VERSION ""

NS_ :

BS_:

BU_:

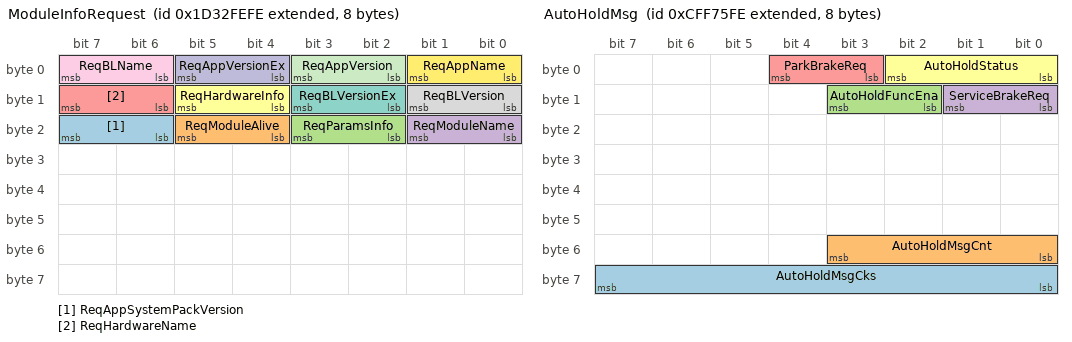
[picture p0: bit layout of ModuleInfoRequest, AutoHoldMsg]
BO_ 2637364990 ModuleInfoRequest: 8 Host
 SG_ ReqAppSystemPackVersion : 22|2@1+ (1,0) [0|0] "" Vector__XXX
 SG_ ReqModuleAlive : 20|2@1+ (1,0) [0|0] "" Vector__XXX
 SG_ ReqParamsInfo : 18|2@1+ (1,0) [0|0] "" Vector__XXX
 SG_ ReqModuleName : 16|2@1+ (1,0) [0|0] "" Vector__XXX
 SG_ ReqHardwareName : 14|2@1+ (1,0) [0|0] "" Vector__XXX
 SG_ ReqHardwareInfo : 12|2@1+ (1,0) [0|0] "" Vector__XXX
 SG_ ReqBLVersionEx : 10|2@1+ (1,0) [0|0] "" Vector__XXX
 SG_ ReqBLVersion : 8|2@1+ (1,0) [0|0] "" Vector__XXX
 SG_ ReqBLName : 6|2@1+ (1,0) [0|0] "" Vector__XXX
 SG_ ReqAppVersionEx : 4|2@1+ (1,0) [0|0] "" Vector__XXX
 SG_ ReqAppVersion : 2|2@1+ (1,0) [0|0] "" Vector__XXX
 SG_ ReqAppName : 0|2@1+ (1,0) [0|0] "" Vector__XXX

BO_ 2583174654 WPRWSH_WiperFeedback: 1 Vector__XXX
 SG_ WiperState : 1|3@1+ (1,0) [0|7] "" Vector__XXX
 SG_ WiperHomePosition : 0|1@1+ (1,0) [0|1] "" Vector__XXX

BO_ 2365552126 AutoHoldMsg: 8 Vector__XXX
 SG_ AutoHoldMsgCks : 56|8@1+ (1,0) [0|255] "" Vector__XXX
 SG_ AutoHoldMsgCnt : 48|4@1+ (1,0) [0|15] "" Vector__XXX
 SG_ AutoHoldFuncEna : 10|2@1+ (1,0) [0|3] "" Vector__XXX
 SG_ ServiceBrakeReq : 8|2@1+ (1,0) [0|3] "" Vector__XXX
 SG_ ParkBrakeReq : 3|2@1+ (1,0) [0|3] "" Vector__XXX
 SG_ AutoHoldStatus : 0|3@1+ (1,0) [0|4] "" Vector__XXX

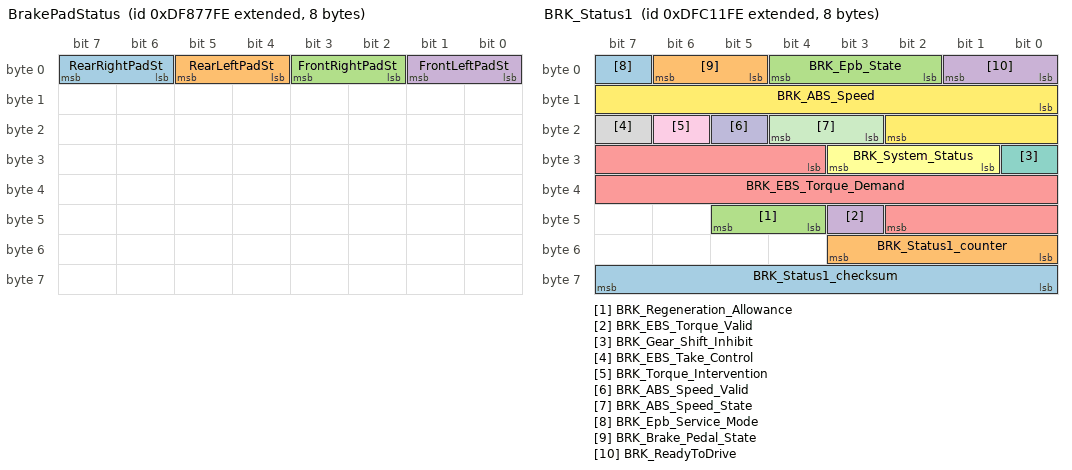
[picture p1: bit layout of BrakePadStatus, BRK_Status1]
BO_ 2381871102 BrakePadStatus: 8 Vector__XXX
 SG_ RearRightPadSt : 6|2@1+ (1,0) [0|3] "" Vector__XXX
 SG_ RearLeftPadSt : 4|2@1+ (1,0) [0|3] "" Vector__XXX
 SG_ FrontRightPadSt : 2|2@1+ (1,0) [0|3] "" Vector__XXX
 SG_ FrontLeftPadSt : 0|2@1+ (1,0) [0|3] "" Vector__XXX

BO_ 2382107134 BRK_Status1: 8 Vector__XXX
 SG_ BRK_Status1_checksum : 56|8@1+ (1,0) [0|255] "" Vector__XXX
 SG_ BRK_Status1_counter : 48|4@1+ (1,0) [0|15] "" Vector__XXX
 SG_ BRK_Regeneration_Allowance : 44|2@1+ (1,0) [0|3] "" Vector__XXX
 SG_ BRK_EBS_Torque_Valid : 43|1@1+ (1,0) [0|0] "" Vector__XXX
 SG_ BRK_EBS_Torque_Demand : 28|15@1+ (0.1,0) [0|3276.7] "N*m" Vector__XXX
 SG_ BRK_System_Status : 25|3@1+ (1,0) [0|7] "" Vector__XXX
 SG_ BRK_Gear_Shift_Inhibit : 24|1@1+ (1,0) [0|1] "" Vector__XXX
 SG_ BRK_EBS_Take_Control : 23|1@1+ (1,0) [0|1] "" Vector__XXX
 SG_ BRK_Torque_Intervention : 22|1@1+ (1,0) [0|1] "" Vector__XXX
 SG_ BRK_ABS_Speed_Valid : 21|1@1+ (1,0) [0|1] "" Vector__XXX
 SG_ BRK_ABS_Speed_State : 19|2@1+ (1,0) [0|3] "" Vector__XXX
 SG_ BRK_ABS_Speed : 8|11@1+ (0.125,0) [0|255] "kph" Vector__XXX
 SG_ BRK_Epb_Service_Mode : 7|1@1+ (1,0) [0|1] "" Vector__XXX
 SG_ BRK_Brake_Pedal_State : 5|2@1+ (1,0) [0|3] "" Vector__XXX
 SG_ BRK_Epb_State : 2|3@1+ (1,0) [0|7] "" Vector__XXX
 SG_ BRK_ReadyToDrive : 0|2@1+ (1,0) [0|3] "" Vector__XXX

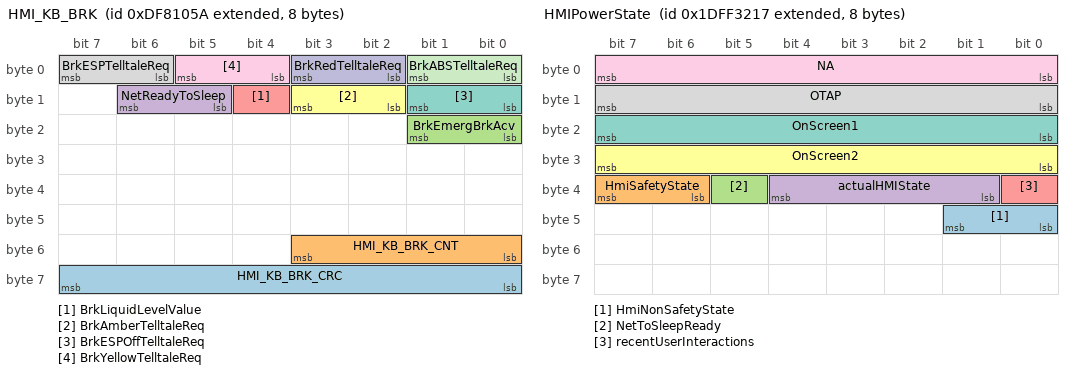
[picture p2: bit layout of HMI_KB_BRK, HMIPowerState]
BO_ 2381844570 HMI_KB_BRK: 8 Vector__XXX
 SG_ HMI_KB_BRK_CRC : 56|8@1+ (1,0) [0|255] "" Vector__XXX
 SG_ HMI_KB_BRK_CNT : 48|4@1+ (1,0) [0|15] "" Vector__XXX
 SG_ BrkEmergBrkAcv : 16|2@1+ (1,0) [0|3] "" Vector__XXX
 SG_ NetReadyToSleep : 13|2@1+ (1,0) [0|3] "" Vector__XXX
 SG_ BrkLiquidLevelValue : 12|1@1+ (1,0) [0|1] "" Vector__XXX
 SG_ BrkAmberTelltaleReq : 10|2@1+ (1,0) [0|0] "" Vector__XXX
 SG_ BrkESPOffTelltaleReq : 8|2@1+ (1,0) [0|0] "" Vector__XXX
 SG_ BrkESPTelltaleReq : 6|2@1+ (1,0) [0|0] "" Vector__XXX
 SG_ BrkYellowTelltaleReq : 4|2@1+ (1,0) [0|0] "" Vector__XXX
 SG_ BrkRedTelltaleReq : 2|2@1+ (1,0) [0|0] "" Vector__XXX
 SG_ BrkABSTelltaleReq : 0|2@1+ (1,0) [0|0] "" Vector__XXX

BO_ 2650747415 HMIPowerState: 8 InstrumentalCluster
 SG_ HmiNonSafetyState : 40|2@1+ (1,0) [0|3] "" Vector__XXX
 SG_ HmiSafetyState : 38|2@1+ (1,0) [0|3] "" Vector__XXX
 SG_ NetToSleepReady : 37|1@1+ (1,0) [0|1] "" Vector__XXX
 SG_ actualHMIState : 33|4@1+ (1,0) [0|15] "" Vector__XXX
 SG_ recentUserInteractions : 32|1@1+ (1,0) [0|1] "" Vector__XXX
 SG_ OnScreen2 : 24|8@1+ (1,0) [0|1] "" Vector__XXX
 SG_ OnScreen1 : 16|8@1+ (1,0) [0|1] "" Vector__XXX
 SG_ OTAP : 8|8@1+ (1,0) [0|1] "" Vector__XXX
 SG_ NA : 0|8@1+ (1,0) [0|1] "" Vector__XXX

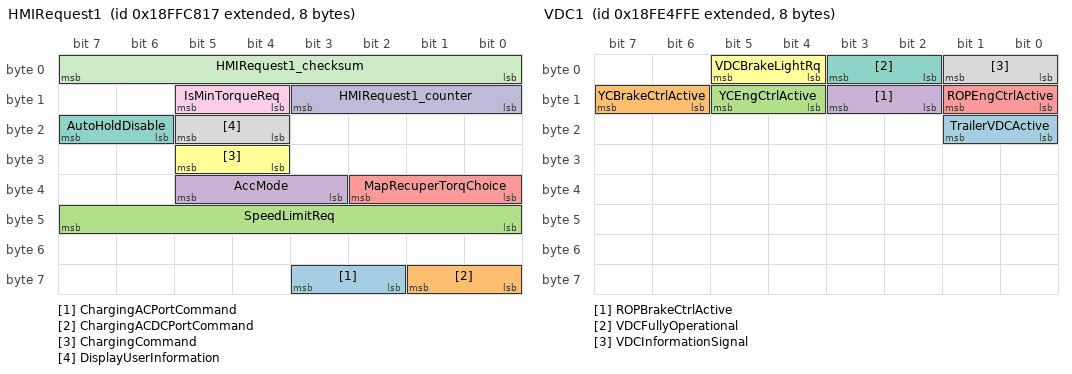
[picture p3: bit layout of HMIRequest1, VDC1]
BO_ 2566899735 HMIRequest1: 8 InstrumentCluster
 SG_ ChargingACPortCommand : 58|2@1+ (1,0) [0|3] "" Vector__XXX
 SG_ ChargingACDCPortCommand : 56|2@1+ (1,0) [0|3] "" Vector__XXX
 SG_ SpeedLimitReq : 40|8@1+ (1,0) [0|0] "kph" Vector__XXX
 SG_ AccMode : 35|3@1+ (1,0) [0|7] "" Vector__XXX
 SG_ MapRecuperTorqChoice : 32|3@1+ (1,0) [0|0] "" Vector__XXX
 SG_ ChargingCommand : 28|2@1+ (1,0) [0|3] "" Vector__XXX
 SG_ AutoHoldDisable : 22|2@1+ (1,0) [0|3] "" Vector__XXX
 SG_ DisplayUserInformation : 20|2@1+ (1,0) [0|3] "" Vector__XXX
 SG_ IsMinTorqueReq : 12|2@1+ (1,0) [0|3] "" Vector__XXX
 SG_ HMIRequest1_counter : 8|4@1+ (1,0) [0|14] "" Vector__XXX
 SG_ HMIRequest1_checksum : 0|8@1+ (1,0) [0|255] "" Vector__XXX

BO_ 2566803454 VDC1: 8 Vector__XXX
 SG_ TrailerVDCActive : 16|2@1+ (1,0) [0|3] "" Vector__XXX
 SG_ YCBrakeCtrlActive : 14|2@1+ (1,0) [0|3] "" Vector__XXX
 SG_ YCEngCtrlActive : 12|2@1+ (1,0) [0|3] "" Vector__XXX
 SG_ ROPBrakeCtrlActive : 10|2@1+ (1,0) [0|3] "" Vector__XXX
 SG_ ROPEngCtrlActive : 8|2@1+ (1,0) [0|3] "" Vector__XXX
 SG_ VDCBrakeLightRq : 4|2@1+ (1,0) [0|3] "" Vector__XXX
 SG_ VDCFullyOperational : 2|2@1+ (1,0) [0|3] "" Vector__XXX
 SG_ VDCInformationSignal : 0|2@1+ (1,0) [0|3] "" Vector__XXX

BO_ 2399125758 CommVSMRequest: 8 Vector__XXX
 SG_ LVUpdateOTARequest : 6|3@1+ (1,0) [0|7] "" Vector__XXX
 SG_ OTAUpdateRequest : 3|3@1+ (1,0) [0|7] "" Vector__XXX
 SG_ DiagnosticRequest : 0|3@1+ (1,0) [0|7] "" Vector__XXX

BO_ 2381722110 ELSTS: 1 Vector__XXX
 SG_ ELSReadyToSleep : 3|2@1+ (1,0) [0|3] "" Vector__XXX
 SG_ LampState : 0|3@1+ (1,0) [0|7] "" Vector__XXX

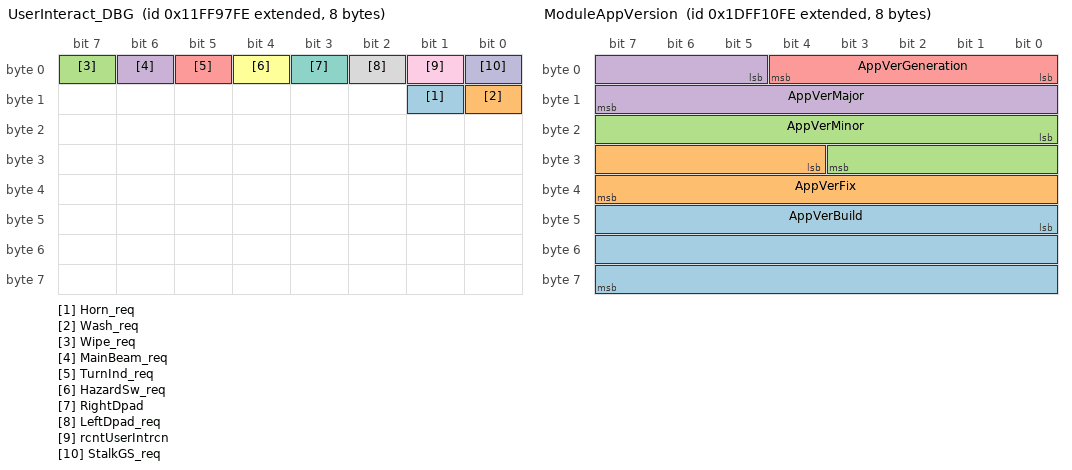
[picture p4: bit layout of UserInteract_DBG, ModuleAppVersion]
BO_ 2449446910 UserInteract_DBG: 8 Vector__XXX
 SG_ Horn_req : 9|1@1+ (1,0) [0|1] "" Vector__XXX
 SG_ Wash_req : 8|1@1+ (1,0) [0|1] "" Vector__XXX
 SG_ Wipe_req : 7|1@1+ (1,0) [0|1] "" Vector__XXX
 SG_ MainBeam_req : 6|1@1+ (1,0) [0|1] "" Vector__XXX
 SG_ TurnInd_req : 5|1@1+ (1,0) [0|1] "" Vector__XXX
 SG_ HazardSw_req : 4|1@1+ (1,0) [0|1] "" Vector__XXX
 SG_ RightDpad : 3|1@1+ (1,0) [0|1] "" Vector__XXX
 SG_ LeftDpad_req : 2|1@1+ (1,0) [0|1] "" Vector__XXX
 SG_ rcntUserIntrcn : 1|1@1+ (1,0) [0|1] "" Vector__XXX
 SG_ StalkGS_req : 0|1@1+ (1,0) [0|1] "" Vector__XXX

BO_ 2650738942 ModuleAppVersion: 8 Device
 SG_ AppVerBuild : 40|24@1+ (1,0) [0|16777215] "" Vector__XXX
 SG_ AppVerFix : 28|12@1+ (1,0) [0|4090] "" Vector__XXX
 SG_ AppVerMinor : 16|12@1+ (1,0) [0|4095] "" Vector__XXX
 SG_ AppVerMajor : 5|11@1+ (1,0) [0|2047] "" Vector__XXX
 SG_ AppVerGeneration : 0|5@1+ (1,0) [0|31] "" Vector__XXX

BO_ 2466225918 HMIUserInteract: 8 Vector__XXX
 SG_ RecentUserInteract : 0|1@1+ (1,0) [0|1] "" Vector__XXX

BO_ 2600457470 NM_DEBUG_OUT_1: 8 Vector__XXX
 SG_ NM_Wakeup_Sys22 : 40|1@1+ (1,0) [0|1] "" Vector__XXX
 SG_ NM_Wakeup_Sys21 : 39|1@1+ (1,0) [0|1] "" Vector__XXX
 SG_ NM_Wakeup_Sys14 : 38|1@1+ (1,0) [0|1] "" Vector__XXX
 SG_ NM_Wakeup_Sys12 : 37|1@1+ (1,0) [0|1] "" Vector__XXX
 SG_ NM_Wakeup_Sys7 : 36|1@1+ (1,0) [0|1] "" Vector__XXX
 SG_ NM_Wakeup_Sys6 : 35|1@1+ (1,0) [0|1] "" Vector__XXX
 SG_ NM_Wakeup_Sys5 : 34|1@1+ (1,0) [0|1] "" Vector__XXX
 SG_ NM_Wakeup_Sys3 : 33|1@1+ (1,0) [0|1] "" Vector__XXX
 SG_ NM_Wakeup_Sys1 : 32|1@1+ (1,0) [0|1] "" Vector__XXX
 SG_ NM_Ready2Sleep_Sys15 : 30|1@1+ (1,0) [0|1] "" Vector__XXX
 SG_ NM_Ready2Sleep_Sys14 : 29|1@1+ (1,0) [0|1] "" Vector__XXX
 SG_ NM_Ready2Sleep_Sys13 : 28|1@1+ (1,0) [0|1] "" Vector__XXX
 SG_ NM_Ready2Sleep_Sys12 : 27|1@1+ (1,0) [0|1] "" Vector__XXX
 SG_ NM_Ready2Sleep_Sys11 : 26|1@1+ (1,0) [0|1] "" Vector__XXX
 SG_ NM_Ready2Sleep_Sys10 : 25|1@1+ (1,0) [0|1] "" Vector__XXX
 SG_ NM_Ready2Sleep_Sys9 : 24|1@1+ (1,0) [0|1] "" Vector__XXX
 SG_ NM_Ready2Sleep_Sys8 : 23|1@1+ (1,0) [0|1] "" Vector__XXX
 SG_ NM_Ready2Sleep_Sys7 : 22|1@1+ (1,0) [0|1] "" Vector__XXX
 SG_ NM_Ready2Sleep_Sys6 : 21|1@1+ (1,0) [0|1] "" Vector__XXX
 SG_ NM_Ready2Sleep_Sys5 : 20|1@1+ (1,0) [0|1] "" Vector__XXX
 SG_ NM_Ready2Sleep_Sys4 : 19|1@1+ (1,0) [0|1] "" Vector__XXX
 SG_ NM_Ready2Sleep_Sys3 : 18|1@1+ (1,0) [0|1] "" Vector__XXX
 SG_ NM_Ready2Sleep_Sys2 : 17|1@1+ (1,0) [0|1] "" Vector__XXX
 SG_ NM_Ready2Sleep_Sys1 : 16|1@1+ (1,0) [0|1] "" Vector__XXX
 SG_ NM_VSMFullySleep : 13|1@1+ (1,0) [0|1] "" Vector__XXX
 SG_ NM_MNG_ShtDwnTimer : 12|1@1+ (1,0) [0|1] "" Vector__XXX
 SG_ NM_MNG_ShtDwnSysRdy : 11|1@1+ (1,0) [0|1] "" Vector__XXX
 SG_ NM_IsSpdOk : 10|1@1+ (1,0) [0|0] "" Vector__XXX
 SG_ NM_IsHWOk : 9|1@1+ (1,0) [0|0] "" Vector__XXX
 SG_ NM_Ready2Sleep_Inv : 8|1@1+ (1,0) [0|1] "" Vector__XXX
 SG_ NM_BoardShutDown : 7|1@1+ (1,0) [0|0] "" Vector__XXX
 SG_ NM_NTWKTaskStatus : 5|2@1+ (1,0) [0|0] "" Vector__XXX
 SG_ NM_SlaveSleepCmd : 4|1@1+ (1,0) [0|0] "" Vector__XXX
 SG_ NM_SlaveWakeupCmd : 3|1@1+ (1,0) [0|0] "" Vector__XXX
 SG_ NM_SleepCmd_BMS : 2|1@1+ (1,0) [0|0] "" Vector__XXX
 SG_ NM_MNGR_VSMNtwkReq : 0|2@1+ (1,0) [0|3] "" Vector__XXX

BO_ 2600457726 NM_DEBUG_OUT_2: 8 Vector__XXX
 SG_ NM_SlaveWakeUpCmd_RRIO2 : 56|1@1+ (1,0) [0|1] "" Vector__XXX
 SG_ NM_SlaveWakeUpCmd_RRIO1 : 55|1@1+ (1,0) [0|1] "" Vector__XXX
 SG_ NM_SlaveWakeUpCmd_CBIO3 : 54|1@1+ (1,0) [0|1] "" Vector__XXX
 SG_ NM_SlaveWakeUpCmd_CBIO2 : 53|1@1+ (1,0) [0|1] "" Vector__XXX
 SG_ NM_SlaveWakeUpCmd_CBIO1 : 52|1@1+ (1,0) [0|1] "" Vector__XXX
 SG_ NM_SlaveWakeUpCmd_FBIO4 : 51|1@1+ (1,0) [0|1] "" Vector__XXX
 SG_ NM_SlaveWakeUpCmd_FBIO2 : 50|1@1+ (1,0) [0|1] "" Vector__XXX
 SG_ NM_SlaveWakeUpCmd_FBIO1 : 49|1@1+ (1,0) [0|1] "" Vector__XXX
 SG_ NM_SlaveWakeUpCmd_BMS : 48|1@1+ (1,0) [0|1] "" Vector__XXX
 SG_ NM_SlaveWakeUpCmd_COMM : 47|1@1+ (1,0) [0|1] "" Vector__XXX
 SG_ NM_SlaveWakeUpCmd_ARVLCC : 46|1@1+ (1,0) [0|1] "" Vector__XXX
 SG_ NM_SlaveWakeUpCmd_STPCSD : 45|1@1+ (1,0) [0|1] "" Vector__XXX
 SG_ NM_SlaveWakeUpCmd_STPCBD : 44|1@1+ (1,0) [0|1] "" Vector__XXX
 SG_ NM_SlaveWakeUpCmd_STPRD : 43|1@1+ (1,0) [0|1] "" Vector__XXX
 SG_ NM_SlaveWakeUpCmd_STPLD : 42|1@1+ (1,0) [0|1] "" Vector__XXX
 SG_ NM_SlaveWakeUpCmd_AVAS : 41|1@1+ (1,0) [0|1] "" Vector__XXX
 SG_ NM_SlaveWakeUpCmd_FBIO3 : 40|1@1+ (1,0) [0|1] "" Vector__XXX
 SG_ NM_SlaveWakeUpCmd_HMI : 39|1@1+ (1,0) [0|1] "" Vector__XXX
 SG_ NM_SlaveWakeUpCmd_IDU : 38|1@1+ (1,0) [0|1] "" Vector__XXX
 SG_ NM_SlaveSleepCmd_RRIO2 : 37|1@1+ (1,0) [0|1] "" Vector__XXX
 SG_ NM_SlaveSleepCmd_RRIO1 : 36|1@1+ (1,0) [0|1] "" Vector__XXX
 SG_ NM_SlaveSleepCmd_CBIO3 : 35|1@1+ (1,0) [0|1] "" Vector__XXX
 SG_ NM_SlaveSleepCmd_CBIO2 : 34|1@1+ (1,0) [0|1] "" Vector__XXX
 SG_ NM_SlaveSleepCmd_CBIO1 : 33|1@1+ (1,0) [0|1] "" Vector__XXX
 SG_ NM_SlaveSleepCmd_FBIO4 : 32|1@1+ (1,0) [0|1] "" Vector__XXX
 SG_ NM_SlaveSleepCmd_FBIO2 : 31|1@1+ (1,0) [0|1] "" Vector__XXX
 SG_ NM_SlaveSleepCmd_FBIO1 : 30|1@1+ (1,0) [0|1] "" Vector__XXX
 SG_ NM_SlaveSleepCmd_BMS : 29|1@1+ (1,0) [0|1] "" Vector__XXX
 SG_ NM_SlaveSleepCmd_COMM : 28|1@1+ (1,0) [0|1] "" Vector__XXX
 SG_ NM_SlaveSleepCmd_ARVLCC : 27|1@1+ (1,0) [0|1] "" Vector__XXX
 SG_ NM_SlaveSleepCmd_STPCSD : 26|1@1+ (1,0) [0|1] "" Vector__XXX
 SG_ NM_SlaveSleepCmd_STPCBD : 25|1@1+ (1,0) [0|1] "" Vector__XXX
 SG_ NM_SlaveSleepCmd_STPRD : 24|1@1+ (1,0) [0|1] "" Vector__XXX
 SG_ NM_SlaveSleepCmd_STPLD : 23|1@1+ (1,0) [0|1] "" Vector__XXX
 SG_ NM_SlaveSleepCmd_AVAS : 22|1@1+ (1,0) [0|1] "" Vector__XXX
 SG_ NM_SlaveSleepCmd_FBIO3 : 21|1@1+ (1,0) [0|1] "" Vector__XXX
 SG_ NM_SlaveSleepCmd_HMI : 20|1@1+ (1,0) [0|1] "" Vector__XXX
 SG_ NM_SlaveSleepCmd_IDU : 19|1@1+ (1,0) [0|1] "" Vector__XXX
 SG_ NM_NodesAlive_RRIO2 : 18|1@1+ (1,0) [0|1] "" Vector__XXX
 SG_ NM_NodesAlive_RRIO1 : 17|1@1+ (1,0) [0|1] "" Vector__XXX
 SG_ NM_NodesAlive_CBIO3 : 16|1@1+ (1,0) [0|1] "" Vector__XXX
 SG_ NM_NodesAlive_CBIO2 : 15|1@1+ (1,0) [0|1] "" Vector__XXX
 SG_ NM_NodesAlive_CBIO1 : 14|1@1+ (1,0) [0|1] "" Vector__XXX
 SG_ NM_NodesAlive_FBIO4 : 13|1@1+ (1,0) [0|1] "" Vector__XXX
 SG_ NM_NodesAlive_FBIO2 : 12|1@1+ (1,0) [0|1] "" Vector__XXX
 SG_ NM_NodesAlive_FBIO1 : 11|1@1+ (1,0) [0|1] "" Vector__XXX
 SG_ NM_NodesAlive_BMS : 10|1@1+ (1,0) [0|1] "" Vector__XXX
 SG_ NM_NodesAlive_COMM : 9|1@1+ (1,0) [0|1] "" Vector__XXX
 SG_ NM_NodesAlive_ARVLCC : 8|1@1+ (1,0) [0|1] "" Vector__XXX
 SG_ NM_NodesAlive_STPCSD : 7|1@1+ (1,0) [0|1] "" Vector__XXX
 SG_ NM_NodesAlive_STPCBD : 6|1@1+ (1,0) [0|1] "" Vector__XXX
 SG_ NM_NodesAlive_STPRD : 5|1@1+ (1,0) [0|1] "" Vector__XXX
 SG_ NM_NodesAlive_STPLD : 4|1@1+ (1,0) [0|1] "" Vector__XXX
 SG_ NM_NodesAlive_AVAS : 3|1@1+ (1,0) [0|1] "" Vector__XXX
 SG_ NM_NodesAlive_FBIO3 : 2|1@1+ (1,0) [0|1] "" Vector__XXX
 SG_ NM_NodesAlive_HMI : 1|1@1+ (1,0) [0|1] "" Vector__XXX
 SG_ NM_NodesAlive_IDU : 0|1@1+ (1,0) [0|1] "" Vector__XXX

BO_ 2600457982 NM_DEBUG_OUT_3: 8 Vector__XXX
 SG_ NM_DBG_VehSpeed : 8|32@1+ (1,0) [0|4294967295] "" Vector__XXX
 SG_ NM_DBG_VSMSubstate : 3|3@1+ (1,0) [0|7] "" Vector__XXX
 SG_ NM_DBG_VSMState : 0|3@1+ (1,0) [0|7] "" Vector__XXX

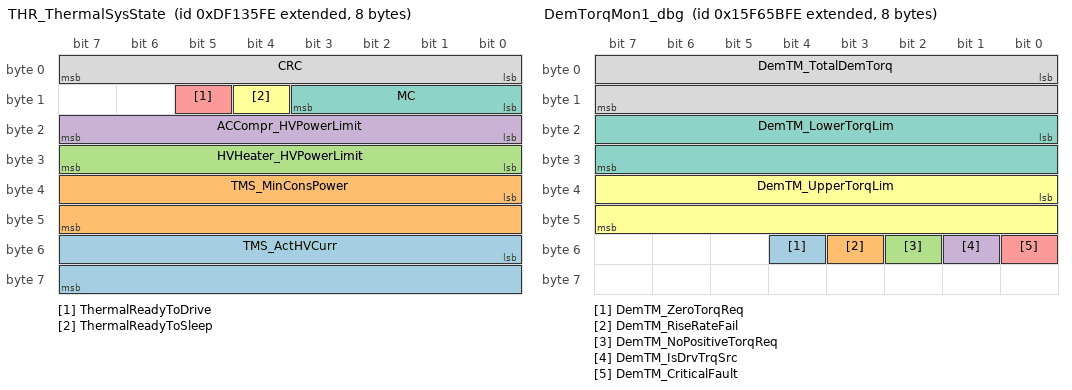
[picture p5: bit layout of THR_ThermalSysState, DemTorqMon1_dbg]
BO_ 2381395454 THR_ThermalSysState: 8 Vector__XXX
 SG_ TMS_ActHVCurr : 48|16@1+ (0.05,0) [0|3276.75] "A" Vector__XXX
 SG_ TMS_MinConsPower : 32|16@1+ (0.1,0) [0|6553.5] "kW" Vector__XXX
 SG_ HVHeater_HVPowerLimit : 24|8@1+ (0.1,0) [0|25.5] "kW" Vector__XXX
 SG_ ACCompr_HVPowerLimit : 16|8@1+ (0.1,0) [0|25.5] "kW" Vector__XXX
 SG_ ThermalReadyToDrive : 13|1@1+ (1,0) [0|1] "" Vector__XXX
 SG_ ThermalReadyToSleep : 12|1@1+ (1,0) [0|1] "" Vector__XXX
 SG_ MC : 8|4@1+ (1,0) [0|0] "" Vector__XXX
 SG_ CRC : 0|8@1+ (1,0) [0|0] "" Vector__XXX

BO_ 2650742782 MaintenanceStatus: 8 Host
 SG_ DiagReportsEnabled : 2|2@1+ (1,0) [0|0] "" Vector__XXX
 SG_ FirmwareUpdateEnabled : 0|2@1+ (1,0) [0|0] "" Vector__XXX

BO_ 2600459518 VSM_DEBUG_OUT_2: 8 Vector__XXX
 SG_ VSM_OTA_Step : 0|5@1+ (1,1) [1|32] "" Vector__XXX

BO_ 2515951358 ActTorqMon1_dbg: 8 Vector__XXX
 SG_ ActTM_UpperTorqLim : 48|16@1+ (1,-32267) [-32267|33268] "" Vector__XXX
 SG_ ActTM_LowerTorqLim : 32|16@1+ (1,-32267) [-32267|33268] "" Vector__XXX
 SG_ ActTM_DemTorque : 16|16@1+ (1,-32267) [-32267|33268] "" Vector__XXX
 SG_ ActTM_ActTorque : 0|16@1+ (1,-32267) [-32267|33268] "" Vector__XXX

BO_ 2515951102 ActTorqMon2_dbg: 8 Vector__XXX
 SG_ ActTM_ExcTime : 32|16@1+ (1,0) [0|65535] "" Vector__XXX
 SG_ ActTM_FiltTorqRiseRate : 16|16@1+ (1,-32267) [-32267|33268] "" Vector__XXX
 SG_ ActTM_MotSpeedRPM : 0|16@1+ (1,-32267) [-32267|33268] "" Vector__XXX

BO_ 2515950846 BrkTorqMon_dbg: 8 Vector__XXX
 SG_ BrkTM_BrkTorqFault0 : 16|1@1+ (1,0) [0|1] "" Vector__XXX
 SG_ BrkTM_EBSTorqDem : 0|16@1+ (1,-32267) [-32267|33268] "" Vector__XXX

BO_ 2180407550 DCUHMI: 8 Vector__XXX
 SG_ DCUHMIMsgCks : 56|8@1+ (1,0) [0|255] "" Vector__XXX
 SG_ DCUHMIMsgCtr : 48|4@1+ (1,0) [0|15] "" Vector__XXX
 SG_ GearBox_FltSts : 3|2@1+ (1,0) [0|3] "" Vector__XXX
 SG_ DTS_DriverWarn : 0|3@1+ (1,0) [0|7] "" Vector__XXX

BO_ 2515950590 DemTorqMon1_dbg: 8 Vector__XXX
 SG_ DemTM_ZeroTorqReq : 52|1@1+ (1,0) [0|1] "" Vector__XXX
 SG_ DemTM_RiseRateFail : 51|1@1+ (1,0) [0|1] "" Vector__XXX
 SG_ DemTM_NoPositiveTorqReq : 50|1@1+ (1,0) [0|1] "" Vector__XXX
 SG_ DemTM_IsDrvTrqSrc : 49|1@1+ (1,0) [0|1] "" Vector__XXX
 SG_ DemTM_CriticalFault : 48|1@1+ (1,0) [0|1] "" Vector__XXX
 SG_ DemTM_UpperTorqLim : 32|16@1+ (1,-32267) [-32267|33268] "" Vector__XXX
 SG_ DemTM_LowerTorqLim : 16|16@1+ (1,-32267) [-32267|33268] "" Vector__XXX
 SG_ DemTM_TotalDemTorq : 0|16@1+ (1,-32267) [-32267|33268] "" Vector__XXX

BO_ 2515950334 DemTorqMon2_dbg: 8 Vector__XXX
 SG_ DemTM_UpperTorqLim_tab : 16|16@1+ (1,-32267) [-32267|33268] "" Vector__XXX
 SG_ DemTM_LowerTorqLim_tab : 0|16@1+ (1,-32267) [-32267|33268] "" Vector__XXX

BO_ 2515950078 DemTorqMon3_dbg: 8 Vector__XXX
 SG_ DemTM_ExcTime : 32|16@1+ (1,0) [0|65535] "" Vector__XXX
 SG_ DemTM_MaxTorqRiseRate : 16|16@1+ (1,-32267) [-32267|33268] "" Vector__XXX
 SG_ DemTM_FiltTorqRiseRate : 0|16@1+ (1,-32267) [-32267|33268] "" Vector__XXX

BO_ 2381867518 DT_States: 8 Vector__XXX
 SG_ DT_States_checksum : 56|8@1+ (1,0) [0|255] "" Vector__XXX
 SG_ DT_States_counter : 48|4@1+ (1,0) [0|15] "" Vector__XXX
 SG_ DTReadyToSleep : 2|1@1+ (1,0) [0|1] "" Vector__XXX
 SG_ DTReadyToDrive : 0|2@1+ (1,0) [0|3] "" Vector__XXX

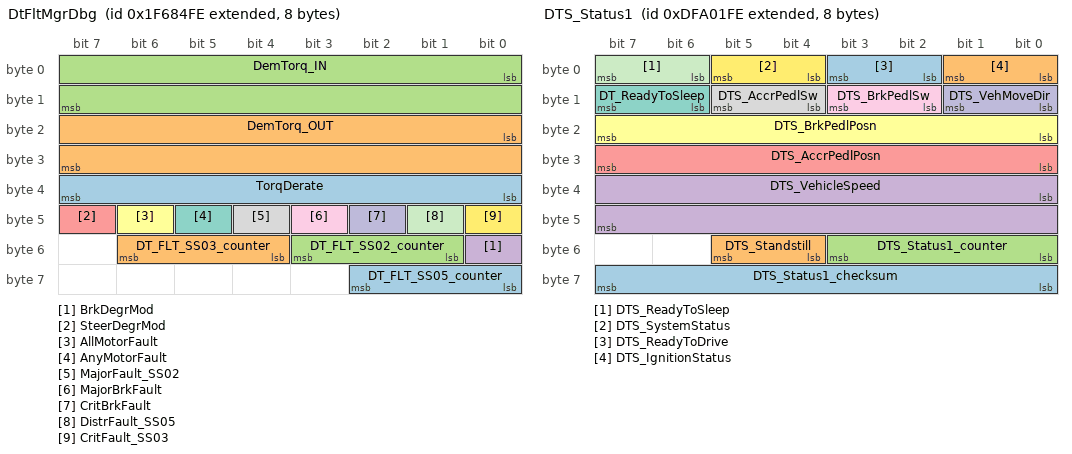
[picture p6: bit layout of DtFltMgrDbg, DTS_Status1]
BO_ 2180416766 DtFltMgrDbg: 8 Vector__XXX
 SG_ DT_FLT_SS05_counter : 56|3@1+ (1,0) [0|7] "" Vector__XXX
 SG_ DT_FLT_SS03_counter : 52|3@1+ (1,0) [0|7] "" Vector__XXX
 SG_ DT_FLT_SS02_counter : 49|3@1+ (1,0) [0|7] "" Vector__XXX
 SG_ BrkDegrMod : 48|1@1+ (1,0) [0|1] "" Vector__XXX
 SG_ SteerDegrMod : 47|1@1+ (1,0) [0|1] "" Vector__XXX
 SG_ AllMotorFault : 46|1@1+ (1,0) [0|1] "" Vector__XXX
 SG_ AnyMotorFault : 45|1@1+ (1,0) [0|1] "" Vector__XXX
 SG_ MajorFault_SS02 : 44|1@1+ (1,0) [0|1] "" Vector__XXX
 SG_ MajorBrkFault : 43|1@1+ (1,0) [0|1] "" Vector__XXX
 SG_ CritBrkFault : 42|1@1+ (1,0) [0|1] "" Vector__XXX
 SG_ DistrFault_SS05 : 41|1@1+ (1,0) [0|1] "" Vector__XXX
 SG_ CritFault_SS03 : 40|1@1+ (1,0) [0|1] "" Vector__XXX
 SG_ TorqDerate : 32|8@1+ (0.004,0) [0|1.02] "" Vector__XXX
 SG_ DemTorq_OUT : 16|16@1+ (1,-32768) [-32768|32767] "" Vector__XXX
 SG_ DemTorq_IN : 0|16@1+ (1,-32768) [-32768|32767] "" Vector__XXX

BO_ 2381971966 DTS_Status1: 8 Vector__XXX
 SG_ DTS_Status1_checksum : 56|8@1+ (1,0) [0|255] "" Vector__XXX
 SG_ DTS_Standstill : 52|2@1+ (1,0) [0|3] "" Vector__XXX
 SG_ DTS_Status1_counter : 48|4@1+ (1,0) [0|15] "" Vector__XXX
 SG_ DTS_VehicleSpeed : 32|16@1+ (0.01,-300) [-300|355.35] "km/h" Vector__XXX
 SG_ DTS_AccrPedlPosn : 24|8@1+ (0.4,0) [0|102] "%" Vector__XXX
 SG_ DTS_BrkPedlPosn : 16|8@1+ (0.5,0) [0|127.5] "%" Vector__XXX
 SG_ DT_ReadyToSleep : 14|2@1+ (1,0) [0|3] "" Vector__XXX
 SG_ DTS_AccrPedlSw : 12|2@1+ (1,0) [0|3] "" Vector__XXX
 SG_ DTS_BrkPedlSw : 10|2@1+ (1,0) [0|3] "" Vector__XXX
 SG_ DTS_VehMoveDir : 8|2@1+ (1,0) [0|3] "" Vector__XXX
 SG_ DTS_ReadyToSleep : 6|2@1+ (1,0) [0|3] "" Vector__XXX
 SG_ DTS_SystemStatus : 4|2@1+ (1,0) [0|3] "" Vector__XXX
 SG_ DTS_ReadyToDrive : 2|2@1+ (1,0) [0|3] "" Vector__XXX
 SG_ DTS_IgnitionStatus : 0|2@1+ (1,0) [0|3] "" Vector__XXX

BO_ 2381972734 DTS_Status4: 8 Vector__XXX
 SG_ DTS_Status4_checksum : 56|8@1+ (1,0) [0|255] "" Vector__XXX
 SG_ DTS_Status4_counter : 48|4@1+ (1,0) [0|15] "" Vector__XXX
 SG_ DTS_MotorTorque : 16|16@1+ (0.1,-3276.8) [-3276.8|3276.7] "Nm" Vector__XXX
 SG_ DTS_MotorSpeed : 0|16@1+ (1,-32768) [-32768|32767] "rpm" Vector__XXX

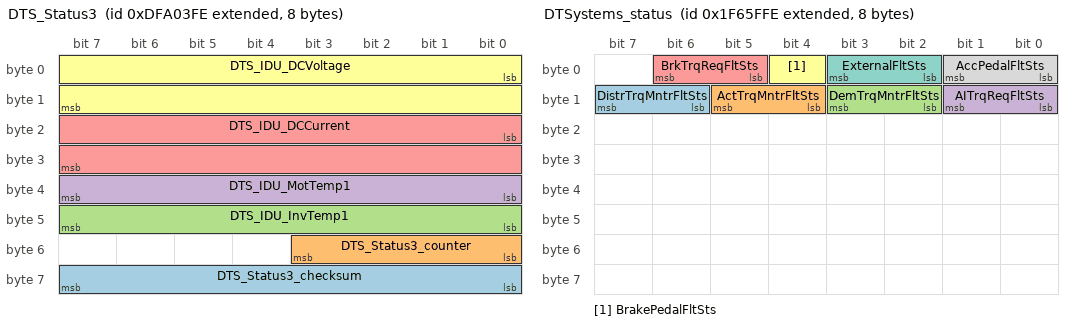
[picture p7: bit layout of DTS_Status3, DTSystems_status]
BO_ 2381972478 DTS_Status3: 8 Vector__XXX
 SG_ DTS_Status3_checksum : 56|8@1+ (1,0) [0|255] "" Vector__XXX
 SG_ DTS_Status3_counter : 48|4@1+ (1,0) [0|15] "" Vector__XXX
 SG_ DTS_IDU_InvTemp1 : 40|8@1+ (1,-40) [-40|215] "degC" Vector__XXX
 SG_ DTS_IDU_MotTemp1 : 32|8@1+ (1,-40) [-40|215] "degC" Vector__XXX
 SG_ DTS_IDU_DCCurrent : 16|16@1+ (0.1,-3276.8) [-3276.8|3276.7] "A" Vector__XXX
 SG_ DTS_IDU_DCVoltage : 0|16@1+ (0.02,0) [0|1310.7] "V" Vector__XXX

BO_ 2381972222 DTS_Status2: 8 Vector__XXX
 SG_ DTS_Status2_checksum : 56|8@1+ (1,0) [0|255] "" Vector__XXX
 SG_ DTS_Status2_counter : 48|4@1+ (1,0) [0|15] "" Vector__XXX
 SG_ DTS_Stalk_Request : 32|2@1+ (1,0) [0|3] "" Vector__XXX
 SG_ DTS_P_Button : 30|2@1+ (1,0) [0|3] "" Vector__XXX
 SG_ DTS_Stalk_GS_Input : 27|3@1+ (1,0) [0|6] "" Vector__XXX
 SG_ DTS_GS_Human_RND_Input : 24|3@1+ (1,0) [0|4] "" Vector__XXX
 SG_ DTS_GS_Human_P_Input : 22|2@1+ (1,0) [0|3] "" Vector__XXX
 SG_ DTS_IDU_DirectionSt : 20|2@1+ (1,0) [0|3] "" Vector__XXX
 SG_ DTS_IDU_DirectionCmd : 18|2@1+ (1,0) [0|3] "" Vector__XXX
 SG_ DTS_IDU_InterlockCmd : 16|2@1+ (1,0) [0|3] "" Vector__XXX
 SG_ DTS_ParkBrakeCmd : 14|2@1+ (1,0) [0|3] "" Vector__XXX
 SG_ DTS_ParkBrakeSt : 11|3@1+ (1,0) [0|7] "" Vector__XXX
 SG_ DTS_IDU_InterlockSt : 8|3@1+ (1,0) [0|7] "" Vector__XXX
 SG_ DTS_IDU_CommStatus : 7|1@1+ (1,0) [0|1] "" Vector__XXX
 SG_ DTS_IDU_ShortCirc : 5|2@1+ (1,0) [0|3] "" Vector__XXX
 SG_ DTS_IDU_HV_CheckState : 4|1@1+ (1,0) [0|1] "" Vector__XXX
 SG_ DTS_SysSt_ParkLock : 2|2@1+ (1,0) [0|3] "" Vector__XXX
 SG_ DTS_SysSt_IDU : 0|2@1+ (1,0) [0|3] "" Vector__XXX

BO_ 2180407294 DTSystems_status: 8 Vector__XXX
 SG_ DistrTrqMntrFltSts : 14|2@1+ (1,0) [0|3] "" Vector__XXX
 SG_ ActTrqMntrFltSts : 12|2@1+ (1,0) [0|3] "" Vector__XXX
 SG_ DemTrqMntrFltSts : 10|2@1+ (1,0) [0|3] "" Vector__XXX
 SG_ AITrqReqFltSts : 8|2@1+ (1,0) [0|3] "" Vector__XXX
 SG_ BrkTrqReqFltSts : 5|2@1+ (1,0) [0|3] "" Vector__XXX
 SG_ BrakePedalFltSts : 4|1@1+ (1,0) [0|1] "" Vector__XXX
 SG_ ExternalFltSts : 2|2@1+ (1,0) [0|3] "" Vector__XXX
 SG_ AccPedalFltSts : 0|2@1+ (1,0) [0|3] "" Vector__XXX

BO_ 2399110910 DVT_Debug_1: 8 Vector__XXX
 SG_ RSPDL_DT_OUT : 48|16@1+ (1,-32768) [-32768|32767] "Nm" Vector__XXX
 SG_ ORTL_DT_OUT : 32|16@1+ (1,-32768) [-32768|32767] "Nm" Vector__XXX
 SG_ DTF_DemTrq_OUT : 16|16@1+ (1,-32768) [-32768|32767] "Nm" Vector__XXX
 SG_ EBS_TorqueRequest : 0|16@1+ (1,-32768) [-32768|32767] "Nm" Vector__XXX

BO_ 2399111166 DVT_Debug_2: 8 Vector__XXX
 SG_ EPLC_ElPwrReqLim : 56|8@1+ (10,0) [0|2550] "kW" Vector__XXX
 SG_ EPLC_ElPwrDischLim : 48|8@1+ (10,0) [0|2550] "kW" Vector__XXX
 SG_ AccTR_TrqDem : 32|16@1+ (1,-32768) [-32768|32767] "N*m" Vector__XXX
 SG_ ARB_DT_DT : 16|16@1+ (1,-32768) [-32768|32767] "Nm" Vector__XXX
 SG_ ARB_DT_AI_TrqDem : 0|16@1- (1,0) [-32768|32767] "" Vector__XXX

BO_ 2399109630 DVT_Debug_3: 8 Vector__XXX
 SG_ DTF_TqLPF_TauTime : 40|8@1+ (0.01,0) [0|2.55] "sec" Vector__XXX
 SG_ DrRA_Acc_Req : 32|8@1+ (1,-100) [-100|100] "%" Vector__XXX
 SG_ DTF_TqRateLimDwn : 24|8@1+ (100,0) [0|25500] "Nm/s" Vector__XXX
 SG_ DTF_TqRateLimUp : 16|8@1+ (100,0) [0|25500] "Nm/s" Vector__XXX
 SG_ RPLIM_T_OUT : 0|16@1+ (1,-32768) [-32768|32767] "Nm" Vector__XXX

BO_ 2600438270 DVT_Diagnostics: 8 DVT_Cntrl
 SG_ DTF_TqLPFIsOn : 41|1@1+ (1,0) [0|0] "" Vector__XXX
 SG_ DTF_TqLimRateIsOn : 40|1@1+ (1,0) [0|0] "" Vector__XXX
 SG_ DTF_DiagWarning : 39|1@1+ (1,0) [0|0] "" Vector__XXX
 SG_ DTF_TqPreprocIsOn : 38|1@1+ (1,0) [0|0] "" Vector__XXX
 SG_ DrRA_MapChoiceFwdProc : 35|3@1+ (1,0) [0|7] "" Vector__XXX
 SG_ DrRA_RecChoiceProc : 32|3@1+ (1,0) [0|7] "" Vector__XXX
 SG_ ARB_DT_isTTAllow : 31|1@1+ (1,0) [0|0] "" Vector__XXX
 SG_ pedalProc_dbg : 28|3@1+ (1,0) [0|0] "" Vector__XXX
 SG_ ARB_DT_isRTAllow : 27|1@1+ (1,0) [0|0] "" Vector__XXX
 SG_ TTDerRPLim : 26|1@1+ (1,0) [0|0] "" Vector__XXX
 SG_ ARB_DT_TrqProhib : 25|1@1+ (1,0) [0|0] "" Vector__XXX
 SG_ TrqProactLim : 24|1@1+ (1,0) [0|0] "" Vector__XXX
 SG_ ARB_DT_isABS_valid : 23|1@1+ (1,0) [0|1] "" Vector__XXX
 SG_ ARB_DT_isABS_active : 22|1@1+ (1,0) [0|1] "" Vector__XXX
 SG_ ARB_DT_CD : 20|2@1+ (1,0) [0|3] "" Vector__XXX
 SG_ DrRA_BrPedState : 18|2@1+ (1,0) [0|3] "" Vector__XXX
 SG_ ARB_CD_blocked : 17|1@1+ (1,0) [0|1] "" Vector__XXX
 SG_ ORTL_ITLimFlag : 16|1@1+ (1,0) [0|1] "" Vector__XXX
 SG_ DT_GearBox_fault_st : 14|2@1+ (1,0) [0|3] "" Vector__XXX
 SG_ DT_system_warn_st : 11|3@1+ (1,0) [0|7] "" Vector__XXX
 SG_ MapChckSt : 9|2@1+ (1,0) [0|0] "" Vector__XXX
 SG_ EBS_SrcValFlag : 8|1@1+ (1,0) [0|0] "" Vector__XXX
 SG_ IntSpdValFlag : 7|1@1+ (1,0) [0|0] "" Vector__XXX
 SG_ DefDistribInUse : 6|1@1+ (1,0) [0|0] "" Vector__XXX
 SG_ CtrlSrcSelBlckd : 5|1@1+ (1,0) [0|0] "" Vector__XXX
 SG_ AccTR_Prms_Incorr : 4|1@1+ (1,0) [0|0] "" Vector__XXX
 SG_ AI_SrcValFlag : 3|1@1+ (1,0) [0|0] "" Vector__XXX
 SG_ DefDistribUnavail : 2|1@1+ (1,0) [0|0] "" Vector__XXX
 SG_ ChosenCtrlSrc : 0|2@1+ (1,0) [0|0] "" Vector__XXX

BO_ 2600439038 DVT_OvrlLim: 8 DVT_Cntrl
 SG_ ProAEPLim_Trq_TrLim : 48|16@1+ (1,0) [0|65535] "" Vector__XXX
 SG_ ProAATLim_Trq_TrLim : 32|16@1+ (1,0) [0|65535] "" Vector__XXX
 SG_ OvrlRTLim : 16|16@1+ (1.5,0) [0|96382] "N*m" Vector__XXX
 SG_ OvrlTTLim : 0|16@1+ (1.5,0) [0|96382] "N*m" Vector__XXX

BO_ 2381399806 DVT_RSPDL_Debug: 8 Vector__XXX
 SG_ RSPDL_Safety_LimitValid : 60|1@1+ (1,0) [0|1] "" Vector__XXX
 SG_ RSPDL_Reverse_LimitValid : 59|1@1+ (1,0) [0|1] "" Vector__XXX
 SG_ RSPDL_LimpMode_LimitValid : 58|1@1+ (1,0) [0|1] "" Vector__XXX
 SG_ LMP_LimpRequest : 57|1@1+ (1,0) [0|1] "" Vector__XXX
 SG_ RSPDL_Internal_LimitValid : 56|1@1+ (1,0) [0|1] "" Vector__XXX
 SG_ LMP_LimpReqSrc7 : 55|1@1+ (1,0) [0|1] "" Vector__XXX
 SG_ RSPDL_HMI_LimitValid : 54|1@1+ (1,0) [0|1] "" Vector__XXX
 SG_ RSPDL_ADAS_LimitValid : 53|1@1+ (1,0) [0|1] "" Vector__XXX
 SG_ LMP_LimpReqSrc6 : 52|1@1+ (1,0) [0|1] "" Vector__XXX
 SG_ LMP_LimpReqSrc5 : 51|1@1+ (1,0) [0|1] "" Vector__XXX
 SG_ LMP_LimpReqSrc4 : 50|1@1+ (1,0) [0|1] "" Vector__XXX
 SG_ LMP_LimpReqSrc3 : 49|1@1+ (1,0) [0|1] "" Vector__XXX
 SG_ LMP_LimpReqSrc2 : 48|1@1+ (1,0) [0|1] "" Vector__XXX
 SG_ LMP_LimpReqSrc1 : 47|1@1+ (1,0) [0|1] "" Vector__XXX
 SG_ RSPDL_LimpReq : 46|1@1+ (1,0) [0|1] "" Vector__XXX
 SG_ RSPDL_IsTqLimdBySpdLim : 45|1@1+ (1,0) [0|1] "" Vector__XXX
 SG_ VSLC_IsIntSpdLimAcv : 44|1@1+ (1,0) [0|1] "" Vector__XXX
 SG_ RSPDL_Limit_Source : 40|4@1+ (1,0) [0|15] "" Vector__XXX
 SG_ RSPDL_Limp_Limit : 32|8@1+ (1,0) [0|255] "kph" Vector__XXX
 SG_ RSPDL_Internal_Limit : 24|8@1+ (1,0) [0|255] "kph" Vector__XXX
 SG_ RSPDL_HMI_Limit : 16|8@1+ (1,0) [0|255] "kph" Vector__XXX
 SG_ RSPDL_ADAS_Limit : 8|8@1+ (1,0) [0|255] "kph" Vector__XXX
 SG_ RSPDL_Actual_Limit : 0|8@1+ (1,0) [0|255] "kph" Vector__XXX

BO_ 2382314750 GS_Debug_1: 8 Vector__XXX
 SG_ MVLCK_SEL_PBKReq : 61|3@1+ (1,0) [0|0] "" Vector__XXX
 SG_ MVLCK_SEL_GBIntlckReq : 58|3@1+ (1,0) [0|0] "" Vector__XXX
 SG_ APP_GS_MvLckReq : 56|2@1+ (1,0) [0|0] "" Vector__XXX
 SG_ Stalk_GS_P_valid : 55|1@1+ (1,0) [0|1] "" Vector__XXX
 SG_ APP_GS_InvDirReq : 54|1@1+ (1,0) [0|0] "" Vector__XXX
 SG_ APP_GS_InvActReq : 53|1@1+ (1,0) [0|0] "" Vector__XXX
 SG_ Stalk_GS_Req : 48|5@1+ (1,0) [0|31] "" Vector__XXX
 SG_ Stalk_GS_NRD_valid : 47|1@1+ (1,0) [0|1] "" Vector__XXX
 SG_ Stalk_GS_valid : 46|1@1+ (1,0) [0|0] "" Vector__XXX
 SG_ Stalk_GS_LongPressedP : 45|1@1+ (1,0) [0|0] "" Vector__XXX
 SG_ Stalk_GS_RND_event : 44|1@1+ (1,0) [0|0] "" Vector__XXX
 SG_ Stalk_GS_P_button : 43|1@1+ (1,0) [0|0] "" Vector__XXX
 SG_ Stalk_GS_NRD_state : 40|3@1+ (1,0) [0|0] "" Vector__XXX
 SG_ EXHAN_ActCondition : 36|4@1+ (1,0) [0|15] "" Vector__XXX
 SG_ EXHAN_ActScenario : 32|4@1+ (1,0) [0|15] "" Vector__XXX
 SG_ EXHAN_GS_AllowReqVec : 24|8@1+ (1,0) [0|255] "" Vector__XXX
 SG_ MVLCK_SEL_State : 21|3@1+ (1,0) [0|0] "" Vector__XXX
 SG_ EXHAN_FinalGSReq : 16|5@1+ (1,0) [0|31] "" Vector__XXX
 SG_ MVLCK_SEL_PBKState : 13|3@1+ (1,0) [0|0] "" Vector__XXX
 SG_ EXHAN_VSMGSReq : 8|5@1+ (1,0) [0|31] "" Vector__XXX
 SG_ EmcyDecelCmd : 7|1@1+ (1,0) [0|0] "" Vector__XXX
 SG_ INIT_GS_VehMvFwdFlag : 6|1@1+ (1,0) [0|0] "" Vector__XXX
 SG_ EXHAN_ChsnGSReqValid : 5|1@1+ (1,0) [0|1] "" Vector__XXX
 SG_ EXHAN_ChsnGSReq : 0|5@1+ (1,0) [0|31] "" Vector__XXX

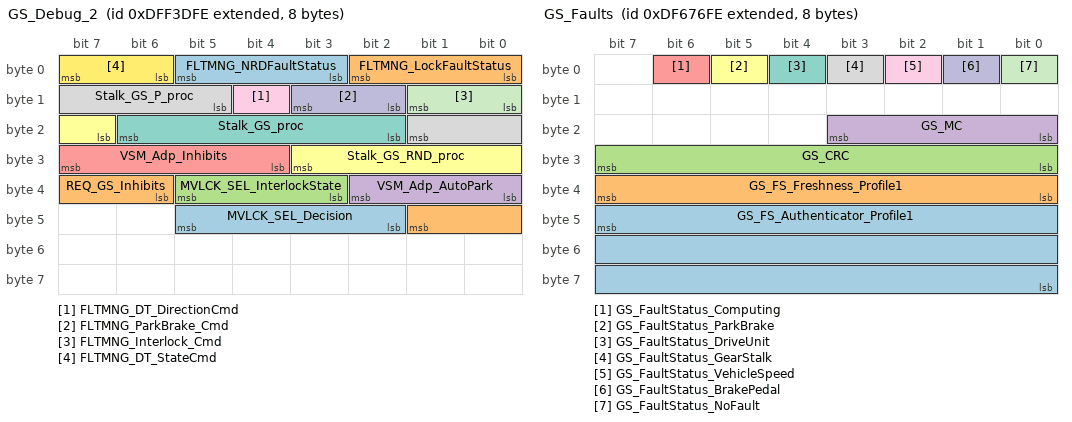
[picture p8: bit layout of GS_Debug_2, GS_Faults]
BO_ 2382315006 GS_Debug_2: 8 Vector__XXX
 SG_ MVLCK_SEL_Decision : 42|4@1+ (1,0) [0|15] "" Vector__XXX
 SG_ REQ_GS_Inhibits : 38|4@1+ (1,0) [0|15] "" Vector__XXX
 SG_ MVLCK_SEL_InterlockState : 35|3@1+ (1,0) [0|5] "" Vector__XXX
 SG_ VSM_Adp_AutoPark : 32|3@1+ (1,0) [0|7] "" Vector__XXX
 SG_ VSM_Adp_Inhibits : 28|4@1+ (1,0) [0|15] "" Vector__XXX
 SG_ Stalk_GS_RND_proc : 23|5@1+ (1,0) [0|31] "" Vector__XXX
 SG_ Stalk_GS_proc : 18|5@1+ (1,0) [0|31] "" Vector__XXX
 SG_ Stalk_GS_P_proc : 13|5@1+ (1,0) [0|31] "" Vector__XXX
 SG_ FLTMNG_DT_DirectionCmd : 12|1@1+ (1,0) [0|0] "" Vector__XXX
 SG_ FLTMNG_ParkBrake_Cmd : 10|2@1+ (1,0) [0|0] "" Vector__XXX
 SG_ FLTMNG_Interlock_Cmd : 8|2@1+ (1,0) [0|0] "" Vector__XXX
 SG_ FLTMNG_DT_StateCmd : 6|2@1+ (1,0) [0|0] "" Vector__XXX
 SG_ FLTMNG_NRDFaultStatus : 3|3@1+ (1,0) [0|0] "" Vector__XXX
 SG_ FLTMNG_LockFaultStatus : 0|3@1+ (1,0) [0|0] "" Vector__XXX

BO_ 2399117822 GS_Debug_3: 4 Vector__XXX
 SG_ Stalk_GS_NRD_ch1 : 24|8@1+ (0.05,0) [0|12] "V" Vector__XXX
 SG_ Stalk_GS_NRD_ch2 : 16|8@1+ (0.05,0) [0|12] "V" Vector__XXX
 SG_ Stalk_GS_P_ch2 : 8|8@1+ (0.05,0) [0|12] "V" Vector__XXX
 SG_ Stalk_GS_P_ch1 : 0|8@1+ (0.05,0) [0|12] "V" Vector__XXX

BO_ 2381739774 GS_Faults: 8 Vector__XXX
 SG_ GS_FS_Authenticator_Profile1 : 47|24@0+ (1,0) [0|16777215] "" Vector__XXX
 SG_ GS_FS_Freshness_Profile1 : 39|8@0+ (1,0) [0|255] "" Vector__XXX
 SG_ GS_CRC : 24|8@1+ (1,0) [0|255] "" Vector__XXX
 SG_ GS_MC : 16|4@1+ (1,0) [0|15] "" Vector__XXX
 SG_ GS_FaultStatus_Computing : 6|1@1+ (1,0) [0|1] "" Vector__XXX
 SG_ GS_FaultStatus_ParkBrake : 5|1@1+ (1,0) [0|1] "" Vector__XXX
 SG_ GS_FaultStatus_DriveUnit : 4|1@1+ (1,0) [0|1] "" Vector__XXX
 SG_ GS_FaultStatus_GearStalk : 3|1@1+ (1,0) [0|1] "" Vector__XXX
 SG_ GS_FaultStatus_VehicleSpeed : 2|1@1+ (1,0) [0|1] "" Vector__XXX
 SG_ GS_FaultStatus_BrakePedal : 1|1@1+ (1,0) [0|1] "" Vector__XXX
 SG_ GS_FaultStatus_NoFault : 0|1@1+ (1,0) [0|1] "" Vector__XXX

BO_ 2381740030 GS_Resets: 8 Vector__XXX
 SG_ GS_LatchReset : 0|1@1+ (1,0) [0|1] "" Vector__XXX

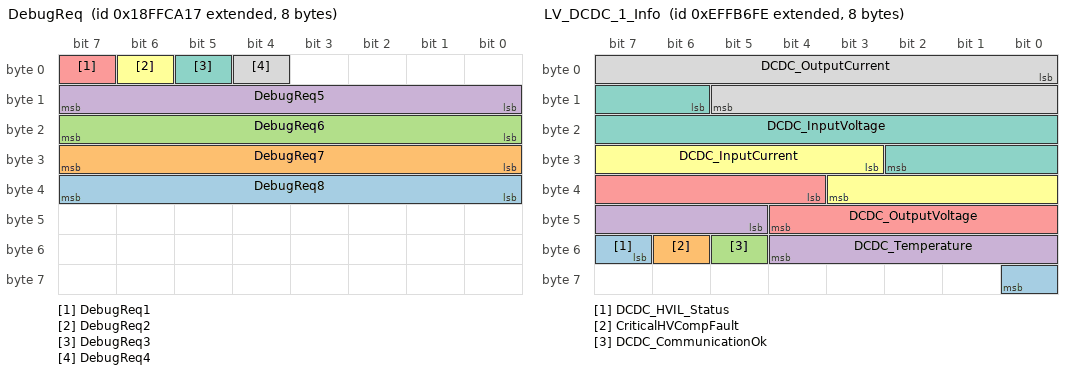
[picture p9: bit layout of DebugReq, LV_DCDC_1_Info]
BO_ 2566900247 DebugReq: 8 InstrumentCluster
 SG_ DebugReq8 : 32|8@1+ (1,0) [0|255] ""  DCU
 SG_ DebugReq7 : 24|8@1+ (1,0) [0|255] ""  DCU
 SG_ DebugReq6 : 16|8@1+ (1,0) [0|255] ""  DCU
 SG_ DebugReq5 : 8|8@1+ (1,0) [0|255] ""  DCU
 SG_ DebugReq1 : 7|1@1+ (1,0) [0|1] ""  DCU
 SG_ DebugReq2 : 6|1@1+ (1,0) [0|1] ""  DCU
 SG_ DebugReq3 : 5|1@1+ (1,0) [0|1] ""  DCU
 SG_ DebugReq4 : 4|1@1+ (1,0) [0|1] ""  DCU

BO_ 2566906110 DCU_Debug_In1: 8 Vector__XXX
 SG_ AnalogInput_11 : 48|16@1+ (0.001,0) [0|64.255] "V" Vector__XXX
 SG_ AnalogInput_02 : 32|16@1+ (0.001,0) [0|64.255] "V" Vector__XXX
 SG_ AnalogInput_03 : 16|16@1+ (0.001,0) [0|64.255] "V" Vector__XXX
 SG_ AccelMeasure : 8|8@1+ (0.02,-2.5) [-2.5|2.6] "" Vector__XXX
 SG_ IsIgnitionOn : 0|1@1+ (1,0) [0|0] "" Vector__XXX

BO_ 2381855998 RightDPadState: 1 Vector__XXX
 SG_ RiDPadSt : 0|4@1+ (1,0) [0|15] "" Vector__XXX

BO_ 882 VCU_CtrlDCDC: 8 VCU
 SG_ VCU_DCDC_Current_LimitValue : 23|9@0+ (1,0) [0|511] "A" Vector__XXX
 SG_ VCU_DCDCActivation : 15|2@0+ (1,0) [0|3] ""  OBC
 SG_ VCU_DCDCVoltageReq : 7|7@0+ (0.05,10.6) [10.6|16] "V"  OBC

BO_ 2399123198 LV_DCDC_1_Info: 8 Vector__XXX
 SG_ DCDC_HVIL_Status : 55|2@1+ (1,0) [0|0] "" Vector__XXX
 SG_ CriticalHVCompFault : 54|1@1+ (1,0) [0|1] "" Vector__XXX
 SG_ DCDC_CommunicationOk : 53|1@1+ (1,0) [0|1] "" Vector__XXX
 SG_ DCDC_Temperature : 45|8@1+ (1,-40) [-40|215] "Degree Celsius" Vector__XXX
 SG_ DCDC_OutputVoltage : 36|9@1+ (0.1,0) [0|51.1] "V" Vector__XXX
 SG_ DCDC_InputCurrent : 27|9@1- (0.1,0) [-25.6|25.5] "A" Vector__XXX
 SG_ DCDC_InputVoltage : 14|13@1+ (0.1,0) [0|819.1] "V" Vector__XXX
 SG_ DCDC_OutputCurrent : 0|14@1- (0.1,0) [-819.2|819.1] "A" Vector__XXX

BO_ 2314626046 ClearanceCalculation: 8 Vector__XXX
 SG_ VehPitchAngle : 16|16@1+ (0.002,-64) [-64|64.51] "deg" Vector__XXX
 SG_ VehPitchAngleFigureOfMerit : 10|2@1+ (1,0) [0|3] "" Vector__XXX
 SG_ VehRideHeightFigureOfMerit : 8|2@1+ (1,0) [0|3] "" Vector__XXX
 SG_ VehRideHeight : 0|8@1+ (2,0) [0|510] "" Vector__XXX

BO_ 2582780183 CARGOLHMIR: 8 Vector__XXX
 SG_ CargoLightModeHmiReq : 0|3@1+ (1,0) [0|7] "" Vector__XXX

BO_ 2582781182 CARGOLM: 1 Vector__XXX
 SG_ CargoLightModeAuto : 0|2@1+ (1,0) [0|3] "" Vector__XXX

BO_ 2582780670 CARGOLSA: 1 Vector__XXX
 SG_ CargoLightStateAct : 0|3@1+ (1,0) [0|7] "" Vector__XXX

BO_ 2365556990 BSM1: 8 ADAS
 SG_ BsmWarnReqRi : 6|2@1+ (1,0) [0|3] ""  HMI,ELS
 SG_ BsmWarnReqLe : 4|2@1+ (1,0) [0|3] ""  HMI,ELS
 SG_ BsmSt : 0|4@1+ (1,0) [0|15] ""  HMI

BO_ 2365557246 BSMDS: 8 ELS
 SG_ BsmWarnLampStRi : 2|2@1+ (1,0) [0|3] ""  ADAS
 SG_ BsmWarnLampStLe : 0|2@1+ (1,0) [0|3] ""  ADAS

BO_ 2381860350 ELS2HMI_FlashInd_Req: 2 Vector__XXX
 SG_ ELS2HMI_CRC : 8|8@1+ (1,0) [0|0] "" Vector__XXX
 SG_ LeftIndicatorReq : 6|2@1+ (1,0) [0|3] "" Vector__XXX
 SG_ RightIndicatorReq : 4|2@1+ (1,0) [0|3] "" Vector__XXX
 SG_ ELS2HMI_Cnt : 0|4@1+ (1,0) [0|0] "" Vector__XXX

BO_ 2583173630 WshrSts: 1 Vector__XXX
 SG_ WasherState : 2|2@1+ (1,0) [0|3] "" Vector__XXX
 SG_ WasherSilenceFault : 1|1@1+ (1,0) [0|1] "" Vector__XXX
 SG_ WasherControlFault : 0|1@1+ (1,0) [0|1] "" Vector__XXX

BO_ 2381723646 RLSensData: 8 Vector__XXX
 SG_ TGlass : 32|8@1+ (0.5,-20) [-20|100] "degC" Vector__XXX
 SG_ SolarIrradiationRight : 24|8@1+ (5,0) [0|1250] "W/m2" Vector__XXX
 SG_ TDew : 16|8@1+ (0.5,-20) [-20|100] "degC" Vector__XXX
 SG_ SolarIrradiationLeft : 8|8@1+ (5,0) [0|1250] "W/m2" Vector__XXX
 SG_ CabinHumidity : 0|8@1+ (0.5,0) [0|125] "%" Vector__XXX

BO_ 2373975806 TP_StateReq: 8 Vector__XXX
 SG_ StateRequest : 0|3@1+ (1,0) [0|7] "" Vector__XXX

BO_ 2381855742 LeftDPadState: 1 Vector__XXX
 SG_ LeDPadSt : 0|4@1+ (1,0) [0|15] "" Vector__XXX

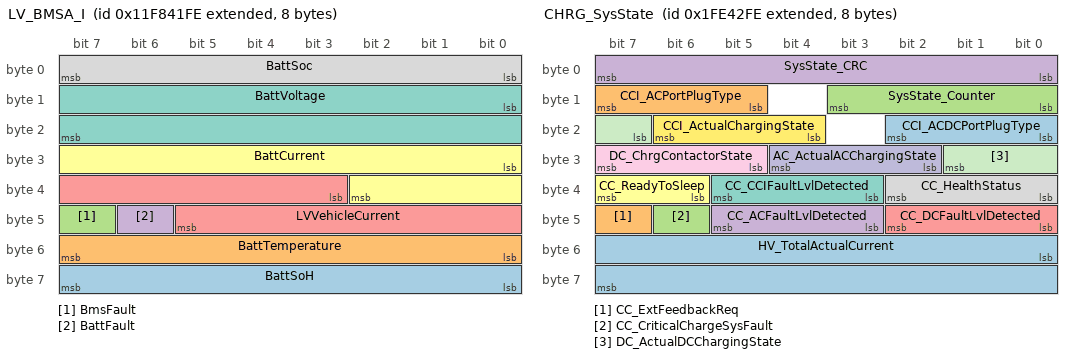
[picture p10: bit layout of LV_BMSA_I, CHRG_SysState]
BO_ 2448966142 LV_BMSA_I: 8 Vector__XXX
 SG_ BattSoH : 56|8@1+ (0.5,0) [0|125] "%" Vector__XXX
 SG_ BattTemperature : 48|8@1+ (1,-40) [-40|210] "C" Vector__XXX
 SG_ BmsFault : 47|1@1+ (1,0) [0|1] "" Vector__XXX
 SG_ BattFault : 46|1@1+ (1,0) [0|1] "" Vector__XXX
 SG_ LVVehicleCurrent : 35|11@1+ (0.25,-255) [-255|255] "A" Vector__XXX
 SG_ BattCurrent : 24|11@1+ (0.25,-255) [-255|255] "A" Vector__XXX
 SG_ BattVoltage : 8|16@1+ (0.001,0) [0|64.255] "V" Vector__XXX
 SG_ BattSoc : 0|8@1+ (0.5,0) [0|125] "%" Vector__XXX

BO_ 2381859582 HMI2ELS_Req: 1 Vector__XXX
 SG_ AutoLowBeamReq : 0|2@1+ (1,0) [0|3] "" Vector__XXX

BO_ 2180924158 CHRG_SysState: 8 Vector__XXX
 SG_ HV_TotalActualCurrent : 48|16@1+ (0.01,-327) [-327|328.35] "A" Vector__XXX
 SG_ CC_ExtFeedbackReq : 47|1@1+ (1,0) [0|1] "" Vector__XXX
 SG_ CC_CriticalChargeSysFault : 46|1@1+ (1,0) [0|1] "" Vector__XXX
 SG_ CC_ACFaultLvlDetected : 43|3@1+ (1,0) [0|7] "" Vector__XXX
 SG_ CC_DCFaultLvlDetected : 40|3@1+ (1,0) [0|7] "" Vector__XXX
 SG_ CC_ReadyToSleep : 38|2@1+ (1,0) [0|3] "" Vector__XXX
 SG_ CC_CCIFaultLvlDetected : 35|3@1+ (1,0) [0|7] "" Vector__XXX
 SG_ CC_HealthStatus : 32|3@1+ (1,0) [0|7] "" Vector__XXX
 SG_ DC_ChrgContactorState : 29|3@1+ (1,0) [0|7] "" Vector__XXX
 SG_ AC_ActualACChargingState : 26|3@1+ (1,0) [0|7] "" Vector__XXX
 SG_ DC_ActualDCChargingState : 23|3@1+ (1,0) [0|7] "" Vector__XXX
 SG_ CCI_ActualChargingState : 20|3@1+ (1,0) [0|7] "" Vector__XXX
 SG_ CCI_ACDCPortPlugType : 16|3@1+ (1,0) [0|7] "" Vector__XXX
 SG_ CCI_ACPortPlugType : 13|3@1+ (1,0) [0|7] "" Vector__XXX
 SG_ SysState_Counter : 8|4@1+ (1,0) [0|15] "" Vector__XXX
 SG_ SysState_CRC : 0|8@1+ (1,0) [0|255] "" Vector__XXX

BO_ 2381859838 ELS2HMI_Sts: 1 Vector__XXX
 SG_ AutoLowBeamSts : 0|2@1+ (1,0) [0|3] "" Vector__XXX

BO_ 2381860606 LGTSLVL2HMI: 1 Vector__XXX
 SG_ HeadLampActualLevel : 2|3@1+ (1,0) [0|7] "" Vector__XXX
 SG_ HeadlampLvlMode : 0|2@1+ (1,0) [0|3] "" Vector__XXX

BO_ 2583184638 HMIPlatform_Info: 8 Vector__XXX
 SG_ ManualLevelling_Value : 0|8@1+ (1,0) [0|100] "" Vector__XXX

BO_ 2583108606 PinPwrDrvr_PinCommand: 1 Vector__XXX
 SG_ PinCommand : 0|8@1+ (1,0) [0|100] "%" Vector__XXX

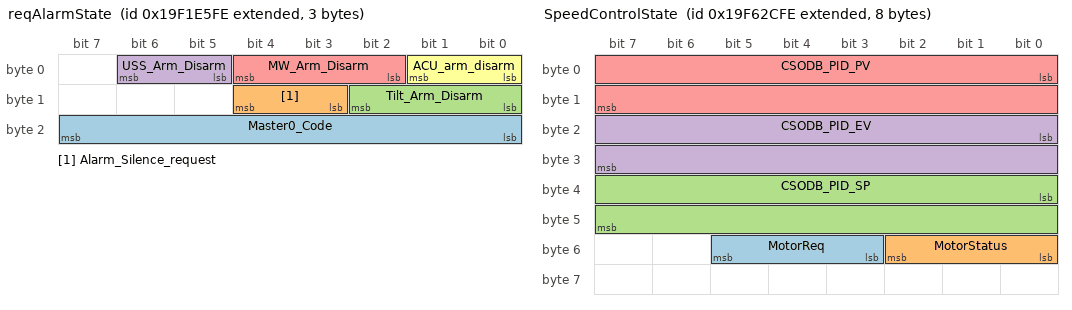
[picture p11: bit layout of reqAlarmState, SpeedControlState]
BO_ 2582767102 reqAlarmState: 3 Vector__XXX
 SG_ Master0_Code : 16|8@1+ (1,0) [0|255] "" Vector__XXX
 SG_ Alarm_Silence_request : 11|2@1+ (1,0) [0|3] "" Vector__XXX
 SG_ Tilt_Arm_Disarm : 8|3@1+ (1,0) [0|7] "" Vector__XXX
 SG_ USS_Arm_Disarm : 5|2@1+ (1,0) [0|3] "" Vector__XXX
 SG_ MW_Arm_Disarm : 2|3@1+ (1,0) [0|7] "" Vector__XXX
 SG_ ACU_arm_disarm : 0|2@1+ (1,0) [0|3] "" Vector__XXX

BO_ 2583175166 WPRWSH_WiperArbReq: 1 Vector__XXX
 SG_ WipeArbRequest : 0|3@1+ (1,0) [0|7] "" Vector__XXX

BO_ 2365553406 DpadModeRequest: 1 Vector__XXX
 SG_ DPadCruiseControlReq : 4|4@1+ (1,0) [0|15] "" Vector__XXX
 SG_ DpadVoiceAssistReq : 2|2@1+ (1,0) [0|3] "" Vector__XXX
 SG_ ExtMirrorAdjReqHMI : 0|2@1+ (1,0) [0|3] "" Vector__XXX

BO_ 2566627838 LVPS_DebugCmd: 8 Vector__XXX
 SG_ DcDcConv3HvIntlockLoss : 2|1@1+ (1,0) [0|0] "" Vector__XXX
 SG_ DcDcConv2HvIntlockLoss : 1|1@1+ (1,0) [0|0] "" Vector__XXX
 SG_ DcDcConv1HvIntlockLoss : 0|1@1+ (1,0) [0|0] "" Vector__XXX

BO_ 2583047422 SpeedControlState: 8 Vector__XXX
 SG_ MotorReq : 51|3@1+ (1,0) [0|7] "" Vector__XXX
 SG_ MotorStatus : 48|3@1+ (1,0) [0|0] "" Vector__XXX
 SG_ CSODB_PID_SP : 32|16@1- (0.1,0) [0|0] "" Vector__XXX
 SG_ CSODB_PID_EV : 16|16@1- (0.1,0) [0|0] "" Vector__XXX
 SG_ CSODB_PID_PV : 0|16@1- (0.1,0) [0|0] "" Vector__XXX

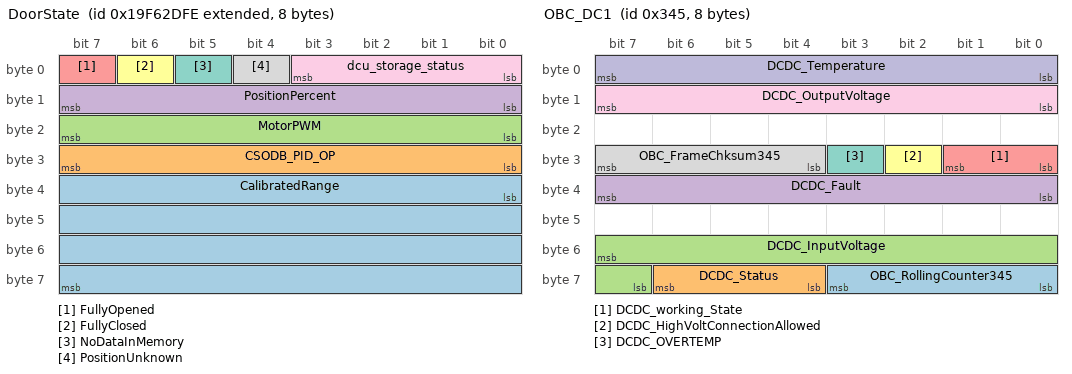
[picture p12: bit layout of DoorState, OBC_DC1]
BO_ 2583047678 DoorState: 8 Vector__XXX
 SG_ CalibratedRange : 32|32@1- (1,0) [-2147483648|2147483647] "" Vector__XXX
 SG_ CSODB_PID_OP : 24|8@1+ (1,0) [0|100] "%" Vector__XXX
 SG_ MotorPWM : 16|8@1+ (1,0) [0|100] "%" Vector__XXX
 SG_ PositionPercent : 8|8@1+ (1,0) [0|100] "%" Vector__XXX
 SG_ FullyOpened : 7|1@1+ (1,0) [0|1] "" Vector__XXX
 SG_ FullyClosed : 6|1@1+ (1,0) [0|1] "" Vector__XXX
 SG_ NoDataInMemory : 5|1@1+ (1,0) [0|1] "" Vector__XXX
 SG_ PositionUnknown : 4|1@1+ (1,0) [0|1] "" Vector__XXX
 SG_ dcu_storage_status : 0|4@1+ (1,0) [0|15] "" Vector__XXX

BO_ 2399122430 LV_Info: 8 Vector__XXX
 SG_ LV_Info_cs : 56|8@1+ (1,0) [0|255] "" Vector__XXX
 SG_ LV_Info_rc : 48|4@1+ (1,0) [0|15] "" Vector__XXX
 SG_ HVTotActCurrent : 16|16@1+ (0.05,0) [0|3276.75] "A" Vector__XXX
 SG_ HVMinPowerReq : 0|16@1+ (0.1,0) [0|6553.5] "kW" Vector__XXX

BO_ 837 OBC_DC1: 8 OBC
 SG_ OBC_RollingCounter345 : 59|4@0+ (1,0) [0|15] ""  VCU
 SG_ DCDC_Status : 62|3@0+ (1,0) [0|7] ""  VCU
 SG_ DCDC_InputVoltage : 55|9@0+ (1,0) [0|500] "V"  VCU
 SG_ DCDC_Fault : 39|8@0+ (1,0) [0|255] ""  VCU
 SG_ DCDC_working_State : 25|2@0+ (1,0) [0|3] ""  VCU
 SG_ DCDC_HighVoltConnectionAllowed : 26|1@0+ (1,0) [0|1] ""  VCU
 SG_ DCDC_OVERTEMP : 27|1@0+ (1,0) [0|0] "" Vector__XXX
 SG_ OBC_FrameChksum345 : 31|4@0+ (1,0) [0|15] ""  VCU
 SG_ DCDC_OutputVoltage : 15|8@0+ (0.1,4) [4|21.5] "V"  VCU
 SG_ DCDC_Temperature : 7|8@0+ (1,-40) [-40|214] "Degree Celsius"  VCU

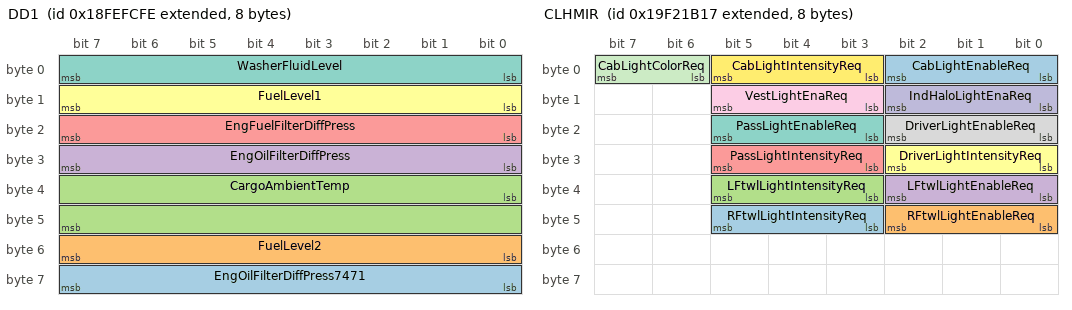
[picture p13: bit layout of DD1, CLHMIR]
BO_ 2566847742 DD1: 8 Vector__XXX
 SG_ EngOilFilterDiffPress7471 : 56|8@1+ (5,0) [0|1250] "kPa" Vector__XXX
 SG_ FuelLevel2 : 48|8@1+ (0.4,0) [0|100] "%" Vector__XXX
 SG_ CargoAmbientTemp : 32|16@1+ (0.03125,-273) [-273|1734.96875] "C" Vector__XXX
 SG_ EngOilFilterDiffPress : 24|8@1+ (0.5,0) [0|125] "kPa" Vector__XXX
 SG_ EngFuelFilterDiffPress : 16|8@1+ (2,0) [0|500] "kPa" Vector__XXX
 SG_ FuelLevel1 : 8|8@1+ (0.4,0) [0|100] "%" Vector__XXX
 SG_ WasherFluidLevel : 0|8@1+ (0.4,0) [0|100] "%" Vector__XXX

BO_ 2583064318 PPSDS: 8 Vector__XXX
 SG_ PassPwrHallTick : 7|1@1+ (1,0) [0|1] "" Vector__XXX
 SG_ PassPwrSldDoorFaults : 3|4@1+ (1,0) [0|15] "" Vector__XXX
 SG_ PassPwrSldDoorStatus : 0|3@1+ (1,0) [0|0] "" Vector__XXX

BO_ 2582780695 CLHMIR: 8 Vector__XXX
 SG_ RFtwlLightIntensityReq : 43|3@1+ (1,0) [0|7] "" Vector__XXX
 SG_ RFtwlLightEnableReq : 40|3@1+ (1,0) [0|7] "" Vector__XXX
 SG_ LFtwlLightIntensityReq : 35|3@1+ (1,0) [0|7] "" Vector__XXX
 SG_ LFtwlLightEnableReq : 32|3@1+ (1,0) [0|7] "" Vector__XXX
 SG_ PassLightIntensityReq : 27|3@1+ (1,0) [0|7] "" Vector__XXX
 SG_ DriverLightIntensityReq : 24|3@1+ (1,0) [0|7] "" Vector__XXX
 SG_ PassLightEnableReq : 19|3@1+ (1,0) [0|7] "" Vector__XXX
 SG_ DriverLightEnableReq : 16|3@1+ (1,0) [0|7] "" Vector__XXX
 SG_ VestLightEnaReq : 11|3@1+ (1,0) [0|7] "" Vector__XXX
 SG_ IndHaloLightEnaReq : 8|3@1+ (1,0) [0|7] "" Vector__XXX
 SG_ CabLightColorReq : 6|2@1+ (1,0) [0|3] "-" Vector__XXX
 SG_ CabLightIntensityReq : 3|3@1+ (1,0) [0|7] "" Vector__XXX
 SG_ CabLightEnableReq : 0|3@1+ (1,0) [0|7] "" Vector__XXX

BO_ 2582781438 CLSA: 8 Vector__XXX
 SG_ RFtwlLightModeAuto : 61|2@1+ (1,0) [0|3] "" Vector__XXX
 SG_ RFtwlLightIntensityState : 58|3@1+ (1,0) [0|7] "" Vector__XXX
 SG_ RFtwlLightEnableState : 56|2@1+ (1,0) [0|3] "" Vector__XXX
 SG_ LFtwlLightModeAuto : 53|2@1+ (1,0) [0|3] "" Vector__XXX
 SG_ LFtwlLightIntensityState : 50|3@1+ (1,0) [0|7] "" Vector__XXX
 SG_ LFtwlLightEnableState : 48|2@1+ (1,0) [0|3] "" Vector__XXX
 SG_ PassLightModeAuto : 45|2@1+ (1,0) [0|3] "" Vector__XXX
 SG_ DriverLightModeAuto : 43|2@1+ (1,0) [0|3] "" Vector__XXX
 SG_ PassLightIntensityState : 40|3@1+ (1,0) [0|7] "" Vector__XXX
 SG_ PassLightEnableState : 37|2@1+ (1,0) [0|3] "" Vector__XXX
 SG_ DriverLightIntensityState : 34|3@1+ (1,0) [0|7] "" Vector__XXX
 SG_ DriverLightEnableState : 32|2@1+ (1,0) [0|3] "" Vector__XXX
 SG_ IndLighstIntensityState : 28|3@1+ (1,0) [0|7] "" Vector__XXX
 SG_ IndtLightsColorState : 26|2@1+ (1,0) [0|3] "" Vector__XXX
 SG_ SaloonLightsEnableState : 24|2@1+ (1,0) [0|3] "" Vector__XXX
 SG_ VestLightIntensityState : 20|3@1+ (1,0) [0|7] "" Vector__XXX
 SG_ VestLightColorState : 18|2@1+ (1,0) [0|3] "-" Vector__XXX
 SG_ VestLightEnableState : 16|2@1+ (1,0) [0|3] "" Vector__XXX
 SG_ HaloLighstIntensityState : 12|3@1+ (1,0) [0|7] "" Vector__XXX
 SG_ HaloLightsColorState : 10|2@1+ (1,0) [0|3] "-" Vector__XXX
 SG_ CabLightModeAuto : 8|2@1+ (1,0) [0|3] "" Vector__XXX
 SG_ CabLightColorState : 5|2@1+ (1,0) [0|3] "-" Vector__XXX
 SG_ CabLightIntensityState : 2|3@1+ (1,0) [0|7] "" Vector__XXX
 SG_ CabLightEnableState : 0|2@1+ (1,0) [0|3] "" Vector__XXX

BO_ 197 DCDC_DC2: 8 OBC
 SG_ DCDC_OutputCurrent : 47|12@0+ (0.1,0) [0|254] "A"  VCU
 SG_ DCDC_InputCurrent : 39|8@0+ (0.1,0) [0|25.4] "A"  VCU

BO_ 2381862910 AlarmHornRequest: 8 Vector__XXX
 SG_ AlarmHornReq : 0|2@1+ (1,0) [0|3] "" Vector__XXX

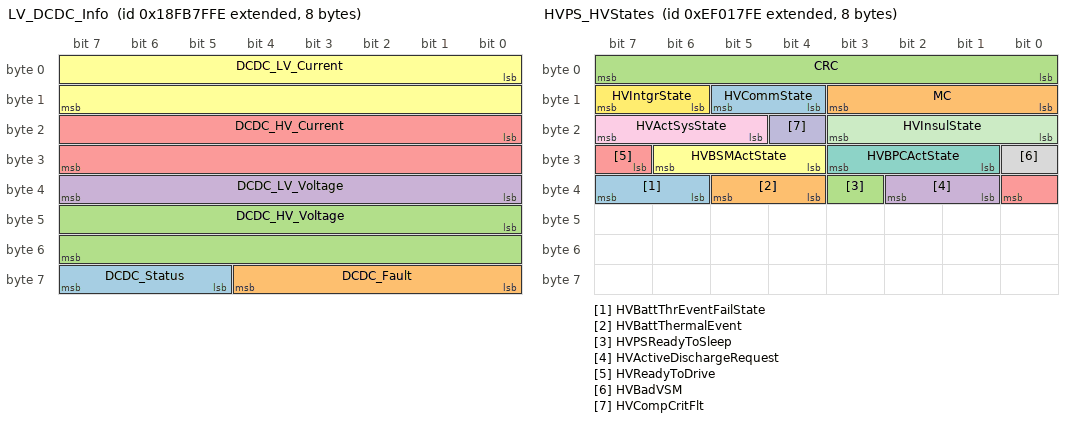
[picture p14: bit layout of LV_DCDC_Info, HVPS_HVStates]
BO_ 2566619134 LV_DCDC_Info: 8 Vector__XXX
 SG_ DCDC_Status : 61|3@1+ (1,0) [0|7] "" Vector__XXX
 SG_ DCDC_Fault : 56|5@1+ (1,0) [0|31] "" Vector__XXX
 SG_ DCDC_HV_Voltage : 40|16@1+ (0.1,0) [0|6553.5] "V" Vector__XXX
 SG_ DCDC_LV_Voltage : 32|8@1+ (0.2,0) [0|51] "V" Vector__XXX
 SG_ DCDC_HV_Current : 16|16@1+ (0.05,-1600) [-1600|1676.75] "A" Vector__XXX
 SG_ DCDC_LV_Current : 0|16@1+ (0.05,-1600) [-1600|1676.75] "A" Vector__XXX

BO_ 2583066110 CENTLOCKIN_MobApp: 8 Vector__XXX
 SG_ CentralLockRequest : 0|3@1+ (1,0) [0|7] "-" Vector__XXX

BO_ 2398099454 HVPS_HVStates: 8 Vector__XXX
 SG_ HVBattThrEventFailState : 38|2@1+ (1,0) [0|3] "" Vector__XXX
 SG_ HVBattThermalEvent : 36|2@1+ (1,0) [0|3] "" Vector__XXX
 SG_ HVPSReadyToSleep : 35|1@1+ (1,0) [0|1] "" Vector__XXX
 SG_ HVActiveDischargeRequest : 33|2@1+ (1,0) [0|3] "" Vector__XXX
 SG_ HVReadyToDrive : 31|2@1+ (1,0) [0|3] "" Vector__XXX
 SG_ HVBSMActState : 28|3@1+ (1,0) [0|7] "" Vector__XXX
 SG_ HVBPCActState : 25|3@1+ (1,0) [0|7] "" Vector__XXX
 SG_ HVBadVSM : 24|1@1+ (1,0) [0|1] "" Vector__XXX
 SG_ HVActSysState : 21|3@1+ (1,0) [0|7] "" Vector__XXX
 SG_ HVCompCritFlt : 20|1@1+ (1,0) [0|1] "" Vector__XXX
 SG_ HVInsulState : 16|4@1+ (1,0) [0|15] "" Vector__XXX
 SG_ HVIntgrState : 14|2@1+ (1,0) [0|3] "" Vector__XXX
 SG_ HVCommState : 12|2@1+ (1,0) [0|3] "" Vector__XXX
 SG_ MC : 8|4@1+ (1,0) [0|0] "" Vector__XXX
 SG_ CRC : 0|8@1+ (1,0) [0|0] "" Vector__XXX

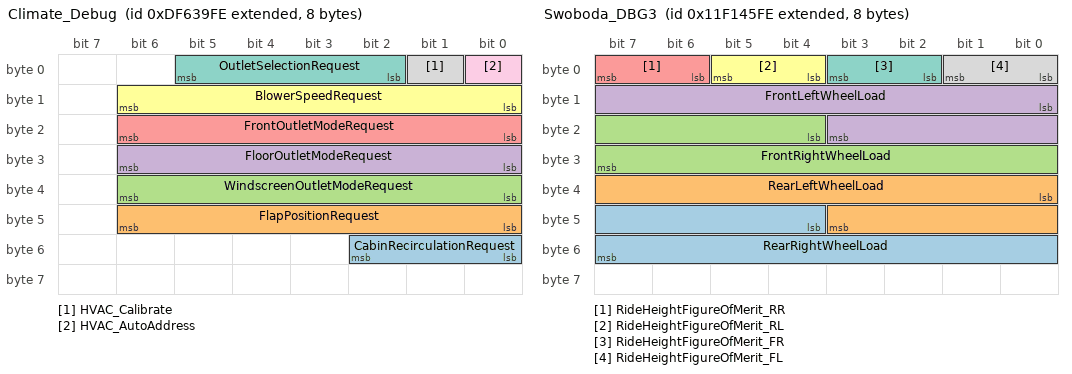
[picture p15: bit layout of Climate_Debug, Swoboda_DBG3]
BO_ 2381724158 Climate_Debug: 8 Vector__XXX
 SG_ CabinRecirculationRequest : 48|3@1+ (1,0) [0|3] "" Vector__XXX
 SG_ FlapPositionRequest : 40|7@1+ (1,0) [0|100] "%" Vector__XXX
 SG_ WindscreenOutletModeRequest : 32|7@1+ (1,0) [0|100] "%" Vector__XXX
 SG_ FloorOutletModeRequest : 24|7@1+ (1,0) [0|100] "%" Vector__XXX
 SG_ FrontOutletModeRequest : 16|7@1+ (1,0) [0|100] "%" Vector__XXX
 SG_ BlowerSpeedRequest : 8|7@1+ (1,0) [0|100] "%" Vector__XXX
 SG_ OutletSelectionRequest : 2|4@1+ (1,0) [0|15] "" Vector__XXX
 SG_ HVAC_Calibrate : 1|1@1+ (1,0) [0|1] "" Vector__XXX
 SG_ HVAC_AutoAddress : 0|1@1+ (1,0) [0|1] "" Vector__XXX

BO_ 2448508414 Swoboda_DBG3: 8 Vector__XXX
 SG_ RearRightWheelLoad : 44|12@1+ (1,0) [0|4095] "" Vector__XXX
 SG_ RearLeftWheelLoad : 32|12@1+ (1,0) [0|4095] "" Vector__XXX
 SG_ FrontRightWheelLoad : 20|12@1+ (1,0) [0|4095] "" Vector__XXX
 SG_ FrontLeftWheelLoad : 8|12@1+ (1,0) [0|4095] "" Vector__XXX
 SG_ RideHeightFigureOfMerit_RR : 6|2@1+ (1,0) [0|3] "" Vector__XXX
 SG_ RideHeightFigureOfMerit_RL : 4|2@1+ (1,0) [0|3] "" Vector__XXX
 SG_ RideHeightFigureOfMerit_FR : 2|2@1+ (1,0) [0|3] "" Vector__XXX
 SG_ RideHeightFigureOfMerit_FL : 0|2@1+ (1,0) [0|3] "" Vector__XXX

BO_ 2381912343 ODM_Data: 8 Vector__XXX
 SG_ ODM_Data_Event : 48|8@1+ (1,0) [0|0] "" Vector__XXX
 SG_ ODM_Data_OdometerValue : 16|32@1+ (1,0) [0|1700000000] "" Vector__XXX
 SG_ ODM_Data_Checksum : 8|8@1+ (1,0) [0|255] "" Vector__XXX
 SG_ ODM_Data_Counter : 0|4@1+ (1,0) [0|15] "" Vector__XXX

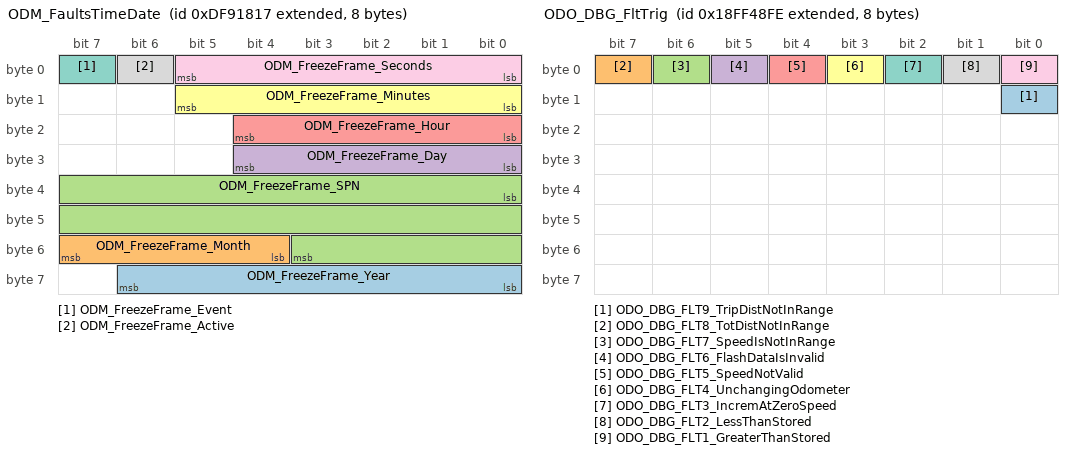
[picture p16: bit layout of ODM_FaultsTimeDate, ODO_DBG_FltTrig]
BO_ 2381912087 ODM_FaultsTimeDate: 8 Vector__XXX
 SG_ ODM_FreezeFrame_Year : 56|7@1+ (1,2000) [2000|2127] "" Vector__XXX
 SG_ ODM_FreezeFrame_Month : 52|4@1+ (1,0) [1|12] "" Vector__XXX
 SG_ ODM_FreezeFrame_SPN : 32|20@1+ (1,0) [0|1048575] "" Vector__XXX
 SG_ ODM_FreezeFrame_Day : 24|5@1+ (1,0) [0|31] "" Vector__XXX
 SG_ ODM_FreezeFrame_Hour : 16|5@1+ (1,0) [0|23] "" Vector__XXX
 SG_ ODM_FreezeFrame_Minutes : 8|6@1+ (1,0) [0|59] "" Vector__XXX
 SG_ ODM_FreezeFrame_Event : 7|1@1+ (1,0) [0|1] "" Vector__XXX
 SG_ ODM_FreezeFrame_Active : 6|1@1+ (1,0) [0|1] "" Vector__XXX
 SG_ ODM_FreezeFrame_Seconds : 0|6@1+ (1,0) [0|59] "" Vector__XXX

BO_ 2566866942 ODO_DBG: 8 Vector__XXX
 SG_ ODO_DBG_ODM_RESET : 3|1@1+ (1,0) [0|1] "" Vector__XXX
 SG_ ODO_DBG_InitCompleted : 2|1@1+ (1,0) [0|1] "" Vector__XXX
 SG_ ODO_DBG_OverwriteFromHmi : 1|1@1+ (1,0) [0|1] "" Vector__XXX
 SG_ ODO_DBG_OverwriteByZero : 0|1@1+ (1,0) [0|1] "" Vector__XXX

BO_ 2566867198 ODO_DBG_FltTrig: 8 Vector__XXX
 SG_ ODO_DBG_FLT9_TripDistNotInRange : 8|1@1+ (1,0) [0|1] "" Vector__XXX
 SG_ ODO_DBG_FLT8_TotDistNotInRange : 7|1@1+ (1,0) [0|1] "" Vector__XXX
 SG_ ODO_DBG_FLT7_SpeedIsNotInRange : 6|1@1+ (1,0) [0|1] "" Vector__XXX
 SG_ ODO_DBG_FLT6_FlashDataIsInvalid : 5|1@1+ (1,0) [0|1] "" Vector__XXX
 SG_ ODO_DBG_FLT5_SpeedNotValid : 4|1@1+ (1,0) [0|1] "" Vector__XXX
 SG_ ODO_DBG_FLT4_UnchangingOdometer : 3|1@1+ (1,0) [0|1] "" Vector__XXX
 SG_ ODO_DBG_FLT3_IncremAtZeroSpeed : 2|1@1+ (1,0) [0|1] "" Vector__XXX
 SG_ ODO_DBG_FLT2_LessThanStored : 1|1@1+ (1,0) [0|1] "" Vector__XXX
 SG_ ODO_DBG_FLT1_GreaterThanStored : 0|1@1+ (1,0) [0|1] "" Vector__XXX

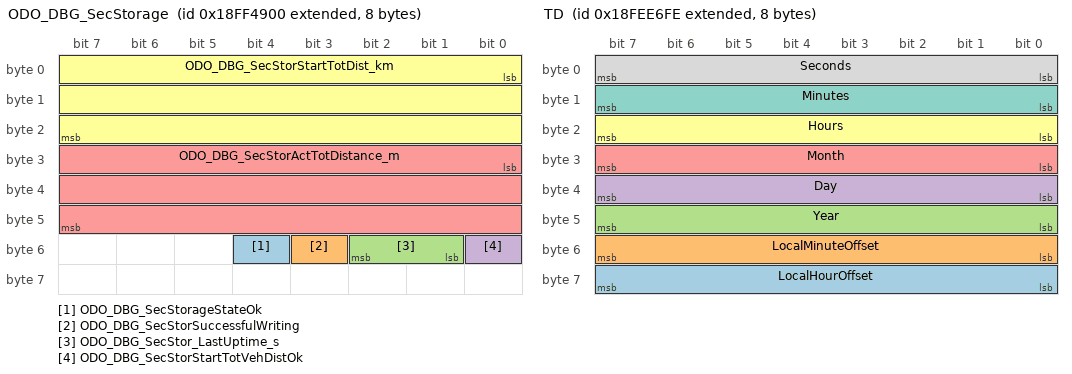
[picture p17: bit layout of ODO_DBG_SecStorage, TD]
BO_ 2566867200 ODO_DBG_SecStorage: 8 Vector__XXX
 SG_ ODO_DBG_SecStorageStateOk : 52|1@1+ (1,0) [0|1] "" Vector__XXX
 SG_ ODO_DBG_SecStorSuccessfulWriting : 51|1@1+ (1,0) [0|1] "" Vector__XXX
 SG_ ODO_DBG_SecStor_LastUptime_s : 49|2@1+ (1,0) [0|3] "" Vector__XXX
 SG_ ODO_DBG_SecStorStartTotVehDistOk : 48|1@1+ (1,0) [0|1] "" Vector__XXX
 SG_ ODO_DBG_SecStorActTotDistance_m : 24|24@1+ (1,0) [0|16777215] "m" Vector__XXX
 SG_ ODO_DBG_SecStorStartTotDist_km : 0|24@1+ (0.1,0) [0|1677721.5] "km" Vector__XXX

BO_ 2566865918 ODO_status1: 8 Vector__XXX
 SG_ VD_CRC : 56|8@1+ (1,0) [0|255] "" Vector__XXX
 SG_ VD_Cnt : 48|4@1+ (1,0) [0|15] "" Vector__XXX
 SG_ ODO_FaultStatus : 32|2@1+ (1,0) [0|3] "" Vector__XXX
 SG_ HghRsolutionTotalVehicleDistance : 0|32@1+ (1,0) [0|4294967295] "m" Vector__XXX

BO_ 2566866174 ODO_status2: 8 Vector__XXX
 SG_ TripDistance_m : 0|32@1+ (1,0) [0|1700000000] "" Vector__XXX

BO_ 2566866430 ODO_To_HMI: 8 Vector__XXX
 SG_ OS_CRC : 56|8@1+ (1,0) [0|255] "" Vector__XXX
 SG_ OS_Cnt : 48|4@1+ (1,0) [0|15] "" Vector__XXX
 SG_ OdoDTCFrameSelr : 3|1@1+ (1,0) [0|0] "" Vector__XXX
 SG_ OdometerRoutineRequestToHMI : 0|3@1+ (1,0) [0|7] "" Vector__XXX

BO_ 2566842110 TD: 8 Vector__XXX
 SG_ LocalHourOffset : 56|8@1+ (1,-125) [-23|23] "h" Vector__XXX
 SG_ LocalMinuteOffset : 48|8@1+ (1,-125) [-59|59] "min" Vector__XXX
 SG_ Year : 40|8@1+ (1,1985) [1985|2235] "years" Vector__XXX
 SG_ Day : 32|8@1+ (0.25,0) [0.25|31.75] "days" Vector__XXX
 SG_ Month : 24|8@1+ (1,0) [1|12] "months" Vector__XXX
 SG_ Hours : 16|8@1+ (1,0) [0|23] "h" Vector__XXX
 SG_ Minutes : 8|8@1+ (1,0) [0|59] "min" Vector__XXX
 SG_ Seconds : 0|8@1+ (0.25,0) [0|59.75] "s" Vector__XXX

BO_ 2448507134 Swoboda_EXTDBG1: 8 Vector__XXX
 SG_ HeightMeasuredRR : 48|16@1- (0.01,0) [-327.68|327.67] "mm" Vector__XXX
 SG_ HeightMeasuredRL : 32|16@1- (0.01,0) [-327.68|327.67] "mm" Vector__XXX
 SG_ HeightMeasuredFR : 16|16@1- (0.01,0) [-327.68|327.67] "mm" Vector__XXX
 SG_ HeightMeasuredFL : 0|16@1- (0.01,0) [-327.68|327.67] "mm" Vector__XXX

BO_ 2448843262 Swoboda_DBG1: 8 Vector__XXX
 SG_ RelVoltage_RR : 48|16@1+ (0.002,0) [0|100] "" Vector__XXX
 SG_ RelVoltage_RL : 32|16@1+ (0.002,0) [0|100] "" Vector__XXX
 SG_ RelVoltage_FR : 16|16@1+ (0.002,0) [0|100] "" Vector__XXX
 SG_ RelVoltage_FL : 0|16@1+ (0.002,0) [0|100] "" Vector__XXX

BO_ 2448843518 Swoboda_DBG2: 8 Vector__XXX
 SG_ RideHeight_RR : 48|16@1- (0.01,0) [-327.68|327.67] "mm" Vector__XXX
 SG_ RideHeight_RL : 32|16@1- (0.01,0) [-327.68|327.67] "mm" Vector__XXX
 SG_ RideHeight_FR : 16|16@1- (0.01,0) [-327.68|327.67] "mm" Vector__XXX
 SG_ RideHeight_FL : 0|16@1- (0.01,0) [-327.68|327.67] "mm" Vector__XXX

BO_ 2448507390 Swoboda_EXTDBG2: 8 Vector__XXX
 SG_ RotationAngleRR : 48|16@1+ (0.01,0) [0|360] "deg" Vector__XXX
 SG_ RotationAngleRL : 32|16@1+ (0.01,0) [0|360] "deg" Vector__XXX
 SG_ RotationAngleFR : 16|16@1+ (0.01,0) [0|360] "deg" Vector__XXX
 SG_ RotationAngleFL : 0|16@1+ (0.01,0) [0|360] "deg" Vector__XXX

BO_ 2448507646 Swoboda_EXTDBG3: 8 Vector__XXX
 SG_ Voltage_RR : 48|16@1+ (0.0001,0) [0|6.5535] "V" Vector__XXX
 SG_ Voltage_RL : 32|16@1+ (0.0001,0) [0|6.5535] "V" Vector__XXX
 SG_ Voltage_FR : 16|16@1+ (0.0001,0) [0|6.5535] "V" Vector__XXX
 SG_ Voltage_FL : 0|16@1+ (0.0001,0) [0|6.5535] "V" Vector__XXX

BO_ 2365251326 CABIN_IO_1_ECU_CAN1_1: 1 Vector__XXX
 SG_ LtchSttAAAC0B5D : 0|2@1+ (1,0) [0|3] "" Vector__XXX

BO_ 2365251070 CABIN_IO_2_ECU_CAN2_1: 1 Vector__XXX
 SG_ BlkhdDrLtchRq79F31101 : 4|2@1+ (1,0) [0|3] "-" Vector__XXX
 SG_ PssDrLtchRqC65112B3 : 2|2@1+ (1,0) [0|3] "-" Vector__XXX
 SG_ DrvrDrLtchRq149F144F : 0|2@1+ (1,0) [0|3] "-" Vector__XXX

BO_ 2365250814 CABIN_IO_3_ECU_CAN1_1: 1 Vector__XXX
 SG_ DrOpnStt498019DA : 3|3@1+ (1,0) [0|7] "-" Vector__XXX
 SG_ SnsdPwrDrStt36820F97 : 0|3@1+ (1,0) [0|0] "" Vector__XXX

BO_ 2365250558 REAR_IO_1_ECU_CAN1_1: 1 Vector__XXX
 SG_ RllrShttrLckAcDA7D0D03 : 0|2@1+ (1,0) [0|3] "" Vector__XXX

BO_ 2483019518 FRONT_IO_1_ECU_CAN2_2: 1 Vector__XXX
 SG_ HtdGlElmSt72F5090B : 0|2@1+ (1,0) [0|3] "" Vector__XXX

BO_ 2483019262 FRONT_IO_2_ECU_CAN1_3: 1 Vector__XXX
 SG_ HtdGlElmSt730E090D : 0|2@1+ (1,0) [0|3] "" Vector__XXX

BO_ 2483019006 FRONT_IO_3_ECU_CAN1_1: 1 Vector__XXX
 SG_ HtdGlRq3A5140AF0 : 2|2@1+ (1,0) [0|3] "" Vector__XXX
 SG_ HtdGlRq2A4F10AEE : 0|2@1+ (1,0) [0|3] "" Vector__XXX

BO_ 2566575614 CABIN_IO_2_ECU_CAN2_2: 1 Vector__XXX
 SG_ SrvcHtchLtchRq68B515C9 : 0|2@1+ (1,0) [0|3] "" Vector__XXX

BO_ 2566575358 FRONT_IO_1_ECU_CAN2_3: 1 Vector__XXX
 SG_ SnsdSrvcHtchStB1020BA1 : 0|3@1+ (1,0) [0|7] "-" Vector__XXX

BO_ 2566575102 FRONT_IO_2_ECU_CAN1_4: 1 Vector__XXX
 SG_ WshrCmd667308B4 : 0|1@1+ (1,0) [0|1] "" Vector__XXX

BO_ 2566574846 CABIN_IO_1_ECU_CAN1_2: 3 Vector__XXX
 SG_ CrgLghtEnblRqsA1B80AE4 : 19|3@1+ (1,0) [0|7] "" Vector__XXX
 SG_ CrgLghtActtRqsADA30B64 : 11|8@1+ (1,0) [0|0] "%" Vector__XXX
 SG_ LFtwlLghtIntns6C841575 : 3|8@1+ (1,0) [0|0] "%" Vector__XXX
 SG_ LFtwlLgthEnblS6CCD1577 : 0|3@1+ (1,0) [0|7] "" Vector__XXX

BO_ 2566574590 CABIN_IO_2_ECU_CAN2_3: 2 Vector__XXX
 SG_ StMtStt82CC09EE : 11|2@1+ (1,0) [0|3] "" Vector__XXX
 SG_ LFtwlLghtEnblC30200EB1 : 8|3@1+ (1,0) [0|7] "" Vector__XXX
 SG_ LFtwlLghtIntns30490EB3 : 0|8@1+ (1,0) [0|0] "%" Vector__XXX

BO_ 2566574334 REAR_IO_1_ECU_CAN1_3: 1 Vector__XXX
 SG_ CrgLghtLmp4Stt6D4D157B : 3|3@1+ (1,0) [0|7] "" Vector__XXX
 SG_ CrgLghtLmp3Stt6D161579 : 0|3@1+ (1,0) [0|7] "" Vector__XXX

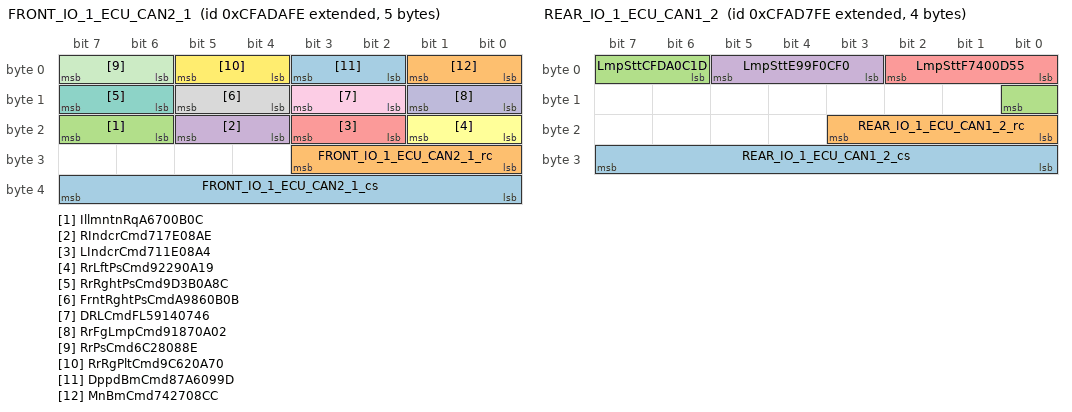
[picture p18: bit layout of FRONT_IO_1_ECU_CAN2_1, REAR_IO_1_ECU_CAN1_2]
BO_ 2365250302 FRONT_IO_1_ECU_CAN2_1: 5 Vector__XXX
 SG_ FRONT_IO_1_ECU_CAN2_1_cs : 32|8@1+ (1,0) [0|255] "" Vector__XXX
 SG_ FRONT_IO_1_ECU_CAN2_1_rc : 24|4@1+ (1,0) [0|15] "" Vector__XXX
 SG_ IllmntnRqA6700B0C : 22|2@1+ (1,0) [0|3] "" Vector__XXX
 SG_ RIndcrCmd717E08AE : 20|2@1+ (1,0) [0|3] "" Vector__XXX
 SG_ LIndcrCmd711E08A4 : 18|2@1+ (1,0) [0|3] "" Vector__XXX
 SG_ RrLftPsCmd92290A19 : 16|2@1+ (1,0) [0|3] "" Vector__XXX
 SG_ RrRghtPsCmd9D3B0A8C : 14|2@1+ (1,0) [0|3] "" Vector__XXX
 SG_ FrntRghtPsCmdA9860B0B : 12|2@1+ (1,0) [0|3] "" Vector__XXX
 SG_ DRLCmdFL59140746 : 10|2@1+ (1,0) [0|3] "" Vector__XXX
 SG_ RrFgLmpCmd91870A02 : 8|2@1+ (1,0) [0|3] "" Vector__XXX
 SG_ RrPsCmd6C28088E : 6|2@1+ (1,0) [0|3] "" Vector__XXX
 SG_ RrRgPltCmd9C620A70 : 4|2@1+ (1,0) [0|3] "" Vector__XXX
 SG_ DppdBmCmd87A6099D : 2|2@1+ (1,0) [0|3] "" Vector__XXX
 SG_ MnBmCmd742708CC : 0|2@1+ (1,0) [0|3] "" Vector__XXX

BO_ 2365249534 REAR_IO_1_ECU_CAN1_2: 4 Vector__XXX
 SG_ REAR_IO_1_ECU_CAN1_2_cs : 24|8@1+ (1,0) [0|255] "" Vector__XXX
 SG_ REAR_IO_1_ECU_CAN1_2_rc : 16|4@1+ (1,0) [0|15] "" Vector__XXX
 SG_ LmpSttCFDA0C1D : 6|3@1+ (1,0) [0|7] "" Vector__XXX
 SG_ LmpSttE99F0CF0 : 3|3@1+ (1,0) [0|7] "" Vector__XXX
 SG_ LmpSttF7400D55 : 0|3@1+ (1,0) [0|7] "" Vector__XXX

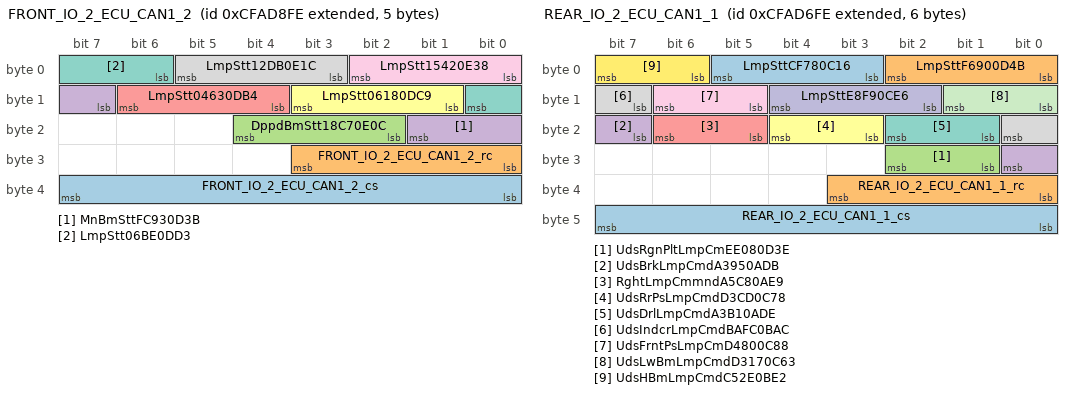
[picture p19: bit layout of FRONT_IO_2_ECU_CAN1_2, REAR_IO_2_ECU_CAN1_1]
BO_ 2365249790 FRONT_IO_2_ECU_CAN1_2: 5 Vector__XXX
 SG_ FRONT_IO_2_ECU_CAN1_2_cs : 32|8@1+ (1,0) [0|255] "" Vector__XXX
 SG_ FRONT_IO_2_ECU_CAN1_2_rc : 24|4@1+ (1,0) [0|15] "" Vector__XXX
 SG_ DppdBmStt18C70E0C : 18|3@1+ (1,0) [0|7] "" Vector__XXX
 SG_ MnBmSttFC930D3B : 15|3@1+ (1,0) [0|7] "" Vector__XXX
 SG_ LmpStt04630DB4 : 12|3@1+ (1,0) [0|7] "" Vector__XXX
 SG_ LmpStt06180DC9 : 9|3@1+ (1,0) [0|7] "" Vector__XXX
 SG_ LmpStt06BE0DD3 : 6|3@1+ (1,0) [0|7] "" Vector__XXX
 SG_ LmpStt12DB0E1C : 3|3@1+ (1,0) [0|7] "" Vector__XXX
 SG_ LmpStt15420E38 : 0|3@1+ (1,0) [0|7] "" Vector__XXX

BO_ 2365249278 REAR_IO_2_ECU_CAN1_1: 6 Vector__XXX
 SG_ REAR_IO_2_ECU_CAN1_1_cs : 40|8@1+ (1,0) [0|255] "" Vector__XXX
 SG_ REAR_IO_2_ECU_CAN1_1_rc : 32|4@1+ (1,0) [0|15] "" Vector__XXX
 SG_ UdsRgnPltLmpCmEE080D3E : 25|2@1+ (1,0) [0|3] "" Vector__XXX
 SG_ UdsBrkLmpCmdA3950ADB : 23|2@1+ (1,0) [0|3] "" Vector__XXX
 SG_ RghtLmpCmmndA5C80AE9 : 21|2@1+ (1,0) [0|3] "" Vector__XXX
 SG_ UdsRrPsLmpCmdD3CD0C78 : 19|2@1+ (1,0) [0|3] "" Vector__XXX
 SG_ UdsDrlLmpCmdA3B10ADE : 17|2@1+ (1,0) [0|3] "" Vector__XXX
 SG_ UdsIndcrLmpCmdBAFC0BAC : 15|2@1+ (1,0) [0|3] "" Vector__XXX
 SG_ UdsFrntPsLmpCmD4800C88 : 13|2@1+ (1,0) [0|3] "" Vector__XXX
 SG_ LmpSttE8F90CE6 : 10|3@1+ (1,0) [0|7] "" Vector__XXX
 SG_ UdsLwBmLmpCmdD3170C63 : 8|2@1+ (1,0) [0|3] "" Vector__XXX
 SG_ UdsHBmLmpCmdC52E0BE2 : 6|2@1+ (1,0) [0|3] "" Vector__XXX
 SG_ LmpSttCF780C16 : 3|3@1+ (1,0) [0|7] "" Vector__XXX
 SG_ LmpSttF6900D4B : 0|3@1+ (1,0) [0|7] "" Vector__XXX

CM_ BO_ 2637364990 "Request to send module information messages #\\system_software\components\lib\module_info\0.36.0.0\dbc\module_info.dbc #\\system_software\components\lib\module_info\0.36.0.0\dbc\module_info.dbc";
CM_ SG_ 2637364990 ReqAppSystemPackVersion "Request to send ModuleSystemPackVersion message";
CM_ SG_ 2637364990 ReqModuleAlive "Request to send ModuleAlive message";
CM_ SG_ 2637364990 ReqParamsInfo "Request to send ModuleParamsInfo message";
CM_ SG_ 2637364990 ReqModuleName "Request to send ModuleName message";
CM_ SG_ 2637364990 ReqHardwareName "Request to send ModuleHardwareName message";
CM_ SG_ 2637364990 ReqHardwareInfo "Request to send ModuleHardwareInfo message";
CM_ SG_ 2637364990 ReqBLVersionEx "Request to send ModuleBLVersionEx message";
CM_ SG_ 2637364990 ReqBLVersion "Request to send ModuleBLVersion message";
CM_ SG_ 2637364990 ReqBLName "Request to send ModuleBLName1 & ModuleBLName2 messages ";
CM_ SG_ 2637364990 ReqAppVersionEx "Request to send ModuleAppVersionEx message";
CM_ SG_ 2637364990 ReqAppVersion "Request to send ModuleAppVersion message";
CM_ SG_ 2637364990 ReqAppName "Request to send ModuleAppName1 & ModuleAppName2 messages ";
CM_ BO_ 2583174654 "Feedback from the Wiper Driver. #dbc\Software_Modules\Windshield_Wash_Wipe\WPRWSH\0.0.8.0\WPRWSH.dbc";
CM_ SG_ 2583174654 WiperState "Current state of the Wiper Driver.";
CM_ SG_ 2583174654 WiperHomePosition "Indicates if Wiper is in ''home position''.";
CM_ BO_ 2365552126 "E2E protection: Autosar 1A
DATAID: 0xF75 #dbc\Software_Modules\Braking_System\BRK\0.1.5.0\BrakingSystem.dbc";
CM_ SG_ 2365552126 AutoHoldMsgCks "E2E CRC";
CM_ SG_ 2365552126 AutoHoldMsgCnt "E2E Counter";
CM_ BO_ 2381871102 " #dbc\Software_Modules\Braking_System\BRK\0.1.5.0\BrakingSystem.dbc";
CM_ BO_ 2382107134 "Message with general information about current Drivetrain System state #dbc\Software_Modules\Braking_System\BRK_Status1\0.0.3.0\BRK_Status1.dbc #dbc\Software_Modules\Braking_System\BRK_Status1\0.0.3.0\BRK_Status1.dbc #dbc\Software_Modules\Braking_System\BRK_Status1\0.0.3.0\BRK_Status1.dbc";
CM_ SG_ 2382107134 BRK_EBS_Torque_Valid "Validity flag of EBS torque";
CM_ SG_ 2382107134 BRK_EBS_Torque_Demand "EBS Torque Demand";
CM_ SG_ 2382107134 BRK_System_Status "Braking system status";
CM_ SG_ 2382107134 BRK_Gear_Shift_Inhibit "Request of gear shift inhibition from the braking system";
CM_ SG_ 2382107134 BRK_EBS_Take_Control "Flag of breaking system that EBS take control of torque";
CM_ SG_ 2382107134 BRK_Torque_Intervention "Flag of torque intervention from braking system";
CM_ SG_ 2382107134 BRK_ABS_Speed_Valid "Validity of Abs speed";
CM_ SG_ 2382107134 BRK_Epb_Service_Mode "EPB is in service mode. ";
CM_ SG_ 2382107134 BRK_ReadyToDrive "Drivetrain readiness flag";
CM_ BO_ 2381844570 "Braking signals
E2E protection: Autosar 1A
DATAID: 0x810 #dbc\Components\HMI\HMI_KB_BRK\0.6.0.0\HMI_KB_BRK_DRV.dbc";
CM_ SG_ 2381844570 HMI_KB_BRK_CRC "E2E CRC";
CM_ SG_ 2381844570 HMI_KB_BRK_CNT "E2E Counter";
CM_ SG_ 2381844570 BrkEmergBrkAcv "Emergency braking active flag";
CM_ SG_ 2381844570 NetReadyToSleep "True=Ready to sleep
False=Inhibit ready to sleep / switch-off of receiving system";
CM_ SG_ 2381844570 BrkAmberTelltaleReq "A 2 bit parameter to indicate the telltale indication request:
00b = Off
01b = On
10b = Error
11b = Not Available";
CM_ SG_ 2381844570 BrkRedTelltaleReq "A 2 bit parameter to indicate the telltale indication request:
00b = Off
01b = On
10b = Error
11b = Not Available";
CM_ BO_ 2650747415 "Power state of HMI as well as OTA state #dbc\Components\HMI\Arrival_HMI\0.0.17.4\Arrival_HMI.dbc";
CM_ SG_ 2650747415 recentUserInteractions "Any of possible user interactions with HMI was detected during the configured time interval (Boolean value)
1- True,
0 -False";
CM_ SG_ 2650747415 OnScreen2 "Screen 2 is ON: 1 - true; 0 - false";
CM_ SG_ 2650747415 OnScreen1 "Screen 1 is ON: 1 - true; 0 - false";
CM_ SG_ 2650747415 OTAP "OTA in progress: 1 - true; 0 - false";
CM_ SG_ 2650747415 NA "State: 0 - NA, means others flags isn't valid;  1 - OK, means others flags are valid";
CM_ BO_ 2566899735 "DataID 0xFC8 #dbc\Components\HMI\Arrival_HMI_TS\0.0.12.2\Arrival_HMI_TS.dbc";
CM_ SG_ 2566899735 MapRecuperTorqChoice "Choice of recuperation torque map:1,2,3... - select # of Map";
CM_ SG_ 2566899735 IsMinTorqueReq "Define Is minimal torque required when pedal is not depressed";
CM_ SG_ 2566899735 HMIRequest1_counter "counter signal for E2E protection";
CM_ SG_ 2566899735 HMIRequest1_checksum "Checksum signal for E2E protection";
CM_ BO_ 2566803454 "Vehicle Dynamic Stability Control 1
Contains information which relates to the VDC system status. #dbc\j1939MISRA\0.0.8.2\j1939.dbc";
CM_ SG_ 2566803454 TrailerVDCActive "The trailer-VDC (Vehicle Dynamic Control) is an electronic vehicle stability function within the (semi) trailer braking system. It acts to stabilize the (semi) trailer during dynamic maneuvers. VDC includes Roll Over Prevention (ROP) and/or Yaw ...";
CM_ SG_ 2566803454 YCBrakeCtrlActive "State signal which indicates that Yaw Control (YC) has activated brake control. Active means that YC actually controls wheel brake pressure at one or more wheels of the vehicle or vehicle combination. Within the physical limits, YC attempts to ...";
CM_ SG_ 2566803454 YCEngCtrlActive "State Signal which indicates that the Yaw Control (YC) has commanded engine control to be active. Within the physical limits, YC attempts to prevent yawing of the vehicle. Active means that YC actually tries to control the engine. This state signal ...";
CM_ SG_ 2566803454 ROPBrakeCtrlActive "State signal which indicates that Roll over Prevention (ROP) has activated brake control. Active means that ROP actually controls wheel brake pressure at one or more wheels of the vehicle or vehicle combination. Within the physical limits, ROP ...";
CM_ SG_ 2566803454 ROPEngCtrlActive "State Signal which indicates that the Roll Over Prevention (ROP) has commanded engine control to be active. Within the physical limits, ROP attempts to prevent rolling over of the vehicle. Active means that ROP actually tries to control the engine ...";
CM_ SG_ 2566803454 VDCBrakeLightRq "Indicates whether VDC requests to turn the vehicle brake lights on

00 Turn brake light not on
01 Turn brake light on
10 Reserved
11 Don't care/Take no action";
CM_ SG_ 2566803454 VDCFullyOperational "Signal that indicates whether VDC is fully operational or whether its functionality is reduced by a permanent or temporary (e.g. low voltage) defect, by intended action (e.g. disabled by a switch or during special diagnostic procedures), not ...";
CM_ SG_ 2566803454 VDCInformationSignal "This parameter commands the VDC information signal, for example a dash lamp.

00 Off
01 On
10 Reserved
11 Don't care/Take no action";
CM_ BO_ 2399125758 "For DEBUG-TEST only! Consist of signals that can replace AIN siganls from Analog button block #dbc\Components\Comunication_module\Comm\0.0.2.0\Comm.dbc";
CM_ SG_ 2399125758 LVUpdateOTARequest "request from OTA to prepare LV for update";
CM_ BO_ 2381722110 "This lighting message is a response to the request for lighting data in the Exterior Lighting Command message. #dbc\Software_Modules\Exterior_Lights\ExtLightsSystem\0.3.4.0\ExtLightsSystem.dbc";
CM_ SG_ 2381722110 LampState "This parameter provides measured data from a center brake lamps

00 De activated
01 Activated
10 Fault Detected
11 Not Available";
CM_ BO_ 2449446910 "For DEBUG-TEST only! Consist of signals that can replace AIN siganls from Analog button block #dbc\StaticInternal\VSS\HMIUserInteract\0.1.0.0\HMIUserInteract.dbc";
CM_ SG_ 2449446910 Horn_req "Gear selector request from AI";
CM_ SG_ 2449446910 Wash_req "Gear selector request from AI";
CM_ SG_ 2449446910 Wipe_req "Gear selector request from AI";
CM_ SG_ 2449446910 MainBeam_req "Gear selector request from AI";
CM_ SG_ 2449446910 TurnInd_req "Gear selector request from AI";
CM_ SG_ 2449446910 HazardSw_req "Gear selector request from AI";
CM_ SG_ 2449446910 RightDpad "Gear selector request from AI";
CM_ SG_ 2449446910 LeftDpad_req "Gear selector request from AI";
CM_ SG_ 2449446910 rcntUserIntrcn "Gear selector request from AI";
CM_ SG_ 2449446910 StalkGS_req "Gear selector request from AI";
CM_ BO_ 2650738942 "Module main application version information #\\system_software\components\lib\module_info\0.36.0.0\dbc\module_info.dbc #\\system_software\components\lib\module_info\0.36.0.0\dbc\module_info.dbc";
CM_ SG_ 2650738942 AppVerBuild "Application build number";
CM_ SG_ 2650738942 AppVerFix "Application fix version";
CM_ SG_ 2650738942 AppVerMinor "Application minor version number";
CM_ SG_ 2650738942 AppVerMajor "Application Major version number";
CM_ SG_ 2650738942 AppVerGeneration "Application Generation number";
CM_ BO_ 2466225918 "For DEBUG-TEST only! Consist of signals that can replace AIN siganls from Analog button block #dbc\StaticInternal\VSS\HMIUserInteract\0.1.0.0\HMIUserInteract.dbc";
CM_ SG_ 2466225918 RecentUserInteract "Gear selector request from AI";
CM_ BO_ 2600457470 " #dbc\StaticInternal\VSS\NM_DBG\0.1.0.0\NM_DBG.dbc";
CM_ SG_ 2600457470 NM_Wakeup_Sys22 "DoorOrSTP";
CM_ SG_ 2600457470 NM_Wakeup_Sys21 "SeatMat";
CM_ SG_ 2600457470 NM_Wakeup_Sys14 "HVPS";
CM_ SG_ 2600457470 NM_Wakeup_Sys12 "HVBS";
CM_ SG_ 2600457470 NM_Wakeup_Sys7 "LV";
CM_ SG_ 2600457470 NM_Wakeup_Sys6 "Comm";
CM_ SG_ 2600457470 NM_Wakeup_Sys5 "HMIUsrIntrctn";
CM_ SG_ 2600457470 NM_Wakeup_Sys3 "CHRG";
CM_ SG_ 2600457470 NM_Wakeup_Sys1 "Security";
CM_ SG_ 2600457470 NM_Ready2Sleep_Sys15 "Thermal";
CM_ SG_ 2600457470 NM_Ready2Sleep_Sys14 "HV";
CM_ SG_ 2600457470 NM_Ready2Sleep_Sys13 "STR";
CM_ SG_ 2600457470 NM_Ready2Sleep_Sys12 "HVBS";
CM_ SG_ 2600457470 NM_Ready2Sleep_Sys11 "ELS";
CM_ SG_ 2600457470 NM_Ready2Sleep_Sys10 "DT";
CM_ SG_ 2600457470 NM_Ready2Sleep_Sys9 "CAS";
CM_ SG_ 2600457470 NM_Ready2Sleep_Sys8 "CMS";
CM_ SG_ 2600457470 NM_Ready2Sleep_Sys7 "LV";
CM_ SG_ 2600457470 NM_Ready2Sleep_Sys6 "Comm";
CM_ SG_ 2600457470 NM_Ready2Sleep_Sys5 "
HMI";
CM_ SG_ 2600457470 NM_Ready2Sleep_Sys4 "HMI_KB_BRK";
CM_ SG_ 2600457470 NM_Ready2Sleep_Sys3 "CHRG";
CM_ SG_ 2600457470 NM_Ready2Sleep_Sys2 "ADS";
CM_ SG_ 2600457470 NM_Ready2Sleep_Sys1 "Security";
CM_ SG_ 2600457470 NM_VSMFullySleep "VSM Fully Sleep and HWOk and SpdOk ";
CM_ SG_ 2600457470 NM_MNG_ShtDwnTimer "Shutdown timer expired";
CM_ SG_ 2600457470 NM_MNG_ShtDwnSysRdy "shut down timer systems checks: all needed systems are ready to sleep";
CM_ SG_ 2600457470 NM_Ready2Sleep_Inv "Inverter ready2sleep";
CM_ SG_ 2600457470 NM_SlaveSleepCmd "Flag that there's at least one active cmd to sleep slaves
";
CM_ SG_ 2600457470 NM_SlaveWakeupCmd "Flag that there's at least one active cmd to wake up slaves";
CM_ BO_ 2600457726 " #dbc\StaticInternal\VSS\NM_DBG\0.1.0.0\NM_DBG.dbc";
CM_ BO_ 2600457982 " #dbc\StaticInternal\VSS\NM_DBG\0.1.0.0\NM_DBG.dbc";
CM_ BO_ 2381395454 " #dbc\Software_Modules\Thermal_System\Thermal\0.2.0.0\Thermal.dbc";
CM_ BO_ 2650742782 "Request to send module information messages #\\system_software\components\lib\system_software_base\0.36.1.0\maintenance_status\dbc\maintenance_status.dbc #\\system_software\components\lib\system_software_base\0.36.1.0\maintenance_status\dbc\maintenance_status.dbc #\\system_software\components\lib\system_software_base\0.36.1.0\maintenance_status\dbc\maintenance_status.dbc";
CM_ SG_ 2650742782 DiagReportsEnabled "Diagnostic reports enabled";
CM_ SG_ 2650742782 FirmwareUpdateEnabled "Firmware update enabled";
CM_ BO_ 2600459518 " #dbc\StaticInternal\VSS\SimpVSM_DBG\0.1.0.0\SimpVSM_DBG.dbc";
CM_ BO_ 2515951358 " #dbc\StaticInternal\DTS\DTS_Flt_Mntr_DBG\0.1.0.0\DTS_Flt_Mntr_DBG.dbc";
CM_ BO_ 2515951102 " #dbc\StaticInternal\DTS\DTS_Flt_Mntr_DBG\0.1.0.0\DTS_Flt_Mntr_DBG.dbc";
CM_ BO_ 2515950846 " #dbc\StaticInternal\DTS\DTS_Flt_Mntr_DBG\0.1.0.0\DTS_Flt_Mntr_DBG.dbc";
CM_ BO_ 2180407550 " #dbc\Software_Modules\Drivetrain_System\DTS_Flt_Mng\0.0.3.0\DTS_Flt_Mng.dbc";
CM_ SG_ 2180407550 DCUHMIMsgCks "Message checksum to verify the signal path from the demanding device to the controller.
Calculated according to AUTOSAR profile 1A";
CM_ SG_ 2180407550 DCUHMIMsgCtr "Message counter to verify the signal path from the demanding device to the controller";
CM_ BO_ 2515950590 " #dbc\StaticInternal\DTS\DTS_Flt_Mntr_DBG\0.1.0.0\DTS_Flt_Mntr_DBG.dbc";
CM_ BO_ 2515950334 " #dbc\StaticInternal\DTS\DTS_Flt_Mntr_DBG\0.1.0.0\DTS_Flt_Mntr_DBG.dbc";
CM_ BO_ 2515950078 " #dbc\StaticInternal\DTS\DTS_Flt_Mntr_DBG\0.1.0.0\DTS_Flt_Mntr_DBG.dbc";
CM_ BO_ 2381867518 "Message with general information about current Drivetrain Controller state #dbc\Software_Modules\Drivetrain_System\ArrivalDTC\0.0.3.0\ArrivalDTC.dbc";
CM_ SG_ 2381867518 DTReadyToSleep "Drivetrain readiness flag";
CM_ SG_ 2381867518 DTReadyToDrive "Drivetrain readiness flag";
CM_ BO_ 2180416766 "Drivetrain Fault Manager Debug #dbc\StaticInternal\DTS\DTS_Flt_Mntr_DBG\0.1.0.0\DTS_Flt_Mntr_DBG.dbc";
CM_ BO_ 2381971966 "Message with general information about current Drivetrain System state #dbc\Software_Modules\Drivetrain_System\DTS_Status1\0.0.3.0\DTS_Status1.dbc #dbc\Software_Modules\Drivetrain_System\DTS_Status1\0.0.3.0\DTS_Status1.dbc #dbc\Software_Modules\Drivetrain_System\DTS_Status1\0.0.3.0\DTS_Status1.dbc";
CM_ SG_ 2381971966 DTS_Standstill "Is the vehicle stationary or not?";
CM_ SG_ 2381971966 DTS_VehicleSpeed "Signed Vehicle Speed";
CM_ SG_ 2381971966 DTS_BrkPedlPosn "is brake pedal pressed";
CM_ SG_ 2381971966 DT_ReadyToSleep "IDU readiness flag";
CM_ SG_ 2381971966 DTS_AccrPedlSw "is accelerator pedal pressed";
CM_ SG_ 2381971966 DTS_BrkPedlSw "Drivetrain system status";
CM_ SG_ 2381971966 DTS_VehMoveDir "Vehicle Directionv Movement state";
CM_ SG_ 2381971966 DTS_ReadyToSleep "Drivetrain readiness flag";
CM_ SG_ 2381971966 DTS_SystemStatus "Drivetrain readiness flag";
CM_ SG_ 2381971966 DTS_ReadyToDrive "Drivetrain readiness flag";
CM_ SG_ 2381971966 DTS_IgnitionStatus "KL15 Ignition line state";
CM_ BO_ 2381972734 "Message with general information about current Drivetrain System state #dbc\Software_Modules\Drivetrain_System\DTS_Status4\0.0.3.0\DTS_Status4.dbc #dbc\Software_Modules\Drivetrain_System\DTS_Status4\0.0.3.0\DTS_Status4.dbc #dbc\Software_Modules\Drivetrain_System\DTS_Status4\0.0.3.0\DTS_Status4.dbc";
CM_ SG_ 2381972734 DTS_MotorTorque "motor speed feedback";
CM_ SG_ 2381972734 DTS_MotorSpeed "motor speed feedback";
CM_ BO_ 2381972478 "Message with general information about current Drivetrain System state #dbc\Software_Modules\Drivetrain_System\DTS_Status3\0.0.3.0\DTS_Status3.dbc #dbc\Software_Modules\Drivetrain_System\DTS_Status3\0.0.3.0\DTS_Status3.dbc #dbc\Software_Modules\Drivetrain_System\DTS_Status3\0.0.3.0\DTS_Status3.dbc";
CM_ SG_ 2381972478 DTS_IDU_InvTemp1 "Drivetrain System Inverter Temperature1";
CM_ SG_ 2381972478 DTS_IDU_MotTemp1 "Drivetrain System Motor Temperature1";
CM_ SG_ 2381972478 DTS_IDU_DCCurrent "Drivetrain System IDU DC Voltage";
CM_ SG_ 2381972478 DTS_IDU_DCVoltage "Drivetrain System IDU DC Voltage";
CM_ BO_ 2381972222 "Message with general information about current Drivetrain System state #dbc\Software_Modules\Drivetrain_System\DTS_Status2\0.0.7.0\DTS_Status2.dbc #dbc\Software_Modules\Drivetrain_System\DTS_Status2\0.0.7.0\DTS_Status2.dbc #dbc\Software_Modules\Drivetrain_System\DTS_Status2\0.0.7.0\DTS_Status2.dbc";
CM_ SG_ 2381972222 DTS_Stalk_Request "There is a valid request from Stalk at current moment or not";
CM_ SG_ 2381972222 DTS_P_Button "State of P button of stalks";
CM_ SG_ 2381972222 DTS_IDU_ShortCirc "0 - Ok
1 - Short Circuit";
CM_ SG_ 2381972222 DTS_IDU_HV_CheckState "0 - HV not ready
1 - HV ready";
CM_ SG_ 2381972222 DTS_SysSt_ParkLock "Drivetrain system status";
CM_ SG_ 2381972222 DTS_SysSt_IDU "Drivetrain system status";
CM_ BO_ 2180407294 " #dbc\StaticInternal\DTS\DTS_Flt_Mntr_DBG\0.1.0.0\DTS_Flt_Mntr_DBG.dbc";
CM_ BO_ 2399110910 " #dbc\StaticInternal\DTS\DVT\0.1.0.0\DVT.dbc";
CM_ SG_ 2399110910 RSPDL_DT_OUT "Reactive speed limitaion torque filter

";
CM_ SG_ 2399110910 ORTL_DT_OUT "Overall reference torque limitator";
CM_ SG_ 2399110910 DTF_DemTrq_OUT "Demanded torque filter";
CM_ SG_ 2399110910 EBS_TorqueRequest "Signal from EBS - Torque request";
CM_ BO_ 2399111166 " #dbc\StaticInternal\DTS\DVT\0.1.0.0\DVT.dbc";
CM_ SG_ 2399111166 EPLC_ElPwrReqLim "Electric power limit calculation";
CM_ SG_ 2399111166 EPLC_ElPwrDischLim "Electric power limit calculation";
CM_ SG_ 2399111166 AccTR_TrqDem "Acceleration torque regulator: TorqueDemandDriver";
CM_ SG_ 2399111166 ARB_DT_DT "Arbitrator of Demanded torque";
CM_ BO_ 2399109630 " #dbc\StaticInternal\DTS\DVT\0.1.0.0\DVT.dbc";
CM_ SG_ 2399109630 DTF_TqLPF_TauTime "DTF LPF Tau Timeconst sec";
CM_ SG_ 2399109630 DrRA_Acc_Req "Driver request analysis: acceleration request";
CM_ SG_ 2399109630 DTF_TqRateLimDwn "DTF Torque rate limit down";
CM_ SG_ 2399109630 DTF_TqRateLimUp "DTF Torque Rate limit up";
CM_ SG_ 2399109630 RPLIM_T_OUT "Reactive Power limitaion torque filter";
CM_ BO_ 2600438270 "Diagnostics message #dbc\StaticInternal\DTS\DVT\0.1.0.0\DVT.dbc";
CM_ SG_ 2600438270 DTF_TqLPFIsOn "DTF Low pass filter LPF Is On";
CM_ SG_ 2600438270 DTF_TqLimRateIsOn "DTF Rate limiter Is On";
CM_ SG_ 2600438270 DTF_DiagWarning "DTF Diagnostics Warning is active";
CM_ SG_ 2600438270 DTF_TqPreprocIsOn "DTF TorquePreprocessing is On";
CM_ SG_ 2600438270 ARB_DT_isTTAllow "IsTractionTorqueAllowed";
CM_ SG_ 2600438270 ARB_DT_isRTAllow "IsRegenerationTorqueAllowed";
CM_ SG_ 2600438270 TTDerRPLim "Traction torque is derated by reactive power limitation";
CM_ SG_ 2600438270 ARB_DT_TrqProhib "IsTorqueProhibited";
CM_ SG_ 2600438270 TrqProactLim "Overall torque was proactively limited, flag";
CM_ SG_ 2600438270 ARB_DT_CD "Signal for requesting torque control source.";
CM_ SG_ 2600438270 ARB_CD_blocked "Control Demand block";
CM_ SG_ 2600438270 ORTL_ITLimFlag "Is torque proactive limited";
CM_ SG_ 2600438270 DT_GearBox_fault_st "Arbitrator of Demanded torque";
CM_ SG_ 2600438270 DT_system_warn_st "Arbitrator of Demanded torque";
CM_ SG_ 2600438270 MapChckSt "Calibration tables for pedal mapping check status";
CM_ SG_ 2600438270 EBS_SrcValFlag "EBS source is valid flag";
CM_ SG_ 2600438270 IntSpdValFlag "Internal speed validity flag";
CM_ SG_ 2600438270 DefDistribInUse "Diagnostic flag about using default distribution (1- default distribution is using)";
CM_ SG_ 2600438270 CtrlSrcSelBlckd "1 - Selection of control source is blocked, flag";
CM_ SG_ 2600438270 AccTR_Prms_Incorr "1 - Parameters with AccTR prefix is invalid";
CM_ SG_ 2600438270 AI_SrcValFlag "Demand from AI is valid";
CM_ SG_ 2600438270 DefDistribUnavail "Diagnostic flag indicating that default distribution is not possible to set (1- default distribution is not possible to set)";
CM_ SG_ 2600438270 ChosenCtrlSrc "Chosen control source";
CM_ BO_ 2600439038 "Overall limits message with information about limitation acting. #dbc\StaticInternal\DTS\DVT\0.1.0.0\DVT.dbc";
CM_ SG_ 2600439038 OvrlRTLim "Overall recuperation torque limit";
CM_ SG_ 2600439038 OvrlTTLim "Overall traction torque limit";
CM_ BO_ 2381399806 " #dbc\StaticInternal\DTS\DVT\0.1.0.0\DVT.dbc";
CM_ SG_ 2381399806 LMP_LimpReqSrc7 "Limp mode torque limit source 1: Ramp";
CM_ SG_ 2381399806 LMP_LimpReqSrc6 "Limp mode torque limit source 1: Ramp";
CM_ SG_ 2381399806 LMP_LimpReqSrc5 "Limp mode torque limit source 5: DOOR
";
CM_ SG_ 2381399806 LMP_LimpReqSrc4 "Limp mode torque limit source 4: SUSP";
CM_ SG_ 2381399806 LMP_LimpReqSrc3 "Limp mode torque limit source 1: STEERING
";
CM_ SG_ 2381399806 LMP_LimpReqSrc2 "Limp mode torque limit source 1: BRAKE
";
CM_ SG_ 2381399806 LMP_LimpReqSrc1 "Limp mode torque limit source 1: HV";
CM_ SG_ 2381399806 RSPDL_IsTqLimdBySpdLim "RSPDL_ITLSL: IsTorqueLimitedBySpeedLimit Torque Reactive speed limitaion - speed limit achieved, Traction torque is limited by speed limitation";
CM_ SG_ 2381399806 VSLC_IsIntSpdLimAcv "IsInternalSpeedLimitActive: True mean that an internal vehicle speed limitation is set.";
CM_ BO_ 2382314750 "For DEBUG-TEST only! Consist of signals that can replace AI GS Request, HMI 3 GS Request and state of gearbox interlock signals. #dbc\StaticInternal\DTS\GS_DBG\0.1.0.0\GS_DBG.dbc";
CM_ SG_ 2382314750 Stalk_GS_P_valid "Request of P button is valid or not";
CM_ SG_ 2382314750 Stalk_GS_Req "Flag  of the AI request inaccessibility. If it is true then AI GS request signal is valid but not correct in current circumstances";
CM_ SG_ 2382314750 Stalk_GS_NRD_valid "Request of NRD stalk is valid or not";
CM_ SG_ 2382314750 Stalk_GS_NRD_state "1-R,  2 - N, 4 - D, 6 - NOT VALID";
CM_ SG_ 2382314750 EXHAN_ActCondition "Flag  of the AI request inaccessibility. If it is true then AI GS request signal is valid but not correct in current circumstances";
CM_ SG_ 2382314750 EXHAN_ActScenario "Flag  of the AI request inaccessibility. If it is true then AI GS request signal is valid but not correct in current circumstances";
CM_ SG_ 2382314750 EXHAN_GS_AllowReqVec "[1- P; 2 - N; 3 - D; 4 - R; 5 - PD; 6  - PR] each element signalize about the allowance of particular state via true value
";
CM_ SG_ 2382314750 EXHAN_FinalGSReq "Flag  of the AI request inaccessibility. If it is true then AI GS request signal is valid but not correct in current circumstances";
CM_ SG_ 2382314750 EXHAN_VSMGSReq "Flag  of the AI request inaccessibility. If it is true then AI GS request signal is valid but not correct in current circumstances";
CM_ SG_ 2382314750 EXHAN_ChsnGSReqValid "Flag  of the AI request inaccessibility. If it is true then AI GS request signal is valid but not correct in current circumstances";
CM_ SG_ 2382314750 EXHAN_ChsnGSReq "Flag  of the AI request inaccessibility. If it is true then AI GS request signal is valid but not correct in current circumstances";
CM_ BO_ 2382315006 "For DEBUG-TEST only! Consist of signals that can replace AI GS Request, HMI 3 GS Request and state of gearbox interlock signals. #dbc\StaticInternal\DTS\GS_DBG\0.1.0.0\GS_DBG.dbc";
CM_ SG_ 2382315006 FLTMNG_DT_DirectionCmd "FAULTMNGR_GS: DT_DirectionCmd";
CM_ SG_ 2382315006 FLTMNG_ParkBrake_Cmd "FAULTMNGR_GS: ParkBrake_Cmd_Safe";
CM_ SG_ 2382315006 FLTMNG_Interlock_Cmd "FAULTMNGR_GS: Interlock_Cmd_Safe";
CM_ SG_ 2382315006 FLTMNG_DT_StateCmd "FAULTMNGR_GS: DT_StateCmd_Safe";
CM_ BO_ 2399117822 "For DEBUG-TEST only! Consist of signals that can replace AI GS Request, HMI 3 GS Request and state of gearbox interlock signals. #dbc\StaticInternal\DTS\GS_DBG\0.1.0.0\GS_DBG.dbc";
CM_ SG_ 2399117822 Stalk_GS_NRD_ch1 "Stalk_GS_NRD_ch1";
CM_ SG_ 2399117822 Stalk_GS_NRD_ch2 "Stalk_GS_NRD_ch2";
CM_ SG_ 2399117822 Stalk_GS_P_ch2 "Stalk_GS_P_ch2";
CM_ SG_ 2399117822 Stalk_GS_P_ch1 "Stalk_GS_P_ch1";
CM_ BO_ 2381739774 "For DEBUG-TEST only! Consist of signals that can replace AI GS Request, HMI 3 GS Request and state of gearbox interlock signals. #dbc\GearSelector\GS_FLT\0.1.4.0\GS_FLT.dbc";
CM_ BO_ 2381740030 "For DEBUG-TEST only! Consist of signals that can replace AI GS Request, HMI 3 GS Request and state of gearbox interlock signals. #dbc\GearSelector\GS_FLT\0.1.4.0\GS_FLT.dbc";
CM_ BO_ 2566900247 " #dbc\Vehicles\Van_Beta\Arrival_dcu_Van\0.1.0.0\Arrival_dcu_Van.dbc";
CM_ BO_ 2566906110 "For DEBUG-TEST only! Consist of signals that can replace AIN , DIN and other input signals of DCU    #dbc\Vehicles\Van_Beta\Arrival_dcu_Van\0.1.0.0\Arrival_dcu_Van.dbc";
CM_ SG_ 2566906110 AccelMeasure "Accelerometer readings";
CM_ BO_ 2381855998 " #dbc\Software_Modules\DPad\0.1.6.0\DPad.dbc";
CM_ BO_ 882 " #dbc\Third_party_components\META_DCDC\META_DCDC_MSCXX1003\0.0.5.0\META_DCDC_MSCXX1003.dbc";
CM_ SG_ 882 VCU_DCDCActivation "Invalid value 0x03";
CM_ SG_ 882 VCU_DCDCVoltageReq "InvaildValue0x7F";
CM_ BO_ 2399123198 "Message with the 1st LV DCDC status information #dbc\Software_Modules\LV_System\LVSYSOP\0.2.9.0\LVSYSOP.dbc";
CM_ SG_ 2399123198 DCDC_HVIL_Status "DCDC High Voltage Interlock Loop Status";
CM_ SG_ 2399123198 CriticalHVCompFault "Critical HV component fault";
CM_ SG_ 2399123198 DCDC_CommunicationOk "DCDC communication Ok flag";
CM_ SG_ 2399123198 DCDC_Temperature "DCDC temperature";
CM_ SG_ 2399123198 DCDC_OutputVoltage "DCDC output voltage";
CM_ SG_ 2399123198 DCDC_InputCurrent "DCDC input current";
CM_ SG_ 2399123198 DCDC_InputVoltage "DCDC input voltage";
CM_ SG_ 2399123198 DCDC_OutputCurrent "DCDC output current";
CM_ BO_ 2314626046 "Clearance Calculation Information
The Clearance Calculation Information message shall provide a calculation value of vehicle ride height, pitch angle and status of these signals #dbc\Software_Modules\Slope_Sensor_Information\Clearance\0.0.6.0\Clearance.dbc";
CM_ SG_ 2314626046 VehPitchAngle "Vehicle Pitch Angle";
CM_ SG_ 2314626046 VehPitchAngleFigureOfMerit "Figure of merit for vehicle pitch angle measurement.

00 - Vehicle pitch angle fully functional.  Data is within sensor specification. 
01 - Vehicle pitch angle degraded.  Data is suspect due to environmental conditions.
10 - Error
11 - Not available";
CM_ SG_ 2314626046 VehRideHeightFigureOfMerit "Figure of merit for vehicle ride height measurement.

00 - Vehicle ride height fully functional.  Data is within sensor specification. 
01 - Vehicle ride height degraded.  Data is suspect due to environmental conditions.
10 - Error
11 - Not available";
CM_ SG_ 2314626046 VehRideHeight "Minimum value from ride height sensors measured on axles including distance unsprung mass";
CM_ BO_ 2582780183 "Cargo Lighting HMI Request #dbc\Components\HMI\Lights\0.0.9.0\IntLightsSystem.dbc";
CM_ SG_ 2582780183 CargoLightModeHmiReq "Indicates the cargo lighting mode request from HMI.";
CM_ BO_ 2582781182 " #dbc\Components\HMI\Lights\0.0.9.0\IntLightsSystem.dbc";
CM_ SG_ 2582781182 CargoLightModeAuto "Indicates whether the cargo light is in auto mode";
CM_ BO_ 2582780670 " #dbc\Components\HMI\Lights\0.0.9.0\IntLightsSystem.dbc";
CM_ SG_ 2582780670 CargoLightStateAct "Indicates the actual state of the cargo light.";
CM_ BO_ 2365556990 "The Blind Spot Monitoring 1 message includes the function state and required warning for systems that are monitoring zone around the vehicle. #dbc\Software_Modules\ADAS\BSM\0.2.1.0\BSM.dbc";
CM_ SG_ 2365556990 BsmSt "Current operational state of the blind spot monitroing function. 

0000b = system is not ready (initialization not finished) 
0001b = system is temporarily not available (e.g. due to boundary conditions necessary for operation) 
0010b = system ...";
CM_ BO_ 2365557246 "This message is a feedback for BSM mirror indicators #dbc\Software_Modules\ADAS\BSM\0.2.1.0\BSM.dbc";
CM_ SG_ 2365557246 BsmWarnLampStRi "This parameter provides measured data from a Blind Spot Monitoring lamp indicators

00 De activated
01 Activated
10 Fault Detected
11 Not Available";
CM_ SG_ 2365557246 BsmWarnLampStLe "This parameter provides measured data from a Blind Spot Monitoring lamp indicators

00 De activated
01 Activated
10 Fault Detected
11 Not Available";
CM_ BO_ 2381860350 " #dbc\Software_Modules\Exterior_Lights\HMI_ELS\0.1.6.0\HMI_ELS.dbc";
CM_ BO_ 2583173630 "Washer faults & status from the Washer Controller. #dbc\Software_Modules\Windshield_Wash_Wipe\WPRWSH\0.0.8.0\WPRWSH.dbc";
CM_ SG_ 2583173630 WasherState "Current state of the Washer Driver.";
CM_ SG_ 2583173630 WasherSilenceFault "Indicates if Washer Driver feedback is not on CAN network.";
CM_ SG_ 2583173630 WasherControlFault "Indicates if Washer failed to execute command from the Washer Controller.";
CM_ BO_ 2381723646 " #dbc\Software_Modules\Thermal_System\Climate_System\0.3.1.0\Climate_System.dbc";
CM_ BO_ 2373975806 " #dbc\Components\HMI\Smart_TP\0.2.5.0\SmartTP.dbc";
CM_ BO_ 2381855742 " #dbc\Software_Modules\DPad\0.1.6.0\DPad.dbc";
CM_ BO_ 2448966142 "Primary battery readings #dbc\Software_Modules\LV_System\LVSYSOP\0.2.9.0\LVSYSOP.dbc";
CM_ SG_ 2448966142 BattSoH "battery state of health";
CM_ SG_ 2448966142 BattTemperature "battery temperature";
CM_ SG_ 2448966142 BmsFault "battery managment system fault state";
CM_ SG_ 2448966142 BattFault "battery fault state";
CM_ SG_ 2448966142 BattCurrent "battery current";
CM_ SG_ 2448966142 BattVoltage "battery voltage";
CM_ SG_ 2448966142 BattSoc "battery state of charge";
CM_ BO_ 2381859582 "Requests from HMI to ELS #dbc\Software_Modules\Exterior_Lights\HMI_ELS\0.1.6.0\HMI_ELS.dbc";
CM_ SG_ 2381859582 AutoLowBeamReq "Request to activate auto low beam operation";
CM_ BO_ 2180924158 " #dbc\Components\BMS\Arrival_Charging_Controller\0.1.14.0\Arrival_Charging_Controller.dbc";
CM_ SG_ 2180924158 HV_TotalActualCurrent "Actual charging current.";
CM_ SG_ 2180924158 CC_ExtFeedbackReq "Signal used for visual and audiable display of charging status (lights and sounds).";
CM_ SG_ 2180924158 CC_CriticalChargeSysFault "Will present a request to HVSO to shutdown HV when all safety measures of the Charging system fail to shutdown the system in case of a fault:
Request HV Emergency Disconnect : True
Do not Request HV Emergency Disconnect: False";
CM_ SG_ 2180924158 CC_ReadyToSleep "Charge controller ready to sleep status.";
CM_ SG_ 2180924158 CC_HealthStatus "CC Health Status.";
CM_ SG_ 2180924158 DC_ChrgContactorState "State of DC Charging Contactors.";
CM_ SG_ 2180924158 AC_ActualACChargingState "Actual AC Charging State";
CM_ SG_ 2180924158 DC_ActualDCChargingState "DC charging state";
CM_ SG_ 2180924158 CCI_ActualChargingState "Actual Charging Control and Indication state";
CM_ SG_ 2180924158 CCI_ACDCPortPlugType "ACDC charging port plug type";
CM_ SG_ 2180924158 CCI_ACPortPlugType "AC charging port plug type";
CM_ SG_ 2180924158 SysState_Counter "Counter for CHRG_SysState message";
CM_ SG_ 2180924158 SysState_CRC "CRC for CHRG_SysState message";
CM_ BO_ 2381859838 "Status of ELS to HMI #dbc\Software_Modules\Exterior_Lights\HMI_ELS\0.1.6.0\HMI_ELS.dbc";
CM_ SG_ 2381859838 AutoLowBeamSts "This parameter provides auto low beam state";
CM_ BO_ 2381860606 "Requests from HMI to ELS #dbc\Software_Modules\Exterior_Lights\HMI_ELS\0.1.6.0\HMI_ELS.dbc";
CM_ BO_ 2583184638 "The message contains the manual request for headlamps height  from HMI
HDLGHTLVL 1.0.0->ManualLevellingHeadlamps #dbc\Components\HMI\Arrival_HMI_TS\0.0.12.2\Arrival_HMI_TS.dbc";
CM_ BO_ 2583108606 "Debug signal to monitor the pin command #dbc\Software_Modules\LV_System\PinPwrDrvrDbg\0.0.1.0\PinPwrDrvrDbg.dbc";
CM_ SG_ 2583108606 PinCommand "PWM %";
CM_ BO_ 2582767102 " #dbc\Software_Modules\Safety_System\Alarm_system\0.1.2.0\ALARMDRV.dbc";
CM_ SG_ 2582767102 Master0_Code "Master code value ";
CM_ SG_ 2582767102 Alarm_Silence_request "Silence alarm request";
CM_ SG_ 2582767102 Tilt_Arm_Disarm "Tilt alarm arm or disarm request ";
CM_ SG_ 2582767102 USS_Arm_Disarm "Ultrasonic alarm arm or disarm request";
CM_ SG_ 2582767102 MW_Arm_Disarm "MW alarm arm or disarm request ";
CM_ SG_ 2582767102 ACU_arm_disarm "ACU arm disarm request";
CM_ BO_ 2583175166 "Message with wiper status #dbc\Software_Modules\Windshield_Wash_Wipe\WPRWSH\0.0.8.0\WPRWSH.dbc";
CM_ SG_ 2583175166 WipeArbRequest "Represent selected wiper status for HMI";
CM_ BO_ 2365553406 " #dbc\Software_Modules\DPad\0.1.6.0\DPad.dbc";
CM_ SG_ 2365553406 DPadCruiseControlReq "Status of Mirror Adjastment mode request from HMI(Requested /not requested)";
CM_ SG_ 2365553406 DpadVoiceAssistReq "Status of Mirror Adjastment mode request from HMI(Requested /not requested)";
CM_ SG_ 2365553406 ExtMirrorAdjReqHMI "Status of Mirror Adjastment mode request from HMI(Requested /not requested)";
CM_ BO_ 2566627838 " #dbc\Software_Modules\LV_System\LVSysDebug\0.0.2.0\LVSysDebug.dbc";
CM_ BO_ 2583047422 " #dbc\Software_Modules\Closures_System\DebugOutputs\0.1.0.0\DebugOutputs.dbc";
CM_ BO_ 2583047678 " #dbc\Software_Modules\Closures_System\DebugOutputs\0.1.0.0\DebugOutputs.dbc";
CM_ BO_ 2399122430 "Message with LV info #dbc\Software_Modules\LV_System\LVSYSOP\0.2.9.0\LVSYSOP.dbc";
CM_ SG_ 2399122430 HVTotActCurrent "Total current of all DCDC";
CM_ SG_ 2399122430 HVMinPowerReq "Minimal Power for LV processing";
CM_ BO_ 837 " #dbc\Third_party_components\META_DCDC\META_DCDC_MSCXX1003\0.0.5.0\META_DCDC_MSCXX1003.dbc";
CM_ SG_ 837 DCDC_InputVoltage "default value 0x00,
Invalid value 0x1FF";
CM_ SG_ 837 DCDC_Fault "bit6-7:Indicates the severity of the problem
0x00 Abnormal warning  
0x01 Serious fault  
0x02 Temporary fatal  
0x03 Permanent damage 
bit0-5: Indicates the type of fault";
CM_ BO_ 2566847742 "Dash Display 1 #dbc\j1939MISRA\0.0.8.2\j1939.dbc";
CM_ SG_ 2566847742 EngOilFilterDiffPress7471 "Change in engine oil pressure, measured across the filter, due to the filter and any accumulation of solid or semisolid material on or in the filter. See SPN 99 for alternate resolution.";
CM_ SG_ 2566847742 FuelLevel2 "Ratio of volume of fuel to the total volume of fuel in the second or right-side storage container.  When Fuel Level 2 is not used, Fuel Level 1 (SPN 96) represents the total fuel in all fuel storage containers.";
CM_ SG_ 2566847742 CargoAmbientTemp "Temperature of air inside vehicle container used to accommodate cargo.";
CM_ SG_ 2566847742 EngOilFilterDiffPress "Change in engine oil pressure, measured across the filter, due to the filter and any accumulation of solid or semisolid material on or in the filter.  See SPN 7471 for alternate resolution.";
CM_ SG_ 2566847742 EngFuelFilterDiffPress "Change in fuel delivery pressure, measured across the filter, due to accumulation of solid or semisolid matter on the filter element.";
CM_ SG_ 2566847742 FuelLevel1 "Ratio of volume of fuel to the total volume of fuel storage container.
When Fuel Level 2 (SPN 38) is not used, Fuel Level 1 represents the total fuel in all fuel storage containers.  When Fuel Level 2 is used, Fuel Level 1 represents the fuel level ...";
CM_ SG_ 2566847742 WasherFluidLevel "Ratio of volume of liquid to total container volume of fluid reservoir in windshield wash system.";
CM_ BO_ 2583064318 " #dbc\Software_Modules\Closures_System\CabinDoors\0.2.2.0\CabinDoors.dbc";
CM_ BO_ 2582780695 "The message containing the request on cabin light sources from the operator's cargo light control switch(s). #dbc\Components\HMI\Lights\0.0.9.0\IntLightsSystem.dbc";
CM_ SG_ 2582780695 RFtwlLightIntensityReq "Indicates the cabin light intensity level request from HMIIndicates the cabin light intensity level request from HMI";
CM_ SG_ 2582780695 RFtwlLightEnableReq "Indicates the cabin light enable request from HMIIndicates the cabin light enable request from HMI";
CM_ SG_ 2582780695 LFtwlLightIntensityReq "Indicates the cabin light intensity level request from HMIIndicates the cabin light intensity level request from HMI";
CM_ SG_ 2582780695 LFtwlLightEnableReq "Indicates the cabin light enable request from HMIIndicates the cabin light enable request from HMI";
CM_ SG_ 2582780695 PassLightIntensityReq "Indicates the cabin light intensity level request from HMIIndicates the cabin light intensity level request from HMI";
CM_ SG_ 2582780695 DriverLightIntensityReq "Indicates the cabin light intensity level request from HMIIndicates the cabin light intensity level request from HMI";
CM_ SG_ 2582780695 PassLightEnableReq "Indicates the cabin light enable request from HMIIndicates the cabin light enable request from HMI";
CM_ SG_ 2582780695 DriverLightEnableReq "Indicates the cabin light enable request from HMIIndicates the cabin light enable request from HMI";
CM_ SG_ 2582780695 VestLightEnaReq "User input for controlling the ON/OFF state of the vestibule light";
CM_ SG_ 2582780695 IndHaloLightEnaReq "User input for controlling the ON/OFF state of the indirect and halo lights";
CM_ SG_ 2582780695 CabLightColorReq "Indicates the cabin light color request from HMI.";
CM_ SG_ 2582780695 CabLightIntensityReq "Indicates the cabin light intensity level request from HMIIndicates the cabin light intensity level request from HMI";
CM_ SG_ 2582780695 CabLightEnableReq "Indicates the cabin light enable request from HMIIndicates the cabin light enable request from HMI";
CM_ BO_ 2582781438 "The message is a response to the request for lighting data in the Cabin Lighting Request message. #dbc\Components\HMI\Lights\0.0.9.0\IntLightsSystem.dbc";
CM_ SG_ 2582781438 RFtwlLightModeAuto "Indicates whether the cabin light is in auto modeIndicates whether the cabin light is in auto mode";
CM_ SG_ 2582781438 RFtwlLightIntensityState "Indicates the cabin light intensity level state.Indicates the cabin light intensity level state.";
CM_ SG_ 2582781438 RFtwlLightEnableState "Indicates the cabin light enable state.Indicates the cabin light enable state.";
CM_ SG_ 2582781438 LFtwlLightModeAuto "Indicates whether the cabin light is in auto modeIndicates whether the cabin light is in auto mode";
CM_ SG_ 2582781438 LFtwlLightIntensityState "Indicates the cabin light intensity level state.Indicates the cabin light intensity level state.";
CM_ SG_ 2582781438 LFtwlLightEnableState "Indicates the cabin light enable state.Indicates the cabin light enable state.";
CM_ SG_ 2582781438 PassLightModeAuto "Indicates whether the cabin light is in auto modeIndicates whether the cabin light is in auto mode";
CM_ SG_ 2582781438 DriverLightModeAuto "Indicates whether the cabin light is in auto modeIndicates whether the cabin light is in auto mode";
CM_ SG_ 2582781438 PassLightIntensityState "Indicates the cabin light intensity level state.Indicates the cabin light intensity level state.";
CM_ SG_ 2582781438 PassLightEnableState "Indicates the cabin light enable state.Indicates the cabin light enable state.";
CM_ SG_ 2582781438 DriverLightIntensityState "Indicates the cabin light intensity level state.Indicates the cabin light intensity level state.";
CM_ SG_ 2582781438 DriverLightEnableState "Indicates the cabin light enable state.Indicates the cabin light enable state.";
CM_ SG_ 2582781438 IndLighstIntensityState "Actuated state of indirect lights intensity.";
CM_ SG_ 2582781438 IndtLightsColorState "Actuated state of indirect lights colour temperature.";
CM_ SG_ 2582781438 SaloonLightsEnableState "Current ON/OFF state of sallon lights to be displayed";
CM_ SG_ 2582781438 VestLightIntensityState "Current state of vestibule light intensity to be displayed";
CM_ SG_ 2582781438 VestLightColorState "Current state of vestibule light colour temperature to be displayed";
CM_ SG_ 2582781438 VestLightEnableState "Current ON/OFF state of vestibule light to be displayed";
CM_ SG_ 2582781438 HaloLighstIntensityState "Actuated state of halo lights intensity.";
CM_ SG_ 2582781438 HaloLightsColorState "Current state of halo lights colour temperature to be displayed";
CM_ SG_ 2582781438 CabLightModeAuto "Indicates whether the cabin light is in auto modeIndicates whether the cabin light is in auto mode";
CM_ SG_ 2582781438 CabLightColorState "Indicates the cabin light color state.";
CM_ SG_ 2582781438 CabLightIntensityState "Indicates the cabin light intensity level state.Indicates the cabin light intensity level state.";
CM_ SG_ 2582781438 CabLightEnableState "Indicates the cabin light enable state.Indicates the cabin light enable state.";
CM_ BO_ 197 " #dbc\Third_party_components\META_DCDC\META_DCDC_MSCXX1003\0.0.5.0\META_DCDC_MSCXX1003.dbc";
CM_ SG_ 197 DCDC_InputCurrent "Invalid Value 0xFF";
CM_ BO_ 2381862910 " #dbc\Software_Modules\Safety_System\HORN\0.1.2.0\HORN.dbc";
CM_ SG_ 2381862910 AlarmHornReq "State of Alarm Horn";
CM_ BO_ 2566619134 "Message with the 1st LV DCDC status information #dbc\Software_Modules\LV_System\LVSYSOP\0.2.9.0\LVSYSOP.dbc";
CM_ BO_ 2583066110 " #dbc\Software_Modules\Closures_System\CENTLOCK\0.3.1.0\CENTLOCK.dbc";
CM_ SG_ 2583066110 CentralLockRequest "State of user request for doors central locking
";
CM_ BO_ 2398099454 " #dbc\Software_Modules\HV_System\HVPS\0.7.2.0\HVPS.dbc";
CM_ SG_ 2398099454 HVBPCActState "Actual state of HV battery pre-conditioning procedure";
CM_ BO_ 2381724158 " #dbc\StaticInternal\TMS\Climate\0.1.0.0\Climate_int.dbc";
CM_ BO_ 2448508414 " #dbc\StaticInternal\SCS\PYLDSYSDBG\0.1.0.0\PYLDSYSDBG.dbc";
CM_ BO_ 2381912343 "Value of odometer travelled distance, stored in HMI backup memory, in meters.
 #dbc\Components\HMI\Arrival_HMI\0.0.17.4\Arrival_HMI.dbc";
CM_ SG_ 2381912343 ODM_Data_Checksum "Checksum signal for E2E protection";
CM_ SG_ 2381912343 ODM_Data_Counter "counter signal for E2E protection";
CM_ BO_ 2381912087 "Data sent from HMI with information about time when particular Odometer DTC has been raised #dbc\Components\HMI\Arrival_HMI\0.0.17.4\Arrival_HMI.dbc";
CM_ SG_ 2381912087 ODM_FreezeFrame_Event "Which freeze frame is transmited
0 - First security event
1 - Last security event";
CM_ BO_ 2566866942 " #dbc\StaticInternal\DTS\ODO_DBG\0.1.0.0\ODO_DBG.dbc";
CM_ SG_ 2566866942 ODO_DBG_ODM_RESET "DBG_ODM_Reset";
CM_ SG_ 2566866942 ODO_DBG_InitCompleted "DBG_InitCompleted";
CM_ SG_ 2566866942 ODO_DBG_OverwriteFromHmi "DBG_OverwriteFromHmi";
CM_ SG_ 2566866942 ODO_DBG_OverwriteByZero "OverwriteByZero";
CM_ BO_ 2566867198 " #dbc\StaticInternal\DTS\ODO_DBG\0.1.0.0\ODO_DBG.dbc";
CM_ SG_ 2566867198 ODO_DBG_FLT9_TripDistNotInRange "TripDistanceNotInRange";
CM_ SG_ 2566867198 ODO_DBG_FLT8_TotDistNotInRange "TotalDistanceNotInRange";
CM_ SG_ 2566867198 ODO_DBG_FLT7_SpeedIsNotInRange "SpeedIsNotInRange";
CM_ SG_ 2566867198 ODO_DBG_FLT6_FlashDataIsInvalid "FlashDataIsInvalid";
CM_ SG_ 2566867198 ODO_DBG_FLT5_SpeedNotValid "SpeedNotValid";
CM_ SG_ 2566867198 ODO_DBG_FLT4_UnchangingOdometer "UnchangingOdometer";
CM_ SG_ 2566867198 ODO_DBG_FLT3_IncremAtZeroSpeed "IncrementsAtZeroSpeed";
CM_ BO_ 2566867200 " #dbc\StaticInternal\DTS\ODO_DBG\0.1.0.0\ODO_DBG.dbc";
CM_ SG_ 2566867200 ODO_DBG_SecStorSuccessfulWriting "FramSuccessfulWriting";
CM_ SG_ 2566867200 ODO_DBG_SecStor_LastUptime_s "SecStorage_LastUptime_s";
CM_ SG_ 2566867200 ODO_DBG_SecStorStartTotVehDistOk "start_SecStorage_TotVehDistOk";
CM_ SG_ 2566867200 ODO_DBG_SecStorActTotDistance_m "ACTUAL Tota lDistance From Security Storage";
CM_ SG_ 2566867200 ODO_DBG_SecStorStartTotDist_km "StartTotalDistance";
CM_ BO_ 2566865918 " #dbc\Software_Modules\ODO\ODO_status1\0.1.1.0\ODO_status1.dbc";
CM_ SG_ 2566865918 HghRsolutionTotalVehicleDistance "Distance traveled during all or part of a journey.";
CM_ BO_ 2566866174 " #dbc\Software_Modules\ODO\ODO_status2\0.1.1.0\ODO_status2.dbc";
CM_ SG_ 2566866174 TripDistance_m "Distance travelled within the trip";
CM_ BO_ 2566866430 " #dbc\Software_Modules\ODO\ODO_To_HMI\0.1.3.0\ODO_To_HMI.dbc";
CM_ SG_ 2566866430 OdoDTCFrameSelr "Odometer DTC Frame selector for request to HMI";
CM_ SG_ 2566866430 OdometerRoutineRequestToHMI "Request routines execution to HMI as a part of Odometer service routine.";
CM_ BO_ 2566842110 "Time/Date #dbc\j1939MISRA\0.0.8.2\j1939.dbc";
CM_ SG_ 2566842110 LocalHourOffset "The hour component of the offset between the UTC (Universal Time Coordinate) time and date and a local time zone time and date.  This is the number of hours to add to UTC, a.k.a. GMT, time and date to convert to the time and date in the local time ...";
CM_ SG_ 2566842110 LocalMinuteOffset "The minute component of the offset between the UTC time and date and a local time zone time and date.  This is the number of minutes to add to UTC (Universal Time Coordinate) time and date to convert to the time and date in the local time zone  ...";
CM_ SG_ 2566842110 Year "The year component of the current calendar date.  This should be reported as the year component of the current date at UTC (Universal Time Coordinate), a.k.a. GMT; however, it may be reported as the year component of the current date at a local time ...";
CM_ SG_ 2566842110 Day "The day component of the current calendar date.  This should be reported as the day component of the current date at UTC (Universal Time Coordinate), a.k.a. GMT; however, it may be reported as the day component of the current date at a local time ...";
CM_ SG_ 2566842110 Month "The month component of the current calendar date.  This should be reported as the month component of the current date at UTC (Universal Time Coordinate), a.k.a. GMT; however, it may be reported as the month component of the current date at a local ...";
CM_ SG_ 2566842110 Hours "The hour component of the current time of day.  This should be reported as the hour component of the current time at UTC (Universal Time Coordinate), a.k.a. GMT; however, it may be reported as the hour component of the current time at a local time ...";
CM_ SG_ 2566842110 Minutes "The minutes component of the current time of day.  This should be reported as the minutes component of the current time at UTC (Universal Time Coordinate), a.k.a. GMT; however, it may be reported as the minutes component of the current time at a ...";
CM_ SG_ 2566842110 Seconds "The seconds component of the current time of day.  This should be reported as the seconds component of the current time at UTC (Universal Time Coordinate), a.k.a. GMT; however, it may be reported as the seconds component of the current time at a ...";
CM_ BO_ 2448507134 " #dbc\StaticInternal\SCS\PYLDSYSDBG\0.1.0.0\PYLDSYSDBG.dbc";
CM_ SG_ 2448507134 HeightMeasuredRR "HeightMeasured = L*sin(RotationAngle), where L - sensor lever, default 50 mm accordance to Swoboda Ride Height Sensor specification
offset is not taken into account";
CM_ SG_ 2448507134 HeightMeasuredRL "HeightMeasured = L*sin(RotationAngle), where L - sensor lever, default 50 mm accordance to Swoboda Ride Height Sensor specification
offset is not taken into account";
CM_ SG_ 2448507134 HeightMeasuredFR "HeightMeasured = L*sin(RotationAngle), where L - sensor lever, default 50 mm accordance to Swoboda Ride Height Sensor specification
offset is not taken into account";
CM_ SG_ 2448507134 HeightMeasuredFL "HeightMeasured = L*sin(RotationAngle), where L - sensor lever, default 50 mm accordance to Swoboda Ride Height Sensor specification
offset is not taken into account";
CM_ BO_ 2448843262 " #dbc\StaticInternal\SCS\PYLDSYSDBG\0.1.0.0\PYLDSYSDBG.dbc";
CM_ BO_ 2448843518 " #dbc\StaticInternal\SCS\PYLDSYSDBG\0.1.0.0\PYLDSYSDBG.dbc";
CM_ BO_ 2448507390 " #dbc\StaticInternal\SCS\PYLDSYSDBG\0.1.0.0\PYLDSYSDBG.dbc";
CM_ SG_ 2448507390 RotationAngleRR "Raw Rotation Angle value which is obtained using the voltage-degree characteristic from Swoboda Ride Height Sensor specification";
CM_ SG_ 2448507390 RotationAngleRL "Raw Rotation Angle value which is obtained using the voltage-degree characteristic from Swoboda Ride Height Sensor specification";
CM_ SG_ 2448507390 RotationAngleFR "Raw Rotation Angle value which is obtained using the voltage-degree characteristic from Swoboda Ride Height Sensor specification";
CM_ SG_ 2448507390 RotationAngleFL "Raw Rotation Angle value which is obtained using the voltage-degree characteristic from Swoboda Ride Height Sensor specification";
CM_ BO_ 2448507646 " #dbc\StaticInternal\SCS\PYLDSYSDBG\0.1.0.0\PYLDSYSDBG.dbc";
CM_ BO_ 2365251326 " #dbc\EtalonMessages\CLS\0.0.1.0\CLS_pnp.dbc";
CM_ SG_ 2365251326 LtchSttAAAC0B5D "The signal `LtchSttAAAC0B5D` implements `bulkheadDoorLatchState` functional data flow produced by `CS.SBDLS` system function. Software implementation is outport `LatchState` of software component `E-Latch Bulkhead Door sensor`.";
CM_ BO_ 2365251070 " #dbc\EtalonMessages\CLS\0.0.1.0\CLS_pnp.dbc";
CM_ SG_ 2365251070 BlkhdDrLtchRq79F31101 "The signal `BlkhdDrLtchRq79F31101` implements `latchCommand` functional data flow produced by `ADP-98022.controlDoorLatchBulkhead` system function. Software implementation is outport `BulkheadDoorLatchReq` of software component `Doors Controller`.";
CM_ SG_ 2365251070 PssDrLtchRqC65112B3 "The signal `PssDrLtchRqC65112B3` implements `passDoorLatchCommand` functional data flow produced by `ADP-99892.controlPassDoorLatch` system function. Software implementation is outport `PassDoorLatchReq` of software component `Doors Controller`.";
CM_ SG_ 2365251070 DrvrDrLtchRq149F144F "The signal `DrvrDrLtchRq149F144F` implements `driverDoorLatchCommand` functional data flow produced by `ADP-78611.controlDriverDoorLatch` system function. Software implementation is outport `DriverDoorLatchReq` of software component `Doors Controller`.";
CM_ BO_ 2365250814 " #dbc\EtalonMessages\CLS\0.0.1.0\CLS_pnp.dbc";
CM_ SG_ 2365250814 DrOpnStt498019DA "The signal `DrOpnStt498019DA` implements `passengerDoorState` functional data flow produced by `ADP-95907.controlPassengerDoorStateUserIndication` system function. Software implementation is outport `DoorOpenState` of software component `Inteva E-Loc`.";
CM_ SG_ 2365250814 SnsdPwrDrStt36820F97 "The signal `SnsdPwrDrStt36820F97` implements `passPowerSlidingDoorStateDisplay` functional data flow produced by `CS.CPPSD` system function. Software implementation is outport `SensedPowerDoorState` of software component `Passenger power sliding door controller`.";
CM_ BO_ 2365250558 " #dbc\EtalonMessages\CLS\0.0.1.0\CLS_pnp.dbc";
CM_ SG_ 2365250558 RllrShttrLckAcDA7D0D03 "The signal `RllrShttrLckAcDA7D0D03` implements `rollerShutterLockActuateReq` functional data flow produced by `CS.CRS` system function. Software implementation is outport `RollerShutterLockActuateReq` of software component `Roller Shutter Controller`.";
CM_ BO_ 2483019518 " #dbc\EtalonMessages\TMS\0.1.0.0\TMS_etalon.dbc";
CM_ SG_ 2483019518 HtdGlElmSt72F5090B "The signal `HtdGlElmSt72F5090B` implements `Heater2Current` functional data flow produced by `HEATGCS.SH2C` system function. Software implementation is outport `GlassHeatElemState` of software component `Heated Glass Driver`.";
CM_ BO_ 2483019262 " #dbc\EtalonMessages\TMS\0.1.0.0\TMS_etalon.dbc";
CM_ SG_ 2483019262 HtdGlElmSt730E090D "The signal `HtdGlElmSt730E090D` implements `Heater3Current` functional data flow produced by `HEATGCS.SH3C` system function. Software implementation is outport `GlassHeatElemState` of software component `Heated Glass Driver`.";
CM_ BO_ 2483019006 " #dbc\EtalonMessages\TMS\0.1.0.0\TMS_etalon.dbc";
CM_ SG_ 2483019006 HtdGlRq3A5140AF0 "The signal `HtdGlRq3A5140AF0` implements `Heater3SupplyEnable` functional data flow produced by `HEATGCS.HE3C` system function. Software implementation is outport `HeatedGlassRequest_3` of software component `Heated Glass Aggregator`.";
CM_ SG_ 2483019006 HtdGlRq2A4F10AEE "The signal `HtdGlRq2A4F10AEE` implements `Heater2SupplyEnable` functional data flow produced by `HEATGCS.HE2C` system function. Software implementation is outport `HeatedGlassRequest_2` of software component `Heated Glass Aggregator`.";
CM_ BO_ 2566575614 " #dbc\EtalonMessages\CLS\0.0.1.0\CLS_pnp.dbc";
CM_ SG_ 2566575614 SrvcHtchLtchRq68B515C9 "The signal `SrvcHtchLtchRq68B515C9` implements `serviceHatchLatchCommand` functional data flow produced by `ADP-94495.controlServiceHatchLatch` system function. Software implementation is outport `ServiceHatchLatchReq` of software component `Doors Controller`.";
CM_ BO_ 2566575358 " #dbc\EtalonMessages\CLS\0.0.1.0\CLS_pnp.dbc";
CM_ SG_ 2566575358 SnsdSrvcHtchStB1020BA1 "The signal `SnsdSrvcHtchStB1020BA1` implements `sensedServiceHatchState` functional data flow produced by `CS.SSHS` system function. Software implementation is outport `SensedServiceHatchState` of software component `SrvcHtchLtch_Drv`.";
CM_ BO_ 2566575102 "Request from the Wiper Controller to the Wiper Driver. #dbc\EtalonMessages\WAWS\0.0.1.0\WAWS_pnp.dbc";
CM_ SG_ 2566575102 WshrCmd667308B4 "The signal `WshrCmd667308B4` implements `washerCommand` functional data flow produced by `WWSWP.CWSH` system function. Software implementation is outport `WasherCmd` of software component `Washer Controller`.";
CM_ BO_ 2566574846 " #dbc\EtalonMessages\ILS\0.0.1.0\ILS_pnp.dbc";
CM_ SG_ 2566574846 CrgLghtEnblRqsA1B80AE4 "The signal `CrgLghtEnblRqsA1B80AE4` implements `cargoLightEnableReq` functional data flow produced by `ILS.CCARGOL` system function. Software implementation is outport `CargoLightEnableRequest` of software component `Cargo Lights Manager`.";
CM_ SG_ 2566574846 CrgLghtActtRqsADA30B64 "The signal `CrgLghtActtRqsADA30B64` implements `cargoLightActuateReq` functional data flow produced by `ILS.CCARGOL` system function. Software implementation is outport `CargoLightActuateRequest` of software component `Cargo Lights Manager`.";
CM_ SG_ 2566574846 LFtwlLghtIntns6C841575 "The signal `LFtwlLghtIntns6C841575` implements `PlaceholderWhite11StatusSense1SensedState` functional data flow produced by `PLCHLDR.WHT11STTS.1` system function. Software implementation is outport `LFtwlLightIntensityAct` of software component `Interior Lights Driver Delta`.";
CM_ SG_ 2566574846 LFtwlLgthEnblS6CCD1577 "The signal `LFtwlLgthEnblS6CCD1577` implements `PlaceholderWhite12StatusSense1SensedState` functional data flow produced by `PLCHLDR.WHT12STTS.1` system function. Software implementation is outport `LFtwlLigthEnableStateAct` of software component `Interior Lights Driver Delta`.";
CM_ BO_ 2566574590 "Message with information from seatbelts and seatmats monitor #dbc\EtalonMessages\SFT\0.0.1.0\SFT_pnp.dbc";
CM_ SG_ 2566574590 StMtStt82CC09EE "The signal `StMtStt82CC09EE` implements `driverSeatMatState` functional data flow produced by `SFT.SDSM` system function. Software implementation is outport `SeatMatState` of software component `Seatmat Sens Driver`.";
CM_ SG_ 2566574590 LFtwlLghtEnblC30200EB1 "The signal `LFtwlLghtEnblC30200EB1` implements `PlaceholderWhite2Command1` functional data flow produced by `PLCHLDR.WHT2CMMND` system function. Software implementation is outport `LFtwlLightEnableCmd` of software component `Cabin Lights Manager`.";
CM_ SG_ 2566574590 LFtwlLghtIntns30490EB3 "The signal `LFtwlLghtIntns30490EB3` implements `PlaceholderWhite3Command1` functional data flow produced by `PLCHLDR.WHT3CMMND` system function. Software implementation is outport `LFtwlLightIntensityCmd` of software component `Cabin Lights Manager`.";
CM_ BO_ 2566574334 " #dbc\EtalonMessages\ILS\0.0.1.0\ILS_pnp.dbc";
CM_ SG_ 2566574334 CrgLghtLmp4Stt6D4D157B "The signal `CrgLghtLmp4Stt6D4D157B` implements `PlaceholderWhite13StatusSense2SensedState` functional data flow produced by `PLCHLDR.WHT13STTS.2` system function. Software implementation is outport `CargoLightLamp4State` of software component `Interior Lights Driver Delta`.";
CM_ SG_ 2566574334 CrgLghtLmp3Stt6D161579 "The signal `CrgLghtLmp3Stt6D161579` implements `PlaceholderWhite13StatusSense1SensedState` functional data flow produced by `PLCHLDR.WHT13STTS.1` system function. Software implementation is outport `CargoLightLamp3State` of software component `Interior Lights Driver Delta`.";
CM_ BO_ 2365250302 "ELS data tamplate. Send on Change at 1 secong interval #dbc\EtalonMessages\ELS\0.0.1.0\ELS_pnp.dbc";
CM_ SG_ 2365250302 IllmntnRqA6700B0C "The signal `IllmntnRqA6700B0C` implements `IlluminationReq` functional data flow produced by `ES-9910.fLSHLGHTM` system function. Software implementation is outport `Hazard Illumination Request` of software component `Flashing Lights Manager`.";
CM_ SG_ 2365250302 RIndcrCmd717E08AE "The signal `RIndcrCmd717E08AE` implements `RiIndcrCmd` functional data flow produced by `ES-9910.fLSHLGHTM` system function. Software implementation is outport `Right Indicator Command` of software component `Flashing Lights Manager`.";
CM_ SG_ 2365250302 LIndcrCmd711E08A4 "The signal `LIndcrCmd711E08A4` implements `LeIndcrCmd` functional data flow produced by `ES-9910.fLSHLGHTM` system function. Software implementation is outport `Left Indicator Command` of software component `Flashing Lights Manager`.";
CM_ SG_ 2365250302 RrLftPsCmd92290A19 "The signal `RrLftPsCmd92290A19` implements `RearLeftPosCmd` functional data flow produced by `ES-9849.eXTLGHTM` system function. Software implementation is outport `Rear Left Position Lamp Cmd` of software component `Exterior Lights Manager`.";
CM_ SG_ 2365250302 RrRghtPsCmd9D3B0A8C "The signal `RrRghtPsCmd9D3B0A8C` implements `RearRightPosCmd` functional data flow produced by `ES-9849.eXTLGHTM` system function. Software implementation is outport `Rear Right Position Lamp Cmd` of software component `Exterior Lights Manager`.";
CM_ SG_ 2365250302 FrntRghtPsCmdA9860B0B "The signal `FrntRghtPsCmdA9860B0B` implements `FrontRightPosCmd` functional data flow produced by `ES-9849.eXTLGHTM` system function. Software implementation is outport `Front Right Position Lamp Cmd` of software component `Exterior Lights Manager`.";
CM_ SG_ 2365250302 DRLCmdFL59140746 "The signal `DRLCmdFL59140746` implements `DRLCmdFL` functional data flow produced by `ES-9849.eXTLGHTM` system function. Software implementation is outport `DRLCmd_FL` of software component `Exterior Lights Manager`.";
CM_ SG_ 2365250302 RrFgLmpCmd91870A02 "The signal `RrFgLmpCmd91870A02` implements `RearFogLampCmd` functional data flow produced by `ES-9849.eXTLGHTM` system function. Software implementation is outport `Rear Fog Lamp Cmd` of software component `Exterior Lights Manager`.";
CM_ SG_ 2365250302 RrPsCmd6C28088E "The signal `RrPsCmd6C28088E` implements `RearPosCmd` functional data flow produced by `ES-9849.eXTLGHTM` system function. Software implementation is outport `Rear Position Lamp Cmd` of software component `Exterior Lights Manager`.";
CM_ SG_ 2365250302 RrRgPltCmd9C620A70 "The signal `RrRgPltCmd9C620A70` implements `RearRegPlateCmd` functional data flow produced by `ES-9849.eXTLGHTM` system function. Software implementation is outport `Rear Registration Plate Lamp Cmd` of software component `Exterior Lights Manager`.";
CM_ SG_ 2365250302 DppdBmCmd87A6099D "The signal `DppdBmCmd87A6099D` implements `DippedBeamCmd` functional data flow produced by `ES-9849.eXTLGHTM` system function. Software implementation is outport `Low Beam Cmd` of software component `Exterior Lights Manager`.";
CM_ SG_ 2365250302 MnBmCmd742708CC "The signal `MnBmCmd742708CC` implements `MainBeamCmd` functional data flow produced by `ES-9849.eXTLGHTM` system function. Software implementation is outport `High Beam Cmd` of software component `Exterior Lights Manager`.";
CM_ BO_ 2365249534 "ELS data tamplate. Send on Change at 1 secong interval #dbc\EtalonMessages\ELS\0.0.1.0\ELS_pnp.dbc";
CM_ SG_ 2365249534 LmpSttCFDA0C1D "The signal `LmpSttCFDA0C1D` implements `LampState` functional data flow produced by `ES-5887.lAMP_DRIVER_RiBrkLi` system function. Software implementation is outport `Lamp State` of software component `Universal Lamp Driver`.";
CM_ SG_ 2365249534 LmpSttE99F0CF0 "The signal `LmpSttE99F0CF0` implements `LampState` functional data flow produced by `ES-5887.lAMP_DRIVER_ReRiIndcr` system function. Software implementation is outport `Lamp State` of software component `Universal Lamp Driver`.";
CM_ SG_ 2365249534 LmpSttF7400D55 "The signal `LmpSttF7400D55` implements `LampState` functional data flow produced by `ES-5887.lAMP_DRIVER_ReRiPosnLi` system function. Software implementation is outport `Lamp State` of software component `Universal Lamp Driver`.";
CM_ BO_ 2365249790 "ELS data tamplate. Send on Change at 1 secong interval #dbc\EtalonMessages\ELS\0.0.1.0\ELS_pnp.dbc";
CM_ SG_ 2365249790 DppdBmStt18C70E0C "The signal `DppdBmStt18C70E0C` implements `DippedBeamState` functional data flow produced by `ES-9786.mOBIS_HDLGHT_DRV_Le` system function. Software implementation is outport `Low Beam State` of software component `Mobis Headlight Driver`.";
CM_ SG_ 2365249790 MnBmSttFC930D3B "The signal `MnBmSttFC930D3B` implements `MainBeamState` functional data flow produced by `ES-9786.mOBIS_HDLGHT_DRV_Le` system function. Software implementation is outport `High Beam State` of software component `Mobis Headlight Driver`.";
CM_ SG_ 2365249790 LmpStt04630DB4 "The signal `LmpStt04630DB4` implements `LampState` functional data flow produced by `ES-5887.lAMP_DRIVER_LeSideIndcr` system function. Software implementation is outport `Lamp State` of software component `Universal Lamp Driver`.";
CM_ SG_ 2365249790 LmpStt06180DC9 "The signal `LmpStt06180DC9` implements `LampState` functional data flow produced by `ES-5887.lAMP_DRIVER_FrntLeIndcr` system function. Software implementation is outport `Lamp State` of software component `Universal Lamp Driver`.";
CM_ SG_ 2365249790 LmpStt06BE0DD3 "The signal `LmpStt06BE0DD3` implements `LampState` functional data flow produced by `ES-5887.lAMP_DRIVER_FrntRiIndcr` system function. Software implementation is outport `Lamp State` of software component `Universal Lamp Driver`.";
CM_ SG_ 2365249790 LmpStt12DB0E1C "The signal `LmpStt12DB0E1C` implements `LampState` functional data flow produced by `ES-5887.lAMP_DRIVER_LeDayRunngLi` system function. Software implementation is outport `Lamp State` of software component `Universal Lamp Driver`.";
CM_ SG_ 2365249790 LmpStt15420E38 "The signal `LmpStt15420E38` implements `LampState` functional data flow produced by `ES-5887.lAMP_DRIVER_FrntRiPosnLi` system function. Software implementation is outport `Lamp State` of software component `Universal Lamp Driver`.";
CM_ BO_ 2365249278 "ELS data tamplate. Send on Change at 1 secong interval #dbc\EtalonMessages\ELS\0.0.1.0\ELS_pnp.dbc";
CM_ SG_ 2365249278 UdsRgnPltLmpCmEE080D3E "The signal `UdsRgnPltLmpCmEE080D3E` implements `UdsRegnPlateLampCmd` functional data flow produced by `ES-11944.udsElsDrv` system function. Software implementation is outport `Registration Plate Lamps Cmd` of software component `UDS Exterior Lighting System Driver`.";
CM_ SG_ 2365249278 UdsBrkLmpCmdA3950ADB "The signal `UdsBrkLmpCmdA3950ADB` implements `UdsBrkLampCmd` functional data flow produced by `ES-11944.udsElsDrv` system function. Software implementation is outport `Brake Lamps Cmd` of software component `UDS Exterior Lighting System Driver`.";
CM_ SG_ 2365249278 RghtLmpCmmndA5C80AE9 "The signal `RghtLmpCmmndA5C80AE9` implements `RightLampCommand` functional data flow produced by `ES-9821.bRKLGHTM` system function. Software implementation is outport `Right Lamp Command` of software component `Braking Lights Manager`.";
CM_ SG_ 2365249278 UdsRrPsLmpCmdD3CD0C78 "The signal `UdsRrPsLmpCmdD3CD0C78` implements `UdsRearPosLampCmd` functional data flow produced by `ES-11944.udsElsDrv` system function. Software implementation is outport `Rear Position Lamps Cmd` of software component `UDS Exterior Lighting System Driver`.";
CM_ SG_ 2365249278 UdsDrlLmpCmdA3B10ADE "The signal `UdsDrlLmpCmdA3B10ADE` implements `UdsDrlLampCmd` functional data flow produced by `ES-11944.udsElsDrv` system function. Software implementation is outport `DRL Lamps Cmd` of software component `UDS Exterior Lighting System Driver`.";
CM_ SG_ 2365249278 UdsIndcrLmpCmdBAFC0BAC "The signal `UdsIndcrLmpCmdBAFC0BAC` implements `UdsIndcrLampCmd` functional data flow produced by `ES-11944.udsElsDrv` system function. Software implementation is outport `Indicator Lamps Cmd` of software component `UDS Exterior Lighting System Driver`.";
CM_ SG_ 2365249278 UdsFrntPsLmpCmD4800C88 "The signal `UdsFrntPsLmpCmD4800C88` implements `UdsFrntPosLampCmd` functional data flow produced by `ES-11944.udsElsDrv` system function. Software implementation is outport `Front Position Lamps Cmd` of software component `UDS Exterior Lighting System Driver`.";
CM_ SG_ 2365249278 LmpSttE8F90CE6 "The signal `LmpSttE8F90CE6` implements `LampState` functional data flow produced by `ES-5887.lAMP_DRIVER_ReLeIndcr` system function. Software implementation is outport `Lamp State` of software component `Universal Lamp Driver`.";
CM_ SG_ 2365249278 UdsLwBmLmpCmdD3170C63 "The signal `UdsLwBmLmpCmdD3170C63` implements `UdsLowBeamLampCmd` functional data flow produced by `ES-11944.udsElsDrv` system function. Software implementation is outport `Low Beam Lamps Cmd` of software component `UDS Exterior Lighting System Driver`.";
CM_ SG_ 2365249278 UdsHBmLmpCmdC52E0BE2 "The signal `UdsHBmLmpCmdC52E0BE2` implements `UdsHiBeamLampCmd` functional data flow produced by `ES-11944.udsElsDrv` system function. Software implementation is outport `High Beam Lamps Cmd` of software component `UDS Exterior Lighting System Driver`.";
CM_ SG_ 2365249278 LmpSttCF780C16 "The signal `LmpSttCF780C16` implements `LampState` functional data flow produced by `ES-5887.lAMP_DRIVER_ReFogLi` system function. Software implementation is outport `Lamp State` of software component `Universal Lamp Driver`.";
CM_ SG_ 2365249278 LmpSttF6900D4B "The signal `LmpSttF6900D4B` implements `LampState` functional data flow produced by `ES-5887.lAMP_DRIVER_ReLePosnLi` system function. Software implementation is outport `Lamp State` of software component `Universal Lamp Driver`.";
BA_DEF_ BO_  "Producer" STRING ;
BA_DEF_ BO_  "GenMsgDelayTime" INT 0 1000;
BA_DEF_ BO_  "SendOnChange" ENUM  "No","Yes";
BA_DEF_ BO_  "GenMsgSendType" ENUM  "cyclic","NotUsed","NotUsed","NotUsed","NotUsed","NotUsed","NotUsed","IfActive","noMsgSendType";
BA_DEF_ BO_  "GenMsgCycleTime" INT 0 3600000;
BA_DEF_ BO_  "VFrameFormat" ENUM  "StandardCAN","ExtendedCAN","reserved","J1939PG";
BA_DEF_ SG_  "SPN" INT 0 524287;
BA_DEF_ SG_  "SigType" ENUM  "Default","Range","RangeSigned","ASCII","Discrete","Control","ReferencePGN","DTC","StringDelimiter","StringLength","StringLengthControl","MessageCounter","MessageChecksum";
BA_DEF_ SG_  "GenSigStartValue" INT 0 2147483647;
BA_DEF_ SG_  "GenSigSendType" ENUM  "Cyclic","OnWrite","OnWriteWithRepetition","OnChange","OnChangeWithRepetition","IfActive","IfActiveWithRepetition","NoSigSendType";
BA_DEF_ BO_  "PpCcGenMsgType" STRING ;
BA_DEF_ BO_  "GenMsgRequestable" INT 0 1;
BA_DEF_ BO_  "GenMsgCycleTimeFast" INT 0 3600000;
BA_DEF_DEF_  "Producer" "";
BA_DEF_DEF_  "GenMsgDelayTime" 0;
BA_DEF_DEF_  "SendOnChange" "No";
BA_DEF_DEF_  "GenMsgSendType" "noMsgSendType";
BA_DEF_DEF_  "GenMsgCycleTime" 0;
BA_DEF_DEF_  "VFrameFormat" "J1939PG";
BA_DEF_DEF_  "SPN" 0;
BA_DEF_DEF_  "SigType" "Default";
BA_DEF_DEF_  "GenSigStartValue" 0;
BA_DEF_DEF_  "GenSigSendType" "NoSigSendType";
BA_DEF_DEF_  "PpCcGenMsgType" "PpCcUndefined";
BA_DEF_DEF_  "GenMsgRequestable" 1;
BA_DEF_DEF_  "GenMsgCycleTimeFast" 0;
BA_ "GenMsgRequestable" BO_ 2637364990 0;
BA_ "GenSigStartValue" SG_ 2637364990 ReqAppSystemPackVersion 1;
BA_ "SPN" SG_ 2637364990 ReqAppSystemPackVersion 519471;
BA_ "GenSigStartValue" SG_ 2637364990 ReqModuleAlive 1;
BA_ "SPN" SG_ 2637364990 ReqModuleAlive 519466;
BA_ "GenSigStartValue" SG_ 2637364990 ReqParamsInfo 1;
BA_ "SPN" SG_ 2637364990 ReqParamsInfo 519465;
BA_ "GenSigStartValue" SG_ 2637364990 ReqModuleName 1;
BA_ "SPN" SG_ 2637364990 ReqModuleName 519464;
BA_ "GenSigStartValue" SG_ 2637364990 ReqHardwareName 1;
BA_ "SPN" SG_ 2637364990 ReqHardwareName 519463;
BA_ "GenSigStartValue" SG_ 2637364990 ReqHardwareInfo 1;
BA_ "SPN" SG_ 2637364990 ReqHardwareInfo 519462;
BA_ "GenSigStartValue" SG_ 2637364990 ReqBLVersionEx 1;
BA_ "SPN" SG_ 2637364990 ReqBLVersionEx 519461;
BA_ "GenSigStartValue" SG_ 2637364990 ReqBLVersion 1;
BA_ "SPN" SG_ 2637364990 ReqBLVersion 519460;
BA_ "GenSigStartValue" SG_ 2637364990 ReqBLName 1;
BA_ "SPN" SG_ 2637364990 ReqBLName 519459;
BA_ "GenSigStartValue" SG_ 2637364990 ReqAppVersionEx 1;
BA_ "SPN" SG_ 2637364990 ReqAppVersionEx 519458;
BA_ "GenSigStartValue" SG_ 2637364990 ReqAppVersion 1;
BA_ "SPN" SG_ 2637364990 ReqAppVersion 519457;
BA_ "GenSigStartValue" SG_ 2637364990 ReqAppName 1;
BA_ "SPN" SG_ 2637364990 ReqAppName 519456;
BA_ "Producer" BO_ 2583174654 "WAWS";
BA_ "GenMsgSendType" BO_ 2583174654 0;
BA_ "SendOnChange" BO_ 2583174654 1;
BA_ "GenMsgCycleTime" BO_ 2583174654 1000;
BA_ "GenMsgDelayTime" BO_ 2583174654 100;
BA_ "GenMsgCycleTime" BO_ 2365552126 50;
BA_ "GenMsgSendType" BO_ 2365552126 0;
BA_ "SigType" SG_ 2365552126 AutoHoldMsgCks 12;
BA_ "SigType" SG_ 2365552126 AutoHoldMsgCnt 11;
BA_ "GenMsgCycleTime" BO_ 2381871102 500;
BA_ "GenMsgSendType" BO_ 2381871102 0;
BA_ "GenMsgCycleTime" BO_ 2382107134 50;
BA_ "GenMsgSendType" BO_ 2382107134 0;
BA_ "SigType" SG_ 2382107134 BRK_Status1_checksum 12;
BA_ "GenSigSendType" SG_ 2382107134 BRK_Status1_checksum 0;
BA_ "GenSigSendType" SG_ 2382107134 BRK_Status1_counter 0;
BA_ "SigType" SG_ 2382107134 BRK_Status1_counter 11;
BA_ "GenMsgSendType" BO_ 2381844570 0;
BA_ "SendOnChange" BO_ 2381844570 1;
BA_ "GenMsgCycleTime" BO_ 2381844570 100;
BA_ "SigType" SG_ 2381844570 HMI_KB_BRK_CRC 12;
BA_ "SigType" SG_ 2381844570 HMI_KB_BRK_CNT 11;
BA_ "GenSigStartValue" SG_ 2381844570 BrkAmberTelltaleReq 3;
BA_ "GenSigStartValue" SG_ 2381844570 BrkESPOffTelltaleReq 3;
BA_ "GenSigStartValue" SG_ 2381844570 BrkESPTelltaleReq 3;
BA_ "GenSigStartValue" SG_ 2381844570 BrkYellowTelltaleReq 3;
BA_ "GenSigStartValue" SG_ 2381844570 BrkRedTelltaleReq 3;
BA_ "GenSigStartValue" SG_ 2381844570 BrkABSTelltaleReq 3;
BA_ "GenMsgCycleTime" BO_ 2650747415 250;
BA_ "GenMsgCycleTime" BO_ 2566899735 100;
BA_ "GenMsgSendType" BO_ 2566899735 0;
BA_ "GenSigStartValue" SG_ 2566899735 ChargingACPortCommand 3;
BA_ "GenSigStartValue" SG_ 2566899735 ChargingACDCPortCommand 3;
BA_ "GenSigStartValue" SG_ 2566899735 SpeedLimitReq 100;
BA_ "GenSigStartValue" SG_ 2566899735 AccMode 1;
BA_ "GenSigStartValue" SG_ 2566899735 AutoHoldDisable 1;
BA_ "GenSigStartValue" SG_ 2566899735 DisplayUserInformation 3;
BA_ "SigType" SG_ 2566899735 HMIRequest1_counter 11;
BA_ "SigType" SG_ 2566899735 HMIRequest1_checksum 12;
BA_ "GenMsgSendType" BO_ 2566803454 0;
BA_ "GenMsgCycleTime" BO_ 2566803454 100;
BA_ "SigType" SG_ 2566803454 TrailerVDCActive 5;
BA_ "SPN" SG_ 2566803454 TrailerVDCActive 5624;
BA_ "SigType" SG_ 2566803454 YCBrakeCtrlActive 5;
BA_ "SPN" SG_ 2566803454 YCBrakeCtrlActive 1819;
BA_ "SigType" SG_ 2566803454 YCEngCtrlActive 5;
BA_ "SPN" SG_ 2566803454 YCEngCtrlActive 1817;
BA_ "SigType" SG_ 2566803454 ROPBrakeCtrlActive 5;
BA_ "SPN" SG_ 2566803454 ROPBrakeCtrlActive 1818;
BA_ "SigType" SG_ 2566803454 ROPEngCtrlActive 5;
BA_ "SPN" SG_ 2566803454 ROPEngCtrlActive 1816;
BA_ "SigType" SG_ 2566803454 VDCBrakeLightRq 5;
BA_ "SPN" SG_ 2566803454 VDCBrakeLightRq 1815;
BA_ "SigType" SG_ 2566803454 VDCFullyOperational 5;
BA_ "SPN" SG_ 2566803454 VDCFullyOperational 1814;
BA_ "SigType" SG_ 2566803454 VDCInformationSignal 5;
BA_ "SPN" SG_ 2566803454 VDCInformationSignal 1813;
BA_ "GenMsgCycleTime" BO_ 2399125758 100;
BA_ "GenMsgSendType" BO_ 2399125758 0;
BA_ "Producer" BO_ 2381722110 "ELS";
BA_ "GenMsgSendType" BO_ 2381722110 0;
BA_ "GenMsgCycleTime" BO_ 2381722110 1000;
BA_ "SendOnChange" BO_ 2381722110 1;
BA_ "GenMsgDelayTime" BO_ 2381722110 10;
BA_ "GenMsgCycleTime" BO_ 2449446910 100;
BA_ "GenMsgSendType" BO_ 2449446910 0;
BA_ "GenMsgRequestable" BO_ 2650738942 0;
BA_ "SPN" SG_ 2650738942 AppVerBuild 519378;
BA_ "SPN" SG_ 2650738942 AppVerFix 519377;
BA_ "SPN" SG_ 2650738942 AppVerMinor 519376;
BA_ "SPN" SG_ 2650738942 AppVerMajor 519375;
BA_ "SPN" SG_ 2650738942 AppVerGeneration 519374;
BA_ "GenMsgSendType" BO_ 2466225918 0;
BA_ "GenMsgCycleTime" BO_ 2466225918 100;
BA_ "SendOnChange" BO_ 2600457470 1;
BA_ "GenMsgSendType" BO_ 2600457470 0;
BA_ "GenMsgCycleTime" BO_ 2600457470 1000;
BA_ "GenMsgDelayTime" BO_ 2600457470 100;
BA_ "SendOnChange" BO_ 2600457726 1;
BA_ "GenMsgSendType" BO_ 2600457726 0;
BA_ "GenMsgCycleTime" BO_ 2600457726 1000;
BA_ "GenMsgDelayTime" BO_ 2600457726 100;
BA_ "GenMsgCycleTime" BO_ 2600457982 100;
BA_ "GenMsgSendType" BO_ 2600457982 0;
BA_ "GenSigStartValue" SG_ 2600457982 NM_DBG_VSMState 7;
BA_ "GenMsgSendType" BO_ 2381395454 0;
BA_ "GenMsgCycleTime" BO_ 2381395454 500;
BA_ "SendOnChange" BO_ 2650742782 1;
BA_ "GenMsgSendType" BO_ 2650742782 0;
BA_ "GenMsgCycleTime" BO_ 2650742782 1000;
BA_ "GenMsgRequestable" BO_ 2650742782 0;
BA_ "SendOnChange" BO_ 2600459518 1;
BA_ "GenMsgSendType" BO_ 2600459518 0;
BA_ "GenMsgCycleTime" BO_ 2600459518 100;
BA_ "GenMsgSendType" BO_ 2515951358 0;
BA_ "GenMsgCycleTime" BO_ 2515951358 100;
BA_ "GenSigStartValue" SG_ 2515951358 ActTM_UpperTorqLim 32267;
BA_ "GenSigStartValue" SG_ 2515951358 ActTM_LowerTorqLim 32267;
BA_ "GenSigStartValue" SG_ 2515951358 ActTM_DemTorque 32267;
BA_ "GenSigStartValue" SG_ 2515951358 ActTM_ActTorque 32267;
BA_ "GenMsgCycleTime" BO_ 2515951102 100;
BA_ "GenMsgSendType" BO_ 2515951102 0;
BA_ "GenSigStartValue" SG_ 2515951102 ActTM_FiltTorqRiseRate 32267;
BA_ "GenSigStartValue" SG_ 2515951102 ActTM_MotSpeedRPM 32267;
BA_ "GenMsgSendType" BO_ 2515950846 0;
BA_ "GenMsgCycleTime" BO_ 2515950846 100;
BA_ "GenSigStartValue" SG_ 2515950846 BrkTM_EBSTorqDem 32267;
BA_ "GenMsgCycleTime" BO_ 2180407550 500;
BA_ "GenMsgSendType" BO_ 2180407550 0;
BA_ "SigType" SG_ 2180407550 DCUHMIMsgCks 12;
BA_ "SigType" SG_ 2180407550 DCUHMIMsgCtr 11;
BA_ "SigType" SG_ 2180407550 GearBox_FltSts 4;
BA_ "SigType" SG_ 2180407550 DTS_DriverWarn 4;
BA_ "GenMsgSendType" BO_ 2515950590 0;
BA_ "GenMsgCycleTime" BO_ 2515950590 100;
BA_ "GenSigStartValue" SG_ 2515950590 DemTM_UpperTorqLim 32267;
BA_ "GenSigStartValue" SG_ 2515950590 DemTM_LowerTorqLim 32267;
BA_ "GenSigStartValue" SG_ 2515950590 DemTM_TotalDemTorq 32267;
BA_ "GenMsgCycleTime" BO_ 2515950334 100;
BA_ "GenMsgSendType" BO_ 2515950334 0;
BA_ "GenSigStartValue" SG_ 2515950334 DemTM_UpperTorqLim_tab 32267;
BA_ "GenSigStartValue" SG_ 2515950334 DemTM_LowerTorqLim_tab 32267;
BA_ "GenMsgCycleTime" BO_ 2515950078 100;
BA_ "GenMsgSendType" BO_ 2515950078 0;
BA_ "GenSigStartValue" SG_ 2515950078 DemTM_MaxTorqRiseRate 32267;
BA_ "GenSigStartValue" SG_ 2515950078 DemTM_FiltTorqRiseRate 32267;
BA_ "GenMsgSendType" BO_ 2381867518 0;
BA_ "GenMsgCycleTime" BO_ 2381867518 100;
BA_ "SendOnChange" BO_ 2381867518 1;
BA_ "GenSigSendType" SG_ 2381867518 DT_States_checksum 0;
BA_ "SigType" SG_ 2381867518 DT_States_checksum 12;
BA_ "SigType" SG_ 2381867518 DT_States_counter 11;
BA_ "GenSigSendType" SG_ 2381867518 DT_States_counter 0;
BA_ "GenSigStartValue" SG_ 2381867518 DTReadyToDrive 3;
BA_ "SendOnChange" BO_ 2180416766 1;
BA_ "GenMsgDelayTime" BO_ 2180416766 100;
BA_ "GenMsgCycleTime" BO_ 2180416766 1000;
BA_ "GenMsgSendType" BO_ 2180416766 0;
BA_ "GenSigStartValue" SG_ 2180416766 DemTorq_OUT 32768;
BA_ "GenSigStartValue" SG_ 2180416766 DemTorq_IN 32768;
BA_ "GenMsgCycleTime" BO_ 2381971966 50;
BA_ "GenMsgSendType" BO_ 2381971966 0;
BA_ "SigType" SG_ 2381971966 DTS_Status1_checksum 12;
BA_ "GenSigSendType" SG_ 2381971966 DTS_Status1_checksum 0;
BA_ "GenSigSendType" SG_ 2381971966 DTS_Status1_counter 0;
BA_ "SigType" SG_ 2381971966 DTS_Status1_counter 11;
BA_ "SigType" SG_ 2381971966 DTS_VehicleSpeed 1;
BA_ "GenSigStartValue" SG_ 2381971966 DTS_VehicleSpeed 30000;
BA_ "SigType" SG_ 2381971966 DTS_AccrPedlPosn 1;
BA_ "SigType" SG_ 2381971966 DTS_BrkPedlPosn 1;
BA_ "GenMsgCycleTime" BO_ 2381972734 100;
BA_ "GenMsgSendType" BO_ 2381972734 0;
BA_ "GenSigSendType" SG_ 2381972734 DTS_Status4_checksum 0;
BA_ "SigType" SG_ 2381972734 DTS_Status4_checksum 12;
BA_ "GenSigSendType" SG_ 2381972734 DTS_Status4_counter 0;
BA_ "SigType" SG_ 2381972734 DTS_Status4_counter 11;
BA_ "SigType" SG_ 2381972734 DTS_MotorTorque 1;
BA_ "GenSigStartValue" SG_ 2381972734 DTS_MotorTorque 32768;
BA_ "SigType" SG_ 2381972734 DTS_MotorSpeed 1;
BA_ "GenSigStartValue" SG_ 2381972734 DTS_MotorSpeed 32768;
BA_ "GenMsgSendType" BO_ 2381972478 0;
BA_ "GenMsgCycleTime" BO_ 2381972478 100;
BA_ "SigType" SG_ 2381972478 DTS_Status3_checksum 12;
BA_ "GenSigSendType" SG_ 2381972478 DTS_Status3_checksum 0;
BA_ "SigType" SG_ 2381972478 DTS_Status3_counter 11;
BA_ "GenSigSendType" SG_ 2381972478 DTS_Status3_counter 0;
BA_ "GenSigStartValue" SG_ 2381972478 DTS_IDU_InvTemp1 40;
BA_ "SigType" SG_ 2381972478 DTS_IDU_InvTemp1 1;
BA_ "GenSigStartValue" SG_ 2381972478 DTS_IDU_MotTemp1 40;
BA_ "SigType" SG_ 2381972478 DTS_IDU_MotTemp1 1;
BA_ "SigType" SG_ 2381972478 DTS_IDU_DCCurrent 1;
BA_ "GenSigStartValue" SG_ 2381972478 DTS_IDU_DCCurrent 32768;
BA_ "SigType" SG_ 2381972478 DTS_IDU_DCVoltage 1;
BA_ "GenMsgCycleTime" BO_ 2381972222 100;
BA_ "GenMsgSendType" BO_ 2381972222 0;
BA_ "SigType" SG_ 2381972222 DTS_Status2_checksum 12;
BA_ "GenSigSendType" SG_ 2381972222 DTS_Status2_checksum 0;
BA_ "SigType" SG_ 2381972222 DTS_Status2_counter 11;
BA_ "GenSigSendType" SG_ 2381972222 DTS_Status2_counter 0;
BA_ "GenMsgCycleTime" BO_ 2180407294 1000;
BA_ "GenMsgDelayTime" BO_ 2180407294 100;
BA_ "GenMsgSendType" BO_ 2180407294 0;
BA_ "SendOnChange" BO_ 2180407294 1;
BA_ "GenMsgDelayTime" BO_ 2399110910 10;
BA_ "SendOnChange" BO_ 2399110910 1;
BA_ "GenMsgCycleTime" BO_ 2399110910 1000;
BA_ "GenSigStartValue" SG_ 2399110910 EBS_TorqueRequest 32768;
BA_ "GenMsgCycleTime" BO_ 2399111166 100;
BA_ "GenMsgCycleTime" BO_ 2399109630 100;
BA_ "GenSigStartValue" SG_ 2399109630 DrRA_Acc_Req 100;
BA_ "GenMsgCycleTime" BO_ 2600438270 1000;
BA_ "SendOnChange" BO_ 2600438270 1;
BA_ "GenMsgDelayTime" BO_ 2600438270 100;
BA_ "GenMsgCycleTime" BO_ 2600439038 100;
BA_ "GenMsgCycleTime" BO_ 2381399806 1000;
BA_ "GenMsgDelayTime" BO_ 2381399806 100;
BA_ "SendOnChange" BO_ 2381399806 1;
BA_ "GenMsgCycleTime" BO_ 2382314750 200;
BA_ "GenMsgSendType" BO_ 2382314750 0;
BA_ "SendOnChange" BO_ 2382315006 1;
BA_ "GenMsgCycleTime" BO_ 2382315006 100;
BA_ "GenMsgSendType" BO_ 2382315006 0;
BA_ "GenMsgDelayTime" BO_ 2399117822 50;
BA_ "SendOnChange" BO_ 2399117822 1;
BA_ "GenMsgCycleTime" BO_ 2399117822 1000;
BA_ "GenMsgSendType" BO_ 2399117822 0;
BA_ "GenMsgSendType" BO_ 2381739774 0;
BA_ "GenMsgCycleTime" BO_ 2381739774 100;
BA_ "SigType" SG_ 2381739774 GS_CRC 12;
BA_ "SigType" SG_ 2381739774 GS_MC 11;
BA_ "GenMsgSendType" BO_ 2381740030 0;
BA_ "GenMsgCycleTime" BO_ 2381740030 100;
BA_ "GenMsgSendType" BO_ 2566900247 0;
BA_ "GenMsgCycleTime" BO_ 2566900247 100;
BA_ "GenMsgCycleTime" BO_ 2566906110 100;
BA_ "GenMsgSendType" BO_ 2566906110 0;
BA_ "SigType" SG_ 2566906110 AnalogInput_11 1;
BA_ "SigType" SG_ 2566906110 AnalogInput_02 1;
BA_ "SigType" SG_ 2566906110 AnalogInput_03 1;
BA_ "GenSigStartValue" SG_ 2566906110 AccelMeasure 125;
BA_ "GenMsgDelayTime" BO_ 2381855998 100;
BA_ "GenMsgCycleTime" BO_ 2381855998 1000;
BA_ "SendOnChange" BO_ 2381855998 1;
BA_ "Producer" BO_ 2381855998 "UICS";
BA_ "GenMsgCycleTimeFast" BO_ 882 100;
BA_ "GenMsgCycleTime" BO_ 882 100;
BA_ "GenMsgSendType" BO_ 882 0;
BA_ "Producer" BO_ 882 "LVPS";
BA_ "GenSigStartValue" SG_ 882 VCU_DCDCActivation 1;
BA_ "Producer" BO_ 2399123198 "LVPS";
BA_ "GenMsgSendType" BO_ 2399123198 0;
BA_ "GenMsgCycleTime" BO_ 2399123198 100;
BA_ "GenSigStartValue" SG_ 2399123198 DCDC_HVIL_Status 3;
BA_ "GenSigStartValue" SG_ 2399123198 DCDC_Temperature 40;
BA_ "Producer" BO_ 2314626046 "SCS";
BA_ "GenMsgCycleTime" BO_ 2314626046 100;
BA_ "GenMsgSendType" BO_ 2314626046 0;
BA_ "GenSigStartValue" SG_ 2314626046 VehPitchAngle 32000;
BA_ "GenMsgSendType" BO_ 2582780183 0;
BA_ "GenMsgCycleTime" BO_ 2582780183 1000;
BA_ "GenMsgDelayTime" BO_ 2582780183 100;
BA_ "SendOnChange" BO_ 2582780183 1;
BA_ "GenSigStartValue" SG_ 2582780183 CargoLightModeHmiReq 7;
BA_ "GenMsgSendType" BO_ 2582781182 0;
BA_ "GenMsgCycleTime" BO_ 2582781182 1000;
BA_ "GenMsgDelayTime" BO_ 2582781182 100;
BA_ "SendOnChange" BO_ 2582781182 1;
BA_ "Producer" BO_ 2582781182 "ILS";
BA_ "GenSigStartValue" SG_ 2582781182 CargoLightModeAuto 3;
BA_ "GenMsgSendType" BO_ 2582780670 0;
BA_ "GenMsgCycleTime" BO_ 2582780670 1000;
BA_ "GenMsgDelayTime" BO_ 2582780670 100;
BA_ "SendOnChange" BO_ 2582780670 1;
BA_ "Producer" BO_ 2582780670 "ILS";
BA_ "GenSigStartValue" SG_ 2582780670 CargoLightStateAct 3;
BA_ "GenMsgCycleTimeFast" BO_ 2365556990 10;
BA_ "GenMsgCycleTime" BO_ 2365556990 50;
BA_ "SendOnChange" BO_ 2365556990 1;
BA_ "SPN" SG_ 2365556990 BsmSt 12286;
BA_ "GenSigSendType" SG_ 2365556990 BsmSt 3;
BA_ "GenSigStartValue" SG_ 2365556990 BsmSt 15;
BA_ "GenMsgDelayTime" BO_ 2365557246 10;
BA_ "GenMsgCycleTime" BO_ 2365557246 1000;
BA_ "GenMsgSendType" BO_ 2365557246 0;
BA_ "GenMsgCycleTimeFast" BO_ 2365557246 10;
BA_ "SendOnChange" BO_ 2365557246 1;
BA_ "Producer" BO_ 2365557246 "ELS";
BA_ "GenSigStartValue" SG_ 2365557246 BsmWarnLampStRi 3;
BA_ "GenSigStartValue" SG_ 2365557246 BsmWarnLampStLe 3;
BA_ "GenMsgDelayTime" BO_ 2381860350 100;
BA_ "GenMsgSendType" BO_ 2381860350 0;
BA_ "GenMsgCycleTime" BO_ 2381860350 1000;
BA_ "SendOnChange" BO_ 2381860350 1;
BA_ "Producer" BO_ 2381860350 "ELS";
BA_ "SigType" SG_ 2381860350 ELS2HMI_CRC 12;
BA_ "SigType" SG_ 2381860350 ELS2HMI_Cnt 11;
BA_ "Producer" BO_ 2583173630 "WAWS";
BA_ "GenMsgCycleTime" BO_ 2583173630 1000;
BA_ "GenMsgSendType" BO_ 2583173630 0;
BA_ "SendOnChange" BO_ 2583173630 1;
BA_ "GenMsgDelayTime" BO_ 2583173630 100;
BA_ "Producer" BO_ 2381723646 "ELS";
BA_ "GenMsgCycleTime" BO_ 2381723646 1000;
BA_ "GenMsgSendType" BO_ 2381723646 0;
BA_ "GenSigStartValue" SG_ 2381723646 TGlass 40;
BA_ "SigType" SG_ 2381723646 TGlass 1;
BA_ "SigType" SG_ 2381723646 SolarIrradiationRight 1;
BA_ "GenSigStartValue" SG_ 2381723646 TDew 40;
BA_ "SigType" SG_ 2381723646 SolarIrradiationLeft 1;
BA_ "SigType" SG_ 2381723646 CabinHumidity 1;
BA_ "PpCcGenMsgType" BO_ 2373975806 "PpCcInput";
BA_ "GenMsgSendType" BO_ 2373975806 0;
BA_ "SendOnChange" BO_ 2373975806 1;
BA_ "GenMsgCycleTime" BO_ 2373975806 1000;
BA_ "Producer" BO_ 2373975806 "UICS";
BA_ "GenMsgDelayTime" BO_ 2381855742 100;
BA_ "GenMsgCycleTime" BO_ 2381855742 1000;
BA_ "SendOnChange" BO_ 2381855742 1;
BA_ "Producer" BO_ 2381855742 "UICS";
BA_ "Producer" BO_ 2448966142 "LVPS";
BA_ "GenMsgCycleTime" BO_ 2448966142 1000;
BA_ "GenMsgSendType" BO_ 2448966142 0;
BA_ "SigType" SG_ 2448966142 BattSoH 1;
BA_ "SigType" SG_ 2448966142 BattTemperature 1;
BA_ "GenSigStartValue" SG_ 2448966142 BattTemperature 40;
BA_ "GenSigStartValue" SG_ 2448966142 LVVehicleCurrent 1024;
BA_ "SigType" SG_ 2448966142 BattCurrent 1;
BA_ "GenSigStartValue" SG_ 2448966142 BattCurrent 1020;
BA_ "SigType" SG_ 2448966142 BattVoltage 1;
BA_ "SigType" SG_ 2448966142 BattSoc 1;
BA_ "SendOnChange" BO_ 2381859582 1;
BA_ "GenMsgCycleTime" BO_ 2381859582 1000;
BA_ "GenMsgSendType" BO_ 2381859582 0;
BA_ "GenMsgDelayTime" BO_ 2381859582 100;
BA_ "GenMsgCycleTime" BO_ 2180924158 100;
BA_ "GenMsgSendType" BO_ 2180924158 0;
BA_ "GenSigStartValue" SG_ 2180924158 HV_TotalActualCurrent 32700;
BA_ "SigType" SG_ 2180924158 SysState_Counter 11;
BA_ "SigType" SG_ 2180924158 SysState_CRC 12;
BA_ "SendOnChange" BO_ 2381859838 1;
BA_ "GenMsgCycleTime" BO_ 2381859838 1000;
BA_ "GenMsgSendType" BO_ 2381859838 0;
BA_ "GenMsgDelayTime" BO_ 2381859838 100;
BA_ "Producer" BO_ 2381859838 "ELS";
BA_ "SendOnChange" BO_ 2381860606 1;
BA_ "GenMsgCycleTime" BO_ 2381860606 1000;
BA_ "GenMsgSendType" BO_ 2381860606 0;
BA_ "GenMsgDelayTime" BO_ 2381860606 100;
BA_ "Producer" BO_ 2381860606 "ELS";
BA_ "GenMsgSendType" BO_ 2583184638 0;
BA_ "GenMsgCycleTime" BO_ 2583184638 1000;
BA_ "GenSigStartValue" SG_ 2583184638 ManualLevelling_Value 50;
BA_ "GenMsgSendType" BO_ 2583108606 0;
BA_ "SendOnChange" BO_ 2583108606 1;
BA_ "GenMsgCycleTime" BO_ 2583108606 10;
BA_ "GenMsgSendType" BO_ 2582767102 0;
BA_ "SendOnChange" BO_ 2582767102 1;
BA_ "GenMsgCycleTime" BO_ 2582767102 1000;
BA_ "GenSigStartValue" SG_ 2582767102 Alarm_Silence_request 3;
BA_ "GenSigStartValue" SG_ 2582767102 Tilt_Arm_Disarm 5;
BA_ "GenSigStartValue" SG_ 2582767102 USS_Arm_Disarm 3;
BA_ "GenSigStartValue" SG_ 2582767102 MW_Arm_Disarm 5;
BA_ "GenSigStartValue" SG_ 2582767102 ACU_arm_disarm 3;
BA_ "Producer" BO_ 2583175166 "WAWS";
BA_ "GenMsgDelayTime" BO_ 2583175166 100;
BA_ "GenMsgSendType" BO_ 2583175166 0;
BA_ "SendOnChange" BO_ 2583175166 1;
BA_ "GenMsgCycleTime" BO_ 2583175166 1000;
BA_ "GenMsgDelayTime" BO_ 2365553406 100;
BA_ "SendOnChange" BO_ 2365553406 1;
BA_ "GenMsgCycleTime" BO_ 2365553406 1000;
BA_ "GenMsgSendType" BO_ 2365553406 0;
BA_ "GenSigStartValue" SG_ 2365553406 DPadCruiseControlReq 3;
BA_ "GenSigStartValue" SG_ 2365553406 DpadVoiceAssistReq 3;
BA_ "GenSigStartValue" SG_ 2365553406 ExtMirrorAdjReqHMI 3;
BA_ "GenMsgCycleTime" BO_ 2566627838 100;
BA_ "GenMsgSendType" BO_ 2566627838 0;
BA_ "GenMsgSendType" BO_ 2583047422 0;
BA_ "GenMsgCycleTime" BO_ 2583047422 50;
BA_ "GenMsgSendType" BO_ 2583047678 0;
BA_ "GenMsgCycleTime" BO_ 2583047678 50;
BA_ "Producer" BO_ 2399122430 "LVPS";
BA_ "GenMsgCycleTime" BO_ 2399122430 100;
BA_ "GenMsgSendType" BO_ 2399122430 0;
BA_ "SigType" SG_ 2399122430 LV_Info_cs 12;
BA_ "SigType" SG_ 2399122430 LV_Info_rc 11;
BA_ "SigType" SG_ 2399122430 HVTotActCurrent 1;
BA_ "GenMsgCycleTimeFast" BO_ 837 100;
BA_ "GenMsgCycleTime" BO_ 837 100;
BA_ "GenMsgSendType" BO_ 837 0;
BA_ "GenSigStartValue" SG_ 837 DCDC_Temperature 40;
BA_ "GenMsgSendType" BO_ 2566847742 0;
BA_ "GenMsgCycleTime" BO_ 2566847742 1000;
BA_ "SigType" SG_ 2566847742 EngOilFilterDiffPress7471 1;
BA_ "SPN" SG_ 2566847742 EngOilFilterDiffPress7471 7471;
BA_ "SigType" SG_ 2566847742 FuelLevel2 1;
BA_ "SPN" SG_ 2566847742 FuelLevel2 38;
BA_ "SigType" SG_ 2566847742 CargoAmbientTemp 1;
BA_ "SPN" SG_ 2566847742 CargoAmbientTemp 169;
BA_ "SigType" SG_ 2566847742 EngOilFilterDiffPress 1;
BA_ "SPN" SG_ 2566847742 EngOilFilterDiffPress 99;
BA_ "SigType" SG_ 2566847742 EngFuelFilterDiffPress 1;
BA_ "SPN" SG_ 2566847742 EngFuelFilterDiffPress 95;
BA_ "SigType" SG_ 2566847742 FuelLevel1 1;
BA_ "SPN" SG_ 2566847742 FuelLevel1 96;
BA_ "SigType" SG_ 2566847742 WasherFluidLevel 1;
BA_ "SPN" SG_ 2566847742 WasherFluidLevel 80;
BA_ "GenMsgCycleTime" BO_ 2583064318 100;
BA_ "GenMsgSendType" BO_ 2582780695 0;
BA_ "GenMsgCycleTime" BO_ 2582780695 1000;
BA_ "GenMsgDelayTime" BO_ 2582780695 100;
BA_ "SendOnChange" BO_ 2582780695 1;
BA_ "GenSigStartValue" SG_ 2582780695 RFtwlLightIntensityReq 7;
BA_ "GenSigStartValue" SG_ 2582780695 RFtwlLightEnableReq 7;
BA_ "GenSigStartValue" SG_ 2582780695 LFtwlLightIntensityReq 7;
BA_ "GenSigStartValue" SG_ 2582780695 LFtwlLightEnableReq 7;
BA_ "GenSigStartValue" SG_ 2582780695 PassLightIntensityReq 7;
BA_ "GenSigStartValue" SG_ 2582780695 DriverLightIntensityReq 7;
BA_ "GenSigStartValue" SG_ 2582780695 PassLightEnableReq 7;
BA_ "GenSigStartValue" SG_ 2582780695 DriverLightEnableReq 7;
BA_ "GenSigStartValue" SG_ 2582780695 VestLightEnaReq 7;
BA_ "GenSigStartValue" SG_ 2582780695 IndHaloLightEnaReq 7;
BA_ "GenSigStartValue" SG_ 2582780695 CabLightColorReq 3;
BA_ "GenSigStartValue" SG_ 2582780695 CabLightIntensityReq 7;
BA_ "GenSigStartValue" SG_ 2582780695 CabLightEnableReq 7;
BA_ "GenMsgSendType" BO_ 2582781438 0;
BA_ "GenMsgCycleTime" BO_ 2582781438 1000;
BA_ "GenMsgDelayTime" BO_ 2582781438 100;
BA_ "SendOnChange" BO_ 2582781438 1;
BA_ "Producer" BO_ 2582781438 "ILS";
BA_ "GenSigStartValue" SG_ 2582781438 RFtwlLightModeAuto 3;
BA_ "GenSigStartValue" SG_ 2582781438 RFtwlLightIntensityState 7;
BA_ "GenSigStartValue" SG_ 2582781438 RFtwlLightEnableState 3;
BA_ "GenSigStartValue" SG_ 2582781438 LFtwlLightModeAuto 3;
BA_ "GenSigStartValue" SG_ 2582781438 LFtwlLightIntensityState 7;
BA_ "GenSigStartValue" SG_ 2582781438 LFtwlLightEnableState 3;
BA_ "GenSigStartValue" SG_ 2582781438 PassLightModeAuto 3;
BA_ "GenSigStartValue" SG_ 2582781438 DriverLightModeAuto 3;
BA_ "GenSigStartValue" SG_ 2582781438 PassLightIntensityState 7;
BA_ "GenSigStartValue" SG_ 2582781438 PassLightEnableState 3;
BA_ "GenSigStartValue" SG_ 2582781438 DriverLightIntensityState 7;
BA_ "GenSigStartValue" SG_ 2582781438 DriverLightEnableState 3;
BA_ "GenSigStartValue" SG_ 2582781438 IndLighstIntensityState 7;
BA_ "GenSigStartValue" SG_ 2582781438 IndtLightsColorState 3;
BA_ "GenSigStartValue" SG_ 2582781438 SaloonLightsEnableState 3;
BA_ "GenSigStartValue" SG_ 2582781438 VestLightIntensityState 7;
BA_ "GenSigStartValue" SG_ 2582781438 VestLightColorState 3;
BA_ "GenSigStartValue" SG_ 2582781438 VestLightEnableState 3;
BA_ "GenSigStartValue" SG_ 2582781438 HaloLighstIntensityState 7;
BA_ "GenSigStartValue" SG_ 2582781438 HaloLightsColorState 3;
BA_ "GenSigStartValue" SG_ 2582781438 CabLightModeAuto 3;
BA_ "GenSigStartValue" SG_ 2582781438 CabLightColorState 3;
BA_ "GenSigStartValue" SG_ 2582781438 CabLightIntensityState 7;
BA_ "GenSigStartValue" SG_ 2582781438 CabLightEnableState 3;
BA_ "GenMsgSendType" BO_ 197 0;
BA_ "GenMsgCycleTime" BO_ 197 100;
BA_ "GenMsgCycleTimeFast" BO_ 197 100;
BA_ "SendOnChange" BO_ 2381862910 1;
BA_ "GenMsgCycleTime" BO_ 2381862910 1000;
BA_ "Producer" BO_ 2566619134 "LVPS";
BA_ "GenMsgCycleTime" BO_ 2566619134 10000;
BA_ "GenMsgSendType" BO_ 2566619134 0;
BA_ "GenSigStartValue" SG_ 2566619134 DCDC_HV_Current 32000;
BA_ "GenSigStartValue" SG_ 2566619134 DCDC_LV_Current 32000;
BA_ "SendOnChange" BO_ 2583066110 1;
BA_ "GenMsgSendType" BO_ 2583066110 0;
BA_ "GenMsgCycleTime" BO_ 2583066110 1000;
BA_ "GenSigStartValue" SG_ 2583066110 CentralLockRequest 7;
BA_ "GenMsgSendType" BO_ 2398099454 0;
BA_ "GenMsgCycleTime" BO_ 2398099454 100;
BA_ "SendOnChange" BO_ 2398099454 1;
BA_ "GenSigStartValue" SG_ 2398099454 HVReadyToDrive 3;
BA_ "GenMsgSendType" BO_ 2381724158 0;
BA_ "GenMsgCycleTime" BO_ 2381724158 1000;
BA_ "GenSigStartValue" SG_ 2381724158 CabinRecirculationRequest 7;
BA_ "GenMsgCycleTime" BO_ 2448508414 1000;
BA_ "GenMsgSendType" BO_ 2381912343 0;
BA_ "GenMsgCycleTime" BO_ 2381912343 100;
BA_ "SigType" SG_ 2381912343 ODM_Data_Checksum 12;
BA_ "SigType" SG_ 2381912343 ODM_Data_Counter 11;
BA_ "GenMsgSendType" BO_ 2381912087 0;
BA_ "GenMsgCycleTime" BO_ 2381912087 1000;
BA_ "GenSigStartValue" SG_ 2381912087 ODM_FreezeFrame_Year 23;
BA_ "GenSigStartValue" SG_ 2381912087 ODM_FreezeFrame_Month 1;
BA_ "GenSigStartValue" SG_ 2381912087 ODM_FreezeFrame_Day 1;
BA_ "GenMsgDelayTime" BO_ 2566866942 100;
BA_ "GenMsgCycleTime" BO_ 2566866942 1000;
BA_ "GenMsgSendType" BO_ 2566866942 0;
BA_ "SendOnChange" BO_ 2566866942 1;
BA_ "GenMsgSendType" BO_ 2566867198 0;
BA_ "GenMsgCycleTime" BO_ 2566867198 100;
BA_ "SendOnChange" BO_ 2566867198 1;
BA_ "GenMsgSendType" BO_ 2566867200 0;
BA_ "GenMsgCycleTime" BO_ 2566867200 100;
BA_ "GenMsgCycleTime" BO_ 2566865918 1000;
BA_ "GenMsgSendType" BO_ 2566865918 0;
BA_ "SigType" SG_ 2566865918 VD_CRC 12;
BA_ "SigType" SG_ 2566865918 VD_Cnt 11;
BA_ "SPN" SG_ 2566865918 HghRsolutionTotalVehicleDistance 918;
BA_ "SigType" SG_ 2566865918 HghRsolutionTotalVehicleDistance 1;
BA_ "GenMsgSendType" BO_ 2566866174 0;
BA_ "GenMsgCycleTime" BO_ 2566866174 100;
BA_ "GenMsgSendType" BO_ 2566866430 0;
BA_ "GenMsgCycleTime" BO_ 2566866430 100;
BA_ "SigType" SG_ 2566866430 OS_CRC 12;
BA_ "SigType" SG_ 2566866430 OS_Cnt 11;
BA_ "GenSigStartValue" SG_ 2566866430 OdometerRoutineRequestToHMI 7;
BA_ "SigType" SG_ 2566842110 LocalHourOffset 1;
BA_ "GenSigStartValue" SG_ 2566842110 LocalHourOffset 102;
BA_ "SPN" SG_ 2566842110 LocalHourOffset 1602;
BA_ "SigType" SG_ 2566842110 LocalMinuteOffset 1;
BA_ "GenSigStartValue" SG_ 2566842110 LocalMinuteOffset 66;
BA_ "SPN" SG_ 2566842110 LocalMinuteOffset 1601;
BA_ "SigType" SG_ 2566842110 Year 1;
BA_ "SPN" SG_ 2566842110 Year 964;
BA_ "SigType" SG_ 2566842110 Day 1;
BA_ "GenSigStartValue" SG_ 2566842110 Day 1;
BA_ "SPN" SG_ 2566842110 Day 962;
BA_ "SigType" SG_ 2566842110 Month 1;
BA_ "GenSigStartValue" SG_ 2566842110 Month 1;
BA_ "SPN" SG_ 2566842110 Month 963;
BA_ "SigType" SG_ 2566842110 Hours 1;
BA_ "SPN" SG_ 2566842110 Hours 961;
BA_ "SigType" SG_ 2566842110 Minutes 1;
BA_ "SPN" SG_ 2566842110 Minutes 960;
BA_ "SigType" SG_ 2566842110 Seconds 1;
BA_ "SPN" SG_ 2566842110 Seconds 959;
BA_ "GenMsgCycleTime" BO_ 2448507134 1000;
BA_ "GenMsgSendType" BO_ 2448507134 0;
BA_ "GenMsgCycleTime" BO_ 2448843262 1000;
BA_ "GenMsgSendType" BO_ 2448843262 0;
BA_ "GenMsgCycleTime" BO_ 2448843518 1000;
BA_ "GenMsgSendType" BO_ 2448843518 0;
BA_ "GenMsgCycleTime" BO_ 2448507390 1000;
BA_ "GenMsgSendType" BO_ 2448507390 0;
BA_ "GenMsgCycleTime" BO_ 2448507646 1000;
BA_ "GenMsgSendType" BO_ 2448507646 0;
BA_ "GenMsgSendType" BO_ 2365251326 0;
BA_ "GenMsgCycleTime" BO_ 2365251326 100;
BA_ "GenSigStartValue" SG_ 2365251326 LtchSttAAAC0B5D 3;
BA_ "GenMsgSendType" BO_ 2365251070 0;
BA_ "GenMsgCycleTime" BO_ 2365251070 100;
BA_ "GenMsgSendType" BO_ 2365250814 0;
BA_ "GenMsgCycleTime" BO_ 2365250814 100;
BA_ "GenMsgSendType" BO_ 2365250558 0;
BA_ "GenMsgCycleTime" BO_ 2365250558 100;
BA_ "GenSigStartValue" SG_ 2365250558 RllrShttrLckAcDA7D0D03 3;
BA_ "GenMsgCycleTime" BO_ 2483019518 100;
BA_ "GenMsgSendType" BO_ 2483019518 0;
BA_ "GenSigStartValue" SG_ 2483019518 HtdGlElmSt72F5090B 3;
BA_ "GenMsgCycleTime" BO_ 2483019262 100;
BA_ "GenMsgSendType" BO_ 2483019262 0;
BA_ "GenSigStartValue" SG_ 2483019262 HtdGlElmSt730E090D 3;
BA_ "GenMsgCycleTime" BO_ 2483019006 100;
BA_ "GenMsgSendType" BO_ 2483019006 0;
BA_ "GenSigStartValue" SG_ 2483019006 HtdGlRq3A5140AF0 3;
BA_ "GenSigStartValue" SG_ 2483019006 HtdGlRq2A4F10AEE 3;
BA_ "GenMsgCycleTime" BO_ 2566575614 100;
BA_ "GenMsgSendType" BO_ 2566575614 0;
BA_ "SendOnChange" BO_ 2566575614 1;
BA_ "GenSigStartValue" SG_ 2566575614 SrvcHtchLtchRq68B515C9 1;
BA_ "GenMsgCycleTime" BO_ 2566575358 100;
BA_ "GenMsgSendType" BO_ 2566575358 0;
BA_ "SendOnChange" BO_ 2566575358 1;
BA_ "GenMsgCycleTime" BO_ 2566575102 200;
BA_ "SendOnChange" BO_ 2566575102 1;
BA_ "GenMsgSendType" BO_ 2566575102 0;
BA_ "GenMsgSendType" BO_ 2566574846 0;
BA_ "GenMsgCycleTime" BO_ 2566574846 1000;
BA_ "GenMsgDelayTime" BO_ 2566574846 100;
BA_ "SendOnChange" BO_ 2566574846 1;
BA_ "GenSigStartValue" SG_ 2566574846 CrgLghtEnblRqsA1B80AE4 3;
BA_ "GenSigStartValue" SG_ 2566574846 LFtwlLgthEnblS6CCD1577 3;
BA_ "SendOnChange" BO_ 2566574590 1;
BA_ "GenMsgDelayTime" BO_ 2566574590 100;
BA_ "GenMsgSendType" BO_ 2566574590 0;
BA_ "GenMsgCycleTime" BO_ 2566574590 1000;
BA_ "GenSigStartValue" SG_ 2566574590 StMtStt82CC09EE 3;
BA_ "GenSigStartValue" SG_ 2566574590 LFtwlLghtEnblC30200EB1 3;
BA_ "GenMsgSendType" BO_ 2566574334 0;
BA_ "GenMsgCycleTime" BO_ 2566574334 1000;
BA_ "GenMsgDelayTime" BO_ 2566574334 100;
BA_ "SendOnChange" BO_ 2566574334 1;
BA_ "GenSigStartValue" SG_ 2566574334 CrgLghtLmp4Stt6D4D157B 3;
BA_ "GenSigStartValue" SG_ 2566574334 CrgLghtLmp3Stt6D161579 3;
BA_ "GenMsgSendType" BO_ 2365250302 0;
BA_ "GenMsgCycleTime" BO_ 2365250302 1000;
BA_ "SendOnChange" BO_ 2365250302 1;
BA_ "GenMsgDelayTime" BO_ 2365250302 10;
BA_ "SigType" SG_ 2365250302 FRONT_IO_1_ECU_CAN2_1_cs 12;
BA_ "SigType" SG_ 2365250302 FRONT_IO_1_ECU_CAN2_1_rc 11;
BA_ "GenMsgSendType" BO_ 2365249534 0;
BA_ "GenMsgCycleTime" BO_ 2365249534 1000;
BA_ "SendOnChange" BO_ 2365249534 1;
BA_ "GenMsgDelayTime" BO_ 2365249534 10;
BA_ "SigType" SG_ 2365249534 REAR_IO_1_ECU_CAN1_2_cs 12;
BA_ "SigType" SG_ 2365249534 REAR_IO_1_ECU_CAN1_2_rc 11;
BA_ "GenMsgSendType" BO_ 2365249790 0;
BA_ "GenMsgCycleTime" BO_ 2365249790 1000;
BA_ "SendOnChange" BO_ 2365249790 1;
BA_ "GenMsgDelayTime" BO_ 2365249790 10;
BA_ "SigType" SG_ 2365249790 FRONT_IO_2_ECU_CAN1_2_cs 12;
BA_ "SigType" SG_ 2365249790 FRONT_IO_2_ECU_CAN1_2_rc 11;
BA_ "GenMsgSendType" BO_ 2365249278 0;
BA_ "GenMsgCycleTime" BO_ 2365249278 1000;
BA_ "SendOnChange" BO_ 2365249278 1;
BA_ "GenMsgDelayTime" BO_ 2365249278 10;
BA_ "SigType" SG_ 2365249278 REAR_IO_2_ECU_CAN1_1_cs 12;
BA_ "SigType" SG_ 2365249278 REAR_IO_2_ECU_CAN1_1_rc 11;
VAL_ 2637364990 ReqAppSystemPackVersion 0 "Off" 1 "On" 2 "Error" 3 "Not available" ;
VAL_ 2637364990 ReqModuleAlive 0 "Off" 1 "On" 2 "Error" 3 "Not available" ;
VAL_ 2637364990 ReqParamsInfo 0 "Off" 1 "On" 2 "Error" 3 "Not available" ;
VAL_ 2637364990 ReqModuleName 0 "Off" 1 "On" 2 "Error" 3 "Not available" ;
VAL_ 2637364990 ReqHardwareName 0 "Off" 1 "On" 2 "Error" 3 "Not available" ;
VAL_ 2637364990 ReqHardwareInfo 0 "Off" 1 "On" 2 "Error" 3 "Not available" ;
VAL_ 2637364990 ReqBLVersionEx 0 "Off" 1 "On" 2 "Error" 3 "Not available" ;
VAL_ 2637364990 ReqBLVersion 0 "Off" 1 "On" 2 "Error" 3 "Not available" ;
VAL_ 2637364990 ReqBLName 0 "Off" 1 "On" 2 "Error" 3 "Not available" ;
VAL_ 2637364990 ReqAppVersionEx 0 "Off" 1 "On" 2 "Error" 3 "Not available" ;
VAL_ 2637364990 ReqAppVersion 0 "Off" 1 "On" 2 "Error" 3 "Not available" ;
VAL_ 2637364990 ReqAppName 0 "Off" 1 "On" 2 "Error" 3 "Not available" ;
VAL_ 2583174654 WiperState 7 "WPR_NA" 6 "WPR_Error" 5 "WPR_Reserved3" 4 "WPR_Reserved2" 3 "WPR_Reserved1" 2 "WPR_HighSpeed" 1 "WPR_LowSpeed" 0 "WPR_Off" ;
VAL_ 2365552126 AutoHoldFuncEna 3 "NA" 2 "Reserved" 1 "Enabled" 0 "Disabled" ;
VAL_ 2365552126 ServiceBrakeReq 3 "Take_no_action" 2 "Reserved" 1 "On" 0 "Off" ;
VAL_ 2365552126 ParkBrakeReq 3 "Take_no_action" 2 "Reserved" 1 "On" 0 "Off" ;
VAL_ 2365552126 AutoHoldStatus 4 "NotAvailable" 3 "Fault" 2 "Active" 1 "Engaged" 0 "Disabled" ;
VAL_ 2381871102 RearRightPadSt 3 "NA" 2 "Error" 1 "Warn" 0 "Ok" ;
VAL_ 2381871102 RearLeftPadSt 3 "NA" 2 "Error" 1 "Warn" 0 "Ok" ;
VAL_ 2381871102 FrontRightPadSt 3 "NA" 2 "Error" 1 "Warn" 0 "Ok" ;
VAL_ 2381871102 FrontLeftPadSt 3 "NA" 2 "Error" 1 "Warn" 0 "Ok" ;
VAL_ 2382107134 BRK_Regeneration_Allowance 3 "NA" 2 "Error" 1 "Allowed" 0 "NotAllowed" ;
VAL_ 2382107134 BRK_System_Status 7 "NA" 6 "Reserved" 5 "Reserved" 4 "Reserved" 3 "MaxMod" 2 "AddlMod" 1 "DrvrBrkDmd" 0 "NoBrkDmd" ;
VAL_ 2382107134 BRK_ABS_Speed_State 3 "Reserved" 2 "Error" 1 "OK" 0 "NA" ;
VAL_ 2382107134 BRK_Brake_Pedal_State 3 "NA" 2 "Error" 1 "Pressed" 0 "NotPressed" ;
VAL_ 2382107134 BRK_Epb_State 7 "NA" 6 "Error" 5 "Reserved" 4 "Reserved" 3 "Unlocked" 2 "Locked" 1 "Unlocking" 0 "Locking" ;
VAL_ 2382107134 BRK_ReadyToDrive 3 "NA" 2 "RESERVED" 1 "READY" 0 "NOT_READY" ;
VAL_ 2381844570 BrkEmergBrkAcv 3 "Not Available" 2 "Error" 1 "On" 0 "Off" ;
VAL_ 2381844570 NetReadyToSleep 3 "NA" 2 "Error" 0 "Inhibit Ready To Sleep" 1 "Ready To Sleep" ;
VAL_ 2381844570 BrkLiquidLevelValue 1 "UNSUFFICIENT" 0 "SUFFICIENT" ;
VAL_ 2381844570 BrkAmberTelltaleReq 3 "Not Available" 2 "Error" 1 "On" 0 "Off" ;
VAL_ 2381844570 BrkESPOffTelltaleReq 3 "Not Available" 2 "Error" 1 "On" 0 "Off" ;
VAL_ 2381844570 BrkESPTelltaleReq 3 "Not Available" 2 "Error" 1 "On" 0 "Off" ;
VAL_ 2381844570 BrkYellowTelltaleReq 3 "Not Available" 2 "Error" 1 "On" 0 "Off" ;
VAL_ 2381844570 BrkRedTelltaleReq 3 "Not Available" 2 "Error" 1 "On" 0 "Off" ;
VAL_ 2381844570 BrkABSTelltaleReq 3 "Not Available" 2 "Error" 1 "On" 0 "Off" ;
VAL_ 2650747415 HmiNonSafetyState 3 "NA" 2 "ERROR" 1 "OK" 0 "NOK" ;
VAL_ 2650747415 HmiSafetyState 3 "NA" 2 "ERROR" 1 "OK" 0 "NOK" ;
VAL_ 2650747415 NetToSleepReady 1 "TRUE" 0 "FALSE" ;
VAL_ 2650747415 actualHMIState 14 "Error" 5 "InHibernation" 9 "SafetyReady" 7 "SafetyFail" 8 "Maintenance" 4 "SoftSleepMode" 1 "PoweringUp" 15 "NotAvailable" 6 "NonSafetyFault" 3 "FullyOperable" 2 "BootingUp" 0 "PowerOff" ;
VAL_ 2566899735 ChargingACPortCommand 3 "Unknown" 2 "Reserved" 1 "Pressed" 0 "Released" ;
VAL_ 2566899735 ChargingACDCPortCommand 3 "Unknown" 2 "Reserved" 1 "Pressed" 0 "Released" ;
VAL_ 2566899735 AccMode 7 "NA" 4 "accMode4" 3 "accMode3" 2 "accMode2" 1 "accMode1" ;
VAL_ 2566899735 MapRecuperTorqChoice 0 "NA" 3 "Map3" 2 "Map2" 1 "Map1" ;
VAL_ 2566899735 ChargingCommand 3 "Reserve" 2 "Stop charging" 1 "Immediate charging required" 0 "No request" ;
VAL_ 2566899735 AutoHoldDisable 3 "NotAvailable" 2 "Fault" 1 "Enabled" 0 "Disabled" ;
VAL_ 2566899735 DisplayUserInformation 3 "Not Available" 2 "Reserved" 1 "OK" 0 "NOK" ;
VAL_ 2566899735 IsMinTorqueReq 3 "Not available" 2 "Error" 1 "On" 0 "Off" ;
VAL_ 2566803454 TrailerVDCActive 3 "Not availble or not installed" 2 "Reserved" 1 "VDC active" 0 "VDC passive" ;
VAL_ 2566803454 YCBrakeCtrlActive 3 "Don't care/Take no action" 2 "Reserved" 1 "YC brake control active" 0 "YC brake control passive but installed" ;
VAL_ 2566803454 YCEngCtrlActive 3 "Don't care/Take no action" 2 "Reserved" 1 "YC engine control active" 0 "YC engine control passive but installed" ;
VAL_ 2566803454 ROPBrakeCtrlActive 3 "Don't care/Take no action" 2 "Reserved" 1 "ROP brake control active" 0 "ROP brake control passive but installed" ;
VAL_ 2566803454 ROPEngCtrlActive 3 "Don't care/Take no action" 2 "Reserved" 1 "ROP engine control active" 0 "ROP engine control passive but installed" ;
VAL_ 2566803454 VDCBrakeLightRq 3 "Don't care/Take no action" 2 "Reserved" 1 "Turn brake light on" 0 "Turn brake light not on" ;
VAL_ 2566803454 VDCFullyOperational 3 "Don't care/Take no action" 2 "Reserved" 1 "Fully operational" 0 "Not fully operational" ;
VAL_ 2566803454 VDCInformationSignal 3 "Don't care/Take no action" 2 "Reserved" 1 "On" 0 "Off" ;
VAL_ 2399125758 LVUpdateOTARequest 7 "NA" 6 "Error" 2 "RequestedConverterAny" 1 "RequestedConverterIdle" 0 "NotRequested" ;
VAL_ 2399125758 OTAUpdateRequest 4 "InvAwake" 3 "Awake" 2 "FullySleep" 1 "Maintenance" 0 "Default" ;
VAL_ 2399125758 DiagnosticRequest 4 "InvAwake" 3 "Awake" 2 "FullySleep" 1 "Maintenance" 0 "Default" ;
VAL_ 2381722110 ELSReadyToSleep 3 "Not Available" 2 "Fault" 1 "Ready" 0 "Not Ready" ;
VAL_ 2381722110 LampState 7 "Not Available" 3 "No Command" 2 "Fault Detected" 1 "Activated" 0 "De activated" ;
VAL_ 2600457470 NM_MNGR_VSMNtwkReq 3 "TAKENOACTION_NM_DBG" 2 "RESERVED_NM_DBG" 1 "ON_NM_DBG" 0 "OFF_NM_DBG" ;
VAL_ 2600457982 NM_DBG_VSMSubstate 4 "SUBSTATE4_NM_DBG" 3 "SUBSTATE3_NM_DBG" 2 "SUBSTATE2_NM_DBG" 1 "SUBSTATE1_NM_DBG" 0 "DEFAULT_NM_DBG" ;
VAL_ 2600457982 NM_DBG_VSMState 7 "NA_NM_DBG" 5 "LONGTERM PARK_NM_DBG" 4 "MAINTENANCE_NM_DBG" 3 "CHARGING_NM_DBG" 2 "READY_NM_DBG" 1 "AWAKE_NM_DBG" 0 "SLEEP_NM_DBG" ;
VAL_ 2650742782 DiagReportsEnabled 0 "Off" 1 "On" 2 "Error" 3 "Not available" ;
VAL_ 2650742782 FirmwareUpdateEnabled 0 "Off" 1 "On" 2 "Error" 3 "Not available" ;
VAL_ 2180407550 GearBox_FltSts 3 "NA_GBFltSts" 2 "CriticalGBFaultSts" 1 "MinorGBFaultSts" 0 "NoGBFaultSts" ;
VAL_ 2180407550 DTS_DriverWarn 7 "NA_DrvrWarn" 4 "CriticalDrivetrainFault_Latched" 3 "CriticalDrivetrainFault" 2 "MajorDrivetrainFault" 1 "MinorDrivetrainFault" 0 "NoDrivetrainFault" ;
VAL_ 2381867518 DTReadyToDrive 3 "NA" 2 "Error" 0 "Not Ready" 1 "Ready" ;
VAL_ 2381971966 DTS_Standstill 3 "NA" 2 "RESERVE" 1 "MOVING" 0 "STANDSTILL" ;
VAL_ 2381971966 DT_ReadyToSleep 3 "NA" 2 "RESERVED" 1 "READY" 0 "NOT_READY" ;
VAL_ 2381971966 DTS_AccrPedlSw 3 "Not available" 2 "Error" 1 "Pedal Depressed" 0 "Pedal Released" ;
VAL_ 2381971966 DTS_BrkPedlSw 3 "Not available" 2 "Error" 1 "Pedal Depressed" 0 "Pedal Released" ;
VAL_ 2381971966 DTS_VehMoveDir 3 "NA" 2 "REVERSE" 1 "FORWARD" 0 "STANDSTILL" ;
VAL_ 2381971966 DTS_ReadyToSleep 3 "NA" 2 "RESERVED" 1 "READY" 0 "NOT_READY" ;
VAL_ 2381971966 DTS_SystemStatus 3 "Not available" 2 "Error" 1 "On" 0 "Off" ;
VAL_ 2381971966 DTS_ReadyToDrive 3 "NA" 2 "RESERVED" 1 "READY" 0 "NOT_READY" ;
VAL_ 2381971966 DTS_IgnitionStatus 3 "NA" 2 "RESERVED" 1 "ON" 0 "OFF" ;
VAL_ 2381972222 DTS_Stalk_Request 3 "NA" 2 "Error" 1 "Active" 0 "NotActive" ;
VAL_ 2381972222 DTS_P_Button 3 "NA" 2 "Error" 1 "Pressed" 0 "NotPressed" ;
VAL_ 2381972222 DTS_Stalk_GS_Input 6 "NA" 5 "ParkReverse" 4 "Reverse" 3 "ParkDrive" 2 "Drive" 1 "Neutral" 0 "Park" ;
VAL_ 2381972222 DTS_GS_Human_RND_Input 4 "NA" 3 "Error" 2 "Reverse" 1 "Drive" 0 "Neutral" ;
VAL_ 2381972222 DTS_GS_Human_P_Input 3 "NA" 2 "Error" 1 "Park" 0 "Neutral" ;
VAL_ 2381972222 DTS_IDU_DirectionSt 3 "NA" 2 "REVERSE" 1 "FORWARD" 0 "STANDBY" ;
VAL_ 2381972222 DTS_IDU_DirectionCmd 3 "NA" 2 "REVERSE" 1 "FORWARD" 0 "NO_ACTION" ;
VAL_ 2381972222 DTS_IDU_InterlockCmd 3 "NA" 2 "ENGAGE" 1 "DISENGAGE" 0 "NO_ACTION" ;
VAL_ 2381972222 DTS_ParkBrakeCmd 3 "NA" 2 "ENGAGE" 1 "DISENGAGE" 0 "NO_ACTION" ;
VAL_ 2381972222 DTS_ParkBrakeSt 7 "NA" 6 "FAULT" 5 "CHANGE IN PROGRESS" 4 "DISENGAGED" 3 "DISENGAGING" 2 "ENGAGED" 1 "ENGAGING" 0 "INIT" ;
VAL_ 2381972222 DTS_IDU_InterlockSt 7 "NA" 6 "FAULT" 5 "CHANGE IN PROGRESS" 4 "DISENGAGED" 3 "DISENGAGING" 2 "ENGAGED" 1 "ENGAGING" 0 "INIT" ;
VAL_ 2381972222 DTS_IDU_CommStatus 1 "Ok" 0 "Error" ;
VAL_ 2381972222 DTS_IDU_ShortCirc 3 "NA" 2 "Error" 1 "Short Circuit" 0 "OK" ;
VAL_ 2381972222 DTS_SysSt_ParkLock 3 "NA" 2 "ERROR" 1 "READY" 0 "NOT_READY" ;
VAL_ 2381972222 DTS_SysSt_IDU 3 "NA" 2 "ERROR" 1 "READY" 0 "NOT_READY" ;
VAL_ 2180407294 DistrTrqMntrFltSts 3 "DistrTrqNotAvailable" 2 "CriticalDistrTrqMntrFault" 1 "MajorDistrTrqMntrFault" 0 "NoDistrTrqMntrFault" ;
VAL_ 2180407294 ActTrqMntrFltSts 3 "ActTrqNotAvailable" 2 "CriticalActTrqMntrFault" 1 "MajorActTrqMntrFault" 0 "NoActTrqMntrFault" ;
VAL_ 2180407294 DemTrqMntrFltSts 3 "DemTrqNotAvailable" 2 "CriticalDemTrqMntrFault" 1 "MajorDemTrqMntrFault" 0 "NoDemTrqMntrFault" ;
VAL_ 2180407294 AITrqReqFltSts 3 "AITrqNotAvailable" 2 "CriticalAITrqReqFault" 1 "MajorAITrqReqFault" 0 "NoAITrqReqFault" ;
VAL_ 2180407294 BrkTrqReqFltSts 3 "BrkTrqNotAvailable" 2 "CriticalBrkTrqReqFault" 1 "MajorBrkTrqReqFault" 0 "NoBrkTrqReqFault" ;
VAL_ 2180407294 BrakePedalFltSts 1 "BrakePedalFault" 0 "NoBrakePedalFault" ;
VAL_ 2180407294 ExternalFltSts 3 "CriticalExternalFault" 2 "MajorExternalFault" 1 "MinorExternalFault" 0 "NoExternalFault" ;
VAL_ 2180407294 AccPedalFltSts 3 "AccNotAvailable" 2 "CriticalAccPedalFault" 1 "MajorAccPedalFault" 0 "NoAccPedalFault" ;
VAL_ 2600438270 DT_GearBox_fault_st 0 "NoFault" 1 "MinorFault" 2 "CriticalFault" 3 "NoAvailable" ;
VAL_ 2600438270 DT_system_warn_st 0 "NoFault" 1 "MinorFault" 2 "MajorFault" 3 "CriticalFault" 4 "CriticalLatched" 7 "NotAvailable" ;
VAL_ 2381399806 RSPDL_Limit_Source 7 "Reverse Limit" 6 "Limp Mode Limit" 5 "ADAS Limit" 4 "HMI Limit" 3 "Safety Limit" 2 "Critical Motor Speed Limit" 1 "Overrided by the parameter" 0 "No Limit" ;
VAL_ 2382314750 MVLCK_SEL_PBKReq 5 "Take_no_action" 4 "Change_in_Progress" 3 "Error" 2 "N_A" 1 "Unlocked" 0 "Locked" ;
VAL_ 2382314750 MVLCK_SEL_GBIntlckReq 5 "Take_no_action" 4 "Change_in_Progress" 3 "Error" 2 "N_A" 1 "Unlocked" 0 "Locked" ;
VAL_ 2382314750 APP_GS_MvLckReq 3 "NotDefined" 2 "Take_no_action" 1 "Unlocked" 0 "Locked" ;
VAL_ 2382314750 APP_GS_InvDirReq 1 "MoveBwd" 0 "MoveFwd" ;
VAL_ 2382314750 Stalk_GS_Req 16 "comGS_Reverse_NoAction" 15 "comGS_Neutral_NoAction" 14 "comGS_Drive_NoAction" 13 "comGS_Error" 12 "comGS_N_A" 11 "comGS_Change_in_Progress" 10 "comGS_Reverse_PErr" 9 "comGS_Drive_PErr" 8 "comGS_Neutral_PErr" 7 "comGS_Park_DT_Err" 6 "comGS_DT_Err" 5 "comGS_ParkReverse" 4 "comGS_ParkDrive" 3 "comGS_Reverse" 2 "comGS_Drive" 1 "comGS_Neutral" 0 "comGS_Park" ;
VAL_ 2382314750 MVLCK_SEL_State 5 "Take_no_action" 4 "Change_in_Progress" 3 "Error" 2 "N_A" 1 "Unlocked" 0 "Locked" ;
VAL_ 2382314750 EXHAN_FinalGSReq 16 "comGS_Reverse_NoAction" 15 "comGS_Neutral_NoAction" 14 "comGS_Drive_NoAction" 13 "comGS_Error" 12 "comGS_N_A" 11 "comGS_Change_in_Progress" 10 "comGS_Reverse_PErr" 9 "comGS_Drive_PErr" 8 "comGS_Neutral_PErr" 7 "comGS_Park_DT_Err" 6 "comGS_DT_Err" 5 "comGS_ParkReverse" 4 "comGS_ParkDrive" 3 "comGS_Reverse" 2 "comGS_Drive" 1 "comGS_Neutral" 0 "comGS_Park" ;
VAL_ 2382314750 MVLCK_SEL_PBKState 5 "Take_no_action" 4 "Change_in_Progress" 3 "Error" 2 "N_A" 1 "Unlocked" 0 "Locked" ;
VAL_ 2382314750 EXHAN_VSMGSReq 16 "comGS_Reverse_NoAction" 15 "comGS_Neutral_NoAction" 14 "comGS_Drive_NoAction" 13 "comGS_Error" 12 "comGS_N_A" 11 "comGS_Change_in_Progress" 10 "comGS_Reverse_PErr" 9 "comGS_Drive_PErr" 8 "comGS_Neutral_PErr" 7 "comGS_Park_DT_Err" 6 "comGS_DT_Err" 5 "comGS_ParkReverse" 4 "comGS_ParkDrive" 3 "comGS_Reverse" 2 "comGS_Drive" 1 "comGS_Neutral" 0 "comGS_Park" ;
VAL_ 2382314750 EXHAN_ChsnGSReq 16 "comGS_Reverse_NoAction" 15 "comGS_Neutral_NoAction" 14 "comGS_Drive_NoAction" 13 "comGS_Error" 12 "comGS_N_A" 11 "comGS_Change_in_Progress" 10 "comGS_Reverse_PErr" 9 "comGS_Drive_PErr" 8 "comGS_Neutral_PErr" 7 "comGS_Park_DT_Err" 6 "comGS_DT_Err" 5 "comGS_ParkReverse" 4 "comGS_ParkDrive" 3 "comGS_Reverse" 2 "comGS_Drive" 1 "comGS_Neutral" 0 "comGS_Park" ;
VAL_ 2382315006 REQ_GS_Inhibits 9 "NA" 8 "Error" 7 "PRNDInhibitDrvrPres" 6 "PBrakeInhib" 5 "PSpeedInhib" 4 "NBrakeInhib" 3 "RDBrakeInhib" 2 "RDAccPedInhib" 1 "RDNrdAccInhib" 0 "NoNotification" ;
VAL_ 2382315006 MVLCK_SEL_InterlockState 5 "Disabled" 4 "Change_in_Progress" 3 "Error" 2 "N_A" 1 "Unlocked" 0 "Locked" ;
VAL_ 2382315006 VSM_Adp_AutoPark 6 "NA" 5 "DriverNotReady" 4 "Immo" 3 "DoorEvent" 2 "DoorConst" 1 "ChrgPlug" 0 "NoVSMNotif" ;
VAL_ 2382315006 VSM_Adp_Inhibits 15 "NA" 14 "NVSMInhib" 13 "NDriverNotReadyAutoParkInhib" 12 "NImmoAutoParkInhib" 11 "NDoorAutoParkInhib" 10 "NChrgPlugAutoParkInhib" 9 "RDVSMInhib" 8 "RDDriverNotReadyAutoParkInhib" 7 "RDImmoAutoParkInhib" 6 "RDDoorAutoParkInhib" 5 "RDChrgPlugAutoParkInhib" 4 "RDSpeedInhib" 3 "RDChargInhib" 2 "RDRampInhib" 1 "RDDoorInhib" 0 "NoVSMNotif" ;
VAL_ 2382315006 Stalk_GS_RND_proc 16 "comGS_Reverse_NoAction" 15 "comGS_Neutral_NoAction" 14 "comGS_Drive_NoAction" 13 "comGS_Error" 12 "comGS_N_A" 11 "comGS_Change_in_Progress" 10 "comGS_Reverse_PErr" 9 "comGS_Drive_PErr" 8 "comGS_Neutral_PErr" 7 "comGS_Park_DT_Err" 6 "comGS_DT_Err" 5 "comGS_ParkReverse" 4 "comGS_ParkDrive" 3 "comGS_Reverse" 2 "comGS_Drive" 1 "comGS_Neutral" 0 "comGS_Park" ;
VAL_ 2382315006 Stalk_GS_proc 16 "comGS_Reverse_NoAction" 15 "comGS_Neutral_NoAction" 14 "comGS_Drive_NoAction" 13 "comGS_Error" 12 "comGS_N_A" 11 "comGS_Change_in_Progress" 10 "comGS_Reverse_PErr" 9 "comGS_Drive_PErr" 8 "comGS_Neutral_PErr" 7 "comGS_Park_DT_Err" 6 "comGS_DT_Err" 5 "comGS_ParkReverse" 4 "comGS_ParkDrive" 3 "comGS_Reverse" 2 "comGS_Drive" 1 "comGS_Neutral" 0 "comGS_Park" ;
VAL_ 2382315006 Stalk_GS_P_proc 16 "comGS_Reverse_NoAction" 15 "comGS_Neutral_NoAction" 14 "comGS_Drive_NoAction" 13 "comGS_Error" 12 "comGS_N_A" 11 "comGS_Change_in_Progress" 10 "comGS_Reverse_PErr" 9 "comGS_Drive_PErr" 8 "comGS_Neutral_PErr" 7 "comGS_Park_DT_Err" 6 "comGS_DT_Err" 5 "comGS_ParkReverse" 4 "comGS_ParkDrive" 3 "comGS_Reverse" 2 "comGS_Drive" 1 "comGS_Neutral" 0 "comGS_Park" ;
VAL_ 2382315006 FLTMNG_ParkBrake_Cmd 0 "va_Off" 1 "va_On" 2 "va_Reserved" 3 "va_Take_no_action" ;
VAL_ 2382315006 FLTMNG_Interlock_Cmd 0 "va_Off" 1 "va_On" 2 "va_Reserved" 3 "va_Take_no_action" ;
VAL_ 2382315006 FLTMNG_DT_StateCmd 0 "va_Off" 1 "va_On" 2 "va_Reserved" 3 "va_Take_no_action" ;
VAL_ 2382315006 FLTMNG_NRDFaultStatus 7 "NA" 6 "reserved5" 5 "reserved4" 4 "reserved3" 3 "reserved2" 2 "reserved1" 1 "FAULTMNGR_GS_NRD_Fault" 0 "FAULTMNGR_GS_NRD_NoFault" ;
VAL_ 2382315006 FLTMNG_LockFaultStatus 7 "NA" 6 "FAULTMNGR_GS_ML_OutofRange" 5 "FAULTMNGR_GS_ML_GSCommandInvalid" 4 "FAULTMNGR_GS_ML_EPBError" 3 "FAULTMNGR_GS_ML_EPBInvalid" 2 "FAULTMNGR_GS_ML_InterlockError" 1 "FAULTMNGR_GS_ML_InterlockInvalid" 0 "FAULTMNGR_GS_ML_NoFault" ;
VAL_ 2381855998 RiDPadSt 15 "NA" 14 "Error" 13 "Reserved" 12 "Btn5Hld3" 11 "Btn5Hld" 10 "Btn4Hld" 9 "Btn3Hld" 8 "Btn2Hld" 7 "Btn1Hld2" 6 "Btn1Hld" 5 "Btn5Psd" 4 "Btn4Psd" 3 "Btn3Psd" 2 "Btn2Psd" 1 "Btn1Psd" 0 "NoAction" ;
VAL_ 882 VCU_DCDCActivation 3 "Unavaliable Value" 2 "DCDC ON" 1 "DCDC OFF" 0 "Not used" ;
VAL_ 2399123198 DCDC_HVIL_Status 0 "Init" 1 "Ok" 2 "Fault" 3 "NA" ;
VAL_ 2314626046 VehPitchAngleFigureOfMerit 3 "Vehicle Pitch Angle Not Available" 2 "Vehicle Pitch Angle Error" 1 "Vehicle Pitch Angle degraded" 0 "Vehicle Pitch Angle fully functional" ;
VAL_ 2314626046 VehRideHeightFigureOfMerit 3 "Vehicle Ride Height Not Available" 2 "Vehicle Ride Height Error" 1 "Vehicle Ride Height degraded" 0 "Vehicle Ride Height fully functional" ;
VAL_ 2582780183 CargoLightModeHmiReq 7 "Not Available" 3 "Error" 2 "Auto" 1 "On" 0 "Off" ;
VAL_ 2582781182 CargoLightModeAuto 3 "Not Available" 2 "Error" 1 "True" 0 "False" ;
VAL_ 2582780670 CargoLightStateAct 3 "Not Available" 2 "Error" 1 "On" 0 "Off" ;
VAL_ 2365556990 BsmWarnReqRi 3 "Not Avaialble" 2 "Warning Level 2" 1 "Warning Level 1" 0 "No Warning" ;
VAL_ 2365556990 BsmWarnReqLe 3 "Not Avaialble" 2 "Warning Level 2" 1 "Warning Level 1" 0 "No Warning" ;
VAL_ 2365556990 BsmSt 15 "not available / not installed" 14 "error indication" 13 "reserved for future use" 12 "reserved for future use" 11 "reserved for future use" 10 "reserved for future use" 9 "reserved for future use" 8 "system performance and/or sensitivity limited" 7 "reserved" 6 "collision warning with additional system response" 5 "collision warning active with visual/audio cues" 4 "driver overrides system" 3 "system is ready and activated" 2 "system is deactivated by driver" 1 "system is temporarily not available" 0 "system is not ready" ;
VAL_ 2365557246 BsmWarnLampStRi 3 "Not Available" 2 "Fault Detected" 1 "Activated" 0 "De activated" ;
VAL_ 2365557246 BsmWarnLampStLe 3 "Not Available" 2 "Fault Detected" 1 "Activated" 0 "De activated" ;
VAL_ 2381860350 LeftIndicatorReq 3 "Don_t_Care" 2 "Error" 1 "Activated" 0 "De_activated" ;
VAL_ 2381860350 RightIndicatorReq 3 "Don_t_Care" 2 "Error" 1 "Activated" 0 "De_activated" ;
VAL_ 2583173630 WasherState 3 "WSH_NA" 2 "WSH_Error" 1 "WSH_On" 0 "WSH_Off" ;
VAL_ 2373975806 StateRequest 6 "Failed On Touch" 5 "Failed" 4 "Door Is Closing" 7 "Not Available" 3 "Door Is Opening" 2 "Door Opened" 1 "Active" 0 "Inactive" ;
VAL_ 2381855742 LeDPadSt 15 "NA" 14 "Error" 13 "Reserved" 12 "Btn5Hld3" 11 "Btn5Hld" 10 "Btn4Hld" 9 "Btn3Hld" 8 "Btn2Hld" 7 "Btn1Hld2" 6 "Btn1Hld" 5 "Btn5Psd" 4 "Btn4Psd" 3 "Btn3Psd" 2 "Btn2Psd" 1 "Btn1Psd" 0 "NoAction" ;
VAL_ 2381859582 AutoLowBeamReq 3 "Don't Care" 2 "Reserved" 1 "AutoRequested" 0 "AutoNotRequested" ;
VAL_ 2180924158 CC_ReadyToSleep 3 "NA" 2 "Reserve" 1 "True" 0 "False" ;
VAL_ 2180924158 CC_HealthStatus 7 "Health_NA" 2 "Health_Critical" 1 "Health_Warning" 0 "Health_Normal" ;
VAL_ 2180924158 DC_ChrgContactorState 4 "ChrgContact_SNA" 3 "False Open" 2 "False Close" 1 "Closed" 0 "Open" ;
VAL_ 2180924158 AC_ActualACChargingState 7 "AC_ChState_NA" 4 "AC Critical Charging Fault" 3 "AC Charging Fault" 2 "AC Stop Charging" 1 "AC Charging Active" 0 "AC Standby" ;
VAL_ 2180924158 DC_ActualDCChargingState 7 "DC_ChState_NA" 4 "DC Critical Charging Fault" 3 "DC Charging Fault" 2 "DC Stop Charging" 1 "DC Charging Active" 0 "DC Standby" ;
VAL_ 2180924158 CCI_ActualChargingState 7 "CCIState_NA" 5 "Fault" 4 "Charging Stopped" 3 "DC Charging" 2 "AC Charging" 1 "Standby" 0 "Sleep" ;
VAL_ 2180924158 CCI_ACDCPortPlugType 7 "ACDCPlug_NA" 4 "Failed To Recognise" 3 "DC" 2 "AC" 1 "Detecting" 0 "Not Connected" ;
VAL_ 2180924158 CCI_ACPortPlugType 7 "ACPlug_NA" 3 "Failed To Recognise" 2 "AC" 1 "Detecting" 0 "Not Connected" ;
VAL_ 2381859838 AutoLowBeamSts 3 "Not Available" 2 "Fault Detected" 1 "AutoSelected" 0 "AutoNotSelected" ;
VAL_ 2381860606 HeadLampActualLevel 7 "Not_Available" 6 "Error" 2 "High_level" 1 "Normal_level" 0 "Low_level" ;
VAL_ 2381860606 HeadlampLvlMode 3 "Not_Available" 2 "Error" 1 "Manual_Mode" 0 "Auto_Mode" ;
VAL_ 2582767102 Alarm_Silence_request 3 "Not_Available" 2 "Error" 1 "SilenceRequested" 0 "NoSilenceRequested" ;
VAL_ 2582767102 Tilt_Arm_Disarm 5 "Not_Available" 4 "Error" 3 "Extra1" 2 "Extra0" 1 "Tilt_present_arm" 0 "Tilt_present _disarm" ;
VAL_ 2582767102 USS_Arm_Disarm 3 "Not_Available" 2 "Error" 1 "USS_arm" 0 "USS_disarm" ;
VAL_ 2582767102 MW_Arm_Disarm 5 "Not_Available" 4 "Error" 3 "MW_present_arm" 2 "MW_present_disarm" 1 "MW_not_present" 0 "MW_not_present" ;
VAL_ 2582767102 ACU_arm_disarm 3 "Not_Available" 2 "Error" 1 "ACU_arm" 0 "ACU_disarm" ;
VAL_ 2583175166 WipeArbRequest 7 "WPR_NA" 6 "WPR_Reserved" 5 "WPR_Auto" 4 "WPR_HighSpeed" 3 "WPR_LowSpeed" 2 "WPR_Intermittent" 1 "WPR_SingleStroke" 0 "WPR_TurnOff" ;
VAL_ 2365553406 DPadCruiseControlReq 8 "SetSpeed" 7 "ModeChange" 6 "SlowDownMajor" 5 "SlowDownMinor" 4 "SpeedUpMajor" 3 "SpeedUpMinor" 2 "RequestOff" 1 "RequestOn" 0 "NoAction" ;
VAL_ 2365553406 DpadVoiceAssistReq 3 "NA" 2 "Error" 1 "On" 0 "Off" ;
VAL_ 2365553406 ExtMirrorAdjReqHMI 3 "NA" 2 "Error" 1 "On" 0 "Off" ;
VAL_ 2583047422 MotorReq 6 "Calibration" 7 "Not available" 3 "Close" 2 "Open" 1 "Stop" 0 "Disable" ;
VAL_ 2583047422 MotorStatus 7 "Not available" 6 "Error" 5 "Unknown" 4 "Closing" 3 "Opening" 2 "Intermediate" 1 "Closed" 0 "Open" ;
VAL_ 837 DCDC_Status 7 "invalid" 6 "reserved" 5 "degradation mode" 4 "error mode" 3 "conversion working" 2 "standby mode" 1 "Init mode" 0 "off mode" ;
VAL_ 837 DCDC_Fault 137 "Shortcircuit_Protection" 136 "Output_Overcurrent" 135 "Output_Overvoltage" 134 "Cavity_Overcurrent" 133 "Temp_Sensor_Faullt" 132 "CoolantTemp_tooHigh" 131 "CoolantTemp_tooLow" 130 "BatVolt12V_tooLow" 129 "BatVolt12V_tooHigh" 71 "ROM_Timeout" 70 "RAM_Timeout" 69 "Send_Message_Timeout" 68 "VCU_Node_Loss" 67 "BMS_Node_Loss" 66 "CGW_Node_Loss" 65 "Bus_Off" 192 "InVoltage_OverVoltage" 128 "InVoltage_UnderVoltage" 64 "Abnormal_WakeUp" 0 "No_Fault" ;
VAL_ 837 DCDC_working_State 3 "reserved" 2 "DCDC is standby" 1 "reserved" 0 "DCDC converting" ;
VAL_ 837 DCDC_HighVoltConnectionAllowed 1 "Permit" 0 "Not Permit" ;
VAL_ 837 DCDC_OVERTEMP 1 "OverTempature" 0 "False" ;
VAL_ 2583064318 PassPwrSldDoorFaults 8 "UnknownPosition" 7 "CalibrationFail" 6 "etc" 5 "Undervoltage" 4 "Overvoltage" 3 "Motor Overload" 2 "Movement interrupted" 1 "No Fault" 0 "NA" ;
VAL_ 2583064318 PassPwrSldDoorStatus 7 "Not available" 6 "Error" 5 "Unknown" 4 "Closing" 3 "Opening" 2 "Intermediate" 1 "Closed" 0 "Open" ;
VAL_ 2582780695 RFtwlLightIntensityReq 7 "Not Available" 3 "Error" 2 "Level 3" 1 "Level 2" 0 "Level 1" ;
VAL_ 2582780695 RFtwlLightEnableReq 7 "Not Available" 3 "Error" 2 "Auto" 1 "On" 0 "Off" ;
VAL_ 2582780695 LFtwlLightIntensityReq 7 "Not Available" 3 "Error" 2 "Level 3" 1 "Level 2" 0 "Level 1" ;
VAL_ 2582780695 LFtwlLightEnableReq 7 "Not Available" 3 "Error" 2 "Auto" 1 "On" 0 "Off" ;
VAL_ 2582780695 PassLightIntensityReq 7 "Not Available" 3 "Error" 2 "Level 3" 1 "Level 2" 0 "Level 1" ;
VAL_ 2582780695 DriverLightIntensityReq 7 "Not Available" 3 "Error" 2 "Level 3" 1 "Level 2" 0 "Level 1" ;
VAL_ 2582780695 PassLightEnableReq 7 "Not Available" 3 "Error" 2 "Auto" 1 "On" 0 "Off" ;
VAL_ 2582780695 DriverLightEnableReq 7 "Not Available" 3 "Error" 2 "Auto" 1 "On" 0 "Off" ;
VAL_ 2582780695 VestLightEnaReq 7 "Not Available" 3 "Error" 2 "Auto" 1 "On" 0 "Off" ;
VAL_ 2582780695 IndHaloLightEnaReq 7 "Not Available" 3 "Error" 2 "Auto" 1 "On" 0 "Off" ;
VAL_ 2582780695 CabLightColorReq 3 "Not available" 2 "Reserved" 1 "Warm white" 0 "Cold white" ;
VAL_ 2582780695 CabLightIntensityReq 7 "Not Available" 3 "Error" 2 "Level 3" 1 "Level 2" 0 "Level 1" ;
VAL_ 2582780695 CabLightEnableReq 7 "Not Available" 3 "Error" 2 "Auto" 1 "On" 0 "Off" ;
VAL_ 2582781438 RFtwlLightModeAuto 3 "Not Available" 2 "Error" 1 "True" 0 "False" ;
VAL_ 2582781438 RFtwlLightIntensityState 7 "Not Available" 3 "Error" 2 "Level 3" 1 "Level 2" 0 "Level 1" ;
VAL_ 2582781438 RFtwlLightEnableState 3 "Not Available" 2 "Error" 1 "On" 0 "Off" ;
VAL_ 2582781438 LFtwlLightModeAuto 3 "Not Available" 2 "Error" 1 "True" 0 "False" ;
VAL_ 2582781438 LFtwlLightIntensityState 7 "Not Available" 3 "Error" 2 "Level 3" 1 "Level 2" 0 "Level 1" ;
VAL_ 2582781438 LFtwlLightEnableState 3 "Not Available" 2 "Error" 1 "On" 0 "Off" ;
VAL_ 2582781438 PassLightModeAuto 3 "Not Available" 2 "Error" 1 "True" 0 "False" ;
VAL_ 2582781438 DriverLightModeAuto 3 "Not Available" 2 "Error" 1 "True" 0 "False" ;
VAL_ 2582781438 PassLightIntensityState 7 "Not Available" 3 "Error" 2 "Level 3" 1 "Level 2" 0 "Level 1" ;
VAL_ 2582781438 PassLightEnableState 3 "Not Available" 2 "Error" 1 "On" 0 "Off" ;
VAL_ 2582781438 DriverLightIntensityState 7 "Not Available" 3 "Error" 2 "Level 3" 1 "Level 2" 0 "Level 1" ;
VAL_ 2582781438 DriverLightEnableState 3 "Not Available" 2 "Error" 1 "On" 0 "Off" ;
VAL_ 2582781438 IndLighstIntensityState 7 "Not Available" 3 "Error" 2 "Level 3" 1 "Level 2" 0 "Level 1" ;
VAL_ 2582781438 IndtLightsColorState 3 "Not available" 2 "Reserved" 1 "Warm white" 0 "Cold white" ;
VAL_ 2582781438 SaloonLightsEnableState 3 "Not Available" 2 "Error" 1 "On" 0 "Off" ;
VAL_ 2582781438 VestLightIntensityState 7 "Not Available" 3 "Error" 2 "Level 3" 1 "Level 2" 0 "Level 1" ;
VAL_ 2582781438 VestLightColorState 3 "Not available" 2 "Reserved" 1 "Warm white" 0 "Cold white" ;
VAL_ 2582781438 VestLightEnableState 3 "Not Available" 2 "Error" 1 "On" 0 "Off" ;
VAL_ 2582781438 HaloLighstIntensityState 7 "Not Available" 3 "Error" 2 "Level 3" 1 "Level 2" 0 "Level 1" ;
VAL_ 2582781438 HaloLightsColorState 3 "Not available" 2 "Reserved" 1 "Warm white" 0 "Cold white" ;
VAL_ 2582781438 CabLightModeAuto 3 "Not Available" 2 "Error" 1 "True" 0 "False" ;
VAL_ 2582781438 CabLightColorState 3 "Not available" 2 "Reserved" 1 "Warm white" 0 "Cold white" ;
VAL_ 2582781438 CabLightIntensityState 7 "Not Available" 3 "Error" 2 "Level 3" 1 "Level 2" 0 "Level 1" ;
VAL_ 2582781438 CabLightEnableState 3 "Not Available" 2 "Error" 1 "On" 0 "Off" ;
VAL_ 2381862910 AlarmHornReq 3 "NA" 2 "Error" 1 "Active" 0 "Not Active" ;
VAL_ 2566619134 DCDC_Status 7 "Invalid" 6 "Reserved" 5 "Degradation" 4 "Error" 3 "Conversion" 2 "Standby" 1 "Init" 0 "Off" ;
VAL_ 2566619134 DCDC_Fault 19 "InpVoltage_Overvoltage" 18 "Shortcircuit_Protection" 17 "Output_Overcurrent" 16 "Output_Overvoltage" 15 "Cavity_Overcurrent" 14 "Temp_Sensor_Fault" 13 "CoolantTemp_tooHigh" 12 "CoolantTemp_tooLow" 11 "BatVolt12V_tooLow" 10 "BatVolt12V_tooHigh" 9 "InpVoltage_Undervoltage" 8 "ROM_Timeout" 7 "RAM_Timeout" 6 "Send_Message_Timeout" 5 "VCU_Node_Loss" 4 "BMS_Node_Loss" 3 "CGW_Node_Loss" 2 "Bus_Off" 1 "Abnormal_WakeUp" 0 "No_Fault" ;
VAL_ 2583066110 CentralLockRequest 7 "Not Available" 6 "Error" 5 "Unlock Cargo Side Door" 4 "Unlock Cargo Rear Door" 3 "Unlock Passenger Door" 2 "Unlock Driver Door" 1 "Fully Lock Vehicle" 0 "Unlock Vehicle" ;
VAL_ 2398099454 HVBattThrEventFailState 3 "NA" 2 "Reserved" 1 "Warning" 0 "NoFault" ;
VAL_ 2398099454 HVBattThermalEvent 3 "NA" 2 "Detected" 1 "High_Risk" 0 "Not_Detected" ;
VAL_ 2398099454 HVActiveDischargeRequest 3 "TakeNoAction" 2 "Reserved" 1 "On" 0 "Off" ;
VAL_ 2398099454 HVReadyToDrive 3 "NA" 2 "Error" 1 "Ready" 0 "Not Ready" ;
VAL_ 2398099454 HVBSMActState 7 "HVBSM_NotAvailable" 6 "HVBSM_Error" 5 "HVBSM_Reserved2" 4 "HVBSM_Reserved1" 3 "HVBSM_Fault" 2 "HVBSM_Complete" 1 "HVBSM_InProcess" 0 "HVBSM_Default" ;
VAL_ 2398099454 HVBPCActState 0 "HVBPC_Default" 1 "HVBPC_InProcess" 2 "HVBPC_Complete" 3 "HVBPC_Fault" 4 "HVBPC_Blocked" 5 "HVBPC_Reserved2" 6 "HVBPC_Error" 7 "HVBPC_NotAvailable" ;
VAL_ 2398099454 HVActSysState 0 "HVState_Initializing" 1 "HVState_Off" 2 "HVState_Active" 3 "HVState_Activating" 4 "HVState_ShuttingDown" 5 "HVState_Discharging" 6 "HVState_Fault" 7 "HVState_Service" ;
VAL_ 2398099454 HVInsulState 0 "HVInsul_Init" 1 "HVInsul_Ok" 2 "HVInsul_Warn" 3 "HVInsul_Crit" ;
VAL_ 2398099454 HVIntgrState 0 "HVIntgr_Init" 1 "HVIntgr_Ok" 2 "HVIntgr_Fault" 3 "HVIntgr_NA" ;
VAL_ 2398099454 HVCommState 0 "HVComm_Init" 1 "HVComm_Ok" 2 "HVComm_Fault" 3 "HVComm_NA" ;
VAL_ 2381724158 CabinRecirculationRequest 7 "NA" 6 "Error" 2 "Auto" 1 "FullRecirc" 0 "Fresh" ;
VAL_ 2381724158 OutletSelectionRequest 15 "NA" 14 "Error" 8 "Auto" 6 "Windscreen/Front" 7 "Windscreen/Front/Floor" 5 "Windscreen/Floor" 4 "Front/Floor" 3 "Floor" 2 "Front" 1 "Windscreen" 0 "Off" ;
VAL_ 2448508414 RideHeightFigureOfMerit_RR 3 "Ride Height Not Available" 2 "Ride Height Error" 1 "Ride Height degraded" 0 "Ride Height fully functional" ;
VAL_ 2448508414 RideHeightFigureOfMerit_RL 3 "Ride Height Not Available" 2 "Ride Height Error" 1 "Ride Height degraded" 0 "Ride Height fully functional" ;
VAL_ 2448508414 RideHeightFigureOfMerit_FR 3 "Ride Height Not Available" 2 "Ride Height Error" 1 "Ride Height degraded" 0 "Ride Height fully functional" ;
VAL_ 2448508414 RideHeightFigureOfMerit_FL 3 "Ride Height Not Available" 2 "Ride Height Error" 1 "Ride Height degraded" 0 "Ride Height fully functional" ;
VAL_ 2381912087 ODM_FreezeFrame_Event 1 "Last security event" 0 "First security event" ;
VAL_ 2566867200 ODO_DBG_SecStor_LastUptime_s 2 "ODM_FLASH_ERR" 1 "ODM_FLASH_OK" 0 "ODM_FLASH_NA" ;
VAL_ 2566865918 ODO_FaultStatus 3 "Reserved" 2 "NA" 1 "Fault" 0 "NoFault" ;
VAL_ 2566866430 OdoDTCFrameSelr 1 "The last security event request" 0 "The first security event request" ;
VAL_ 2566866430 OdometerRoutineRequestToHMI 7 "NA" 6 "Reserved" 5 "ResetBackupODM_Storage " 4 "ClearNotActiveODM_DTC " 3 "ReadOdometerDTC" 2 "WriteDCUOdometerValueToHMI" 1 "RetrieveOdometerBackupValue" 0 "NoRequest" ;
VAL_ 2365251326 LtchSttAAAC0B5D 3 "Not Available" 2 "Error" 1 "Lock" 0 "Unlock" ;
VAL_ 2365251070 BlkhdDrLtchRq79F31101 3 "Not Available" 2 "DoubleLock" 1 "Unlatch" 0 "Inactive" ;
VAL_ 2365251070 PssDrLtchRqC65112B3 3 "Not Available" 2 "DoubleLock" 1 "Unlatch" 0 "Inactive" ;
VAL_ 2365251070 DrvrDrLtchRq149F144F 3 "Not Available" 2 "DoubleLock" 1 "Unlatch" 0 "Inactive" ;
VAL_ 2365250814 DrOpnStt498019DA 7 "Not Available" 6 "Error" 2 "Closed" 1 "Ajared" 0 "Opened" ;
VAL_ 2365250814 SnsdPwrDrStt36820F97 7 "Not available" 6 "Error" 5 "Unknown" 4 "Closing" 3 "Opening" 2 "Intermediate" 1 "Closed" 0 "Open" ;
VAL_ 2365250558 RllrShttrLckAcDA7D0D03 3 "Not Available" 2 "Error" 1 "Lock" 0 "Unlock" ;
VAL_ 2483019518 HtdGlElmSt72F5090B 3 "Not Available" 2 "Error" 1 "On" 0 "Off" ;
VAL_ 2483019262 HtdGlElmSt730E090D 3 "Not Available" 2 "Error" 1 "On" 0 "Off" ;
VAL_ 2483019006 HtdGlRq3A5140AF0 3 "Not Available" 2 "Error" 1 "On" 0 "Off" ;
VAL_ 2483019006 HtdGlRq2A4F10AEE 3 "Not Available" 2 "Error" 1 "On" 0 "Off" ;
VAL_ 2566575614 SrvcHtchLtchRq68B515C9 3 "Not Available" 2 "Error" 1 "Lock" 0 "Unlock" ;
VAL_ 2566575358 SnsdSrvcHtchStB1020BA1 7 "Not Available" 6 "Error" 2 "Closed" 1 "Ajared" 0 "Opened" ;
VAL_ 2566575102 WshrCmd667308B4 1 "WSH_TurnOn" 0 "WSH_TurnOff" ;
VAL_ 2566574846 CrgLghtEnblRqsA1B80AE4 3 "Not Available" 2 "Error" 1 "On" 0 "Off" ;
VAL_ 2566574846 LFtwlLgthEnblS6CCD1577 3 "Not Available" 2 "Error" 1 "On" 0 "Off" ;
VAL_ 2566574590 StMtStt82CC09EE 3 "NA" 2 "Error" 1 "Occpd" 0 "Free" ;
VAL_ 2566574590 LFtwlLghtEnblC30200EB1 3 "Not Available" 2 "Error" 1 "On" 0 "Off" ;
VAL_ 2566574334 CrgLghtLmp4Stt6D4D157B 3 "Not Available" 2 "Error" 1 "On" 0 "Off" ;
VAL_ 2566574334 CrgLghtLmp3Stt6D161579 3 "Not Available" 2 "Error" 1 "On" 0 "Off" ;
VAL_ 2365250302 IllmntnRqA6700B0C 3 "Don't Care" 2 "Dim" 1 "Activate" 0 "De activate" ;
VAL_ 2365250302 RIndcrCmd717E08AE 3 "Don't Care" 2 "Dim" 1 "Activate" 0 "De activate" ;
VAL_ 2365250302 LIndcrCmd711E08A4 3 "Don't Care" 2 "Dim" 1 "Activate" 0 "De activate" ;
VAL_ 2365250302 RrLftPsCmd92290A19 3 "Don't Care" 2 "Dim" 1 "Activate" 0 "De activate" ;
VAL_ 2365250302 RrRghtPsCmd9D3B0A8C 3 "Don't Care" 2 "Dim" 1 "Activate" 0 "De activate" ;
VAL_ 2365250302 FrntRghtPsCmdA9860B0B 3 "Don't Care" 2 "Dim" 1 "Activate" 0 "De activate" ;
VAL_ 2365250302 DRLCmdFL59140746 3 "Don't Care" 2 "Dim" 1 "Activate" 0 "De activate" ;
VAL_ 2365250302 RrFgLmpCmd91870A02 3 "Don't Care" 2 "Dim" 1 "Activate" 0 "De activate" ;
VAL_ 2365250302 RrPsCmd6C28088E 3 "Don't Care" 2 "Dim" 1 "Activate" 0 "De activate" ;
VAL_ 2365250302 RrRgPltCmd9C620A70 3 "Don't Care" 2 "Dim" 1 "Activate" 0 "De activate" ;
VAL_ 2365250302 DppdBmCmd87A6099D 3 "Don't Care" 2 "Dim" 1 "Activate" 0 "De activate" ;
VAL_ 2365250302 MnBmCmd742708CC 3 "Don't Care" 2 "Dim" 1 "Activate" 0 "De activate" ;
VAL_ 2365249534 LmpSttCFDA0C1D 7 "Not Available" 3 "No Command" 2 "Fault Detected" 1 "Activated" 0 "De activated" ;
VAL_ 2365249534 LmpSttE99F0CF0 7 "Not Available" 3 "No Command" 2 "Fault Detected" 1 "Activated" 0 "De activated" ;
VAL_ 2365249534 LmpSttF7400D55 7 "Not Available" 3 "No Command" 2 "Fault Detected" 1 "Activated" 0 "De activated" ;
VAL_ 2365249790 DppdBmStt18C70E0C 7 "Not Available" 3 "No Command" 2 "Fault Detected" 1 "Activated" 0 "De activated" ;
VAL_ 2365249790 MnBmSttFC930D3B 7 "Not Available" 3 "No Command" 2 "Fault Detected" 1 "Activated" 0 "De activated" ;
VAL_ 2365249790 LmpStt04630DB4 7 "Not Available" 3 "No Command" 2 "Fault Detected" 1 "Activated" 0 "De activated" ;
VAL_ 2365249790 LmpStt06180DC9 7 "Not Available" 3 "No Command" 2 "Fault Detected" 1 "Activated" 0 "De activated" ;
VAL_ 2365249790 LmpStt06BE0DD3 7 "Not Available" 3 "No Command" 2 "Fault Detected" 1 "Activated" 0 "De activated" ;
VAL_ 2365249790 LmpStt12DB0E1C 7 "Not Available" 3 "No Command" 2 "Fault Detected" 1 "Activated" 0 "De activated" ;
VAL_ 2365249790 LmpStt15420E38 7 "Not Available" 3 "No Command" 2 "Fault Detected" 1 "Activated" 0 "De activated" ;
VAL_ 2365249278 UdsRgnPltLmpCmEE080D3E 3 "Don't Care" 2 "Dim" 1 "Activate" 0 "De activate" ;
VAL_ 2365249278 UdsBrkLmpCmdA3950ADB 3 "Don't Care" 2 "Dim" 1 "Activate" 0 "De activate" ;
VAL_ 2365249278 RghtLmpCmmndA5C80AE9 3 "Don't Care" 2 "Dim" 1 "Activate" 0 "De activate" ;
VAL_ 2365249278 UdsRrPsLmpCmdD3CD0C78 3 "Don't Care" 2 "Dim" 1 "Activate" 0 "De activate" ;
VAL_ 2365249278 UdsDrlLmpCmdA3B10ADE 3 "Don't Care" 2 "Dim" 1 "Activate" 0 "De activate" ;
VAL_ 2365249278 UdsIndcrLmpCmdBAFC0BAC 3 "Don't Care" 2 "Dim" 1 "Activate" 0 "De activate" ;
VAL_ 2365249278 UdsFrntPsLmpCmD4800C88 3 "Don't Care" 2 "Dim" 1 "Activate" 0 "De activate" ;
VAL_ 2365249278 LmpSttE8F90CE6 7 "Not Available" 3 "No Command" 2 "Fault Detected" 1 "Activated" 0 "De activated" ;
VAL_ 2365249278 UdsLwBmLmpCmdD3170C63 3 "Don't Care" 2 "Dim" 1 "Activate" 0 "De activate" ;
VAL_ 2365249278 UdsHBmLmpCmdC52E0BE2 3 "Don't Care" 2 "Dim" 1 "Activate" 0 "De activate" ;
VAL_ 2365249278 LmpSttCF780C16 7 "Not Available" 3 "No Command" 2 "Fault Detected" 1 "Activated" 0 "De activated" ;
VAL_ 2365249278 LmpSttF6900D4B 7 "Not Available" 3 "No Command" 2 "Fault Detected" 1 "Activated" 0 "De activated" ;
